VERSION ""

NS_ :

BS_:

BU_: WRCS SRS LECM1 ECUspare6 CIOM CCM

BO_ 2432663360 CIOM_Cab_05S: 13 CIOM
 SG_ PHTimerGUIEvCmd_Timer1StartDay_I : 32|4@1+ (1,0) [0|0] ""  CCM
 SG_ PHTimerGUIEvCmd_Timer1Recur_ISig : 24|4@1+ (1,0) [0|0] ""  CCM
 SG_ PHTimerGUIEvCmd_Timer1Temp_ISig_ : 8|5@1+ (1,0) [0|0] ""  CCM
 SG_ PHTimerGUIEvCmd_PhTimer3_cmd_ISi : 13|3@1+ (1,0) [0|0] ""  CCM
 SG_ PHTimerGUIEvCmd_Timer2StartDay_I : 36|4@1+ (1,0) [0|0] ""  CCM
 SG_ PHTimerGUIEvCmd_Timer3StartDay_I : 40|4@1+ (1,0) [0|0] ""  CCM
 SG_ PHTimerGUIEvCmd_Timer2Hours_ISig : 48|8@1+ (1,0) [0|255] "h"  CCM
 SG_ PHTimerGUIEvCmd_Timer1Duration_I : 96|7@1+ (1,0) [0|127] "min"  CCM
 SG_ PHTimerGUIEvCmd_Timer3Hours_ISig : 88|8@1+ (1,0) [0|255] "h"  CCM
 SG_ PHTimerGUIEvCmd_PhTimer1_cmd_ISi : 5|3@1+ (1,0) [0|0] ""  CCM
 SG_ PHTimerGUIEvCmd_PhTimer2_cmd_ISi : 21|3@1+ (1,0) [0|0] ""  CCM
 SG_ PHTimerGUIEvCmd_Timer2Recur_ISig : 44|4@1+ (1,0) [0|0] ""  CCM
 SG_ PHTimerGUIEvCmd_Timer3Recur_ISig : 28|4@1+ (1,0) [0|0] ""  CCM
 SG_ PHTimerGUIEvCmd_Timer2Minutes_IS : 72|8@1+ (1,0) [0|255] "min"  CCM
 SG_ PHTimerGUIEvCmd_Timer2Temp_ISig_ : 16|5@1+ (1,0) [0|0] ""  CCM
 SG_ PHTimerGUIEvCmd_Timer1Hours_ISig : 56|8@1+ (1,0) [0|255] "h"  CCM
 SG_ PHTimerGUIEvCmd_Timer3Temp_ISig_ : 0|5@1+ (1,0) [0|0] ""  CCM
 SG_ PHTimerGUIEvCmd_Timer3Minutes_IS : 64|8@1+ (1,0) [0|255] "min"  CCM
 SG_ PHTimerGUIEvCmd_Timer1Minutes_IS : 80|8@1+ (1,0) [0|255] "min"  CCM

BO_ 2432663361 CIOM_Cab_05P_FCM: 8 CCM
 SG_ CIOM_Cab_05P_FCS : 0|64@1+ (1,0) [0|1] ""  CIOM

BO_ 2432657472 CIOM_Cab_04S: 11 CIOM
 SG_ EngTimerGUIEvCmd_Timer3Hours_ISi : 56|8@1+ (1,0) [0|255] "h"  CCM
 SG_ EngTimerGUIEvCmd_EhTimer3_cmd_IS : 24|3@1+ (1,0) [0|0] ""  CCM
 SG_ EngTimerGUIEvCmd_Timer2Recur_ISi : 12|4@1+ (1,0) [0|0] ""  CCM
 SG_ EngTimerGUIEvCmd_EhTimer1_cmd_IS : 32|3@1+ (1,0) [0|0] ""  CCM
 SG_ EngTimerGUIEvCmd_Timer1StartDay_ : 4|4@1+ (1,0) [0|0] ""  CCM
 SG_ EngTimerGUIEvCmd_Timer3Recur_ISi : 8|4@1+ (1,0) [0|0] ""  CCM
 SG_ EngTimerGUIEvCmd_Timer2Hours_ISi : 80|8@1+ (1,0) [0|255] "h"  CCM
 SG_ EngTimerGUIEvCmd_Timer2StartDay_ : 16|4@1+ (1,0) [0|0] ""  CCM
 SG_ EngTimerGUIEvCmd_Timer1Minutes_I : 72|8@1+ (1,0) [0|255] "min"  CCM
 SG_ EngTimerGUIEvCmd_Timer1Hours_ISi : 48|8@1+ (1,0) [0|255] "h"  CCM
 SG_ EngTimerGUIEvCmd_Timer2Minutes_I : 40|8@1+ (1,0) [0|255] "min"  CCM
 SG_ EngTimerGUIEvCmd_Timer1Recur_ISi : 0|4@1+ (1,0) [0|0] ""  CCM
 SG_ EngTimerGUIEvCmd_Timer3StartDay_ : 20|4@1+ (1,0) [0|0] ""  CCM
 SG_ EngTimerGUIEvCmd_EhTimer2_cmd_IS : 27|3@1+ (1,0) [0|0] ""  CCM
 SG_ EngTimerGUIEvCmd_Timer3Minutes_I : 64|8@1+ (1,0) [0|255] "min"  CCM

BO_ 2432657473 CIOM_Cab_04P_FCM: 8 CCM
 SG_ CIOM_Cab_04P_FCS : 0|64@1+ (1,0) [0|1] ""  CIOM

BO_ 2432651584 CIOM_Cab_03P: 8 CIOM
 SG_ ParkHeaterTimerReleased_stat_ISi : 58|2@1+ (1,0) [0|0] ""  CCM
 SG_ Washing_HMI_rqst_ISig_5 : 46|2@1+ (1,0) [0|0] ""  CCM
 SG_ BunkH2ParkHeater_ButtonStatus : 54|2@1+ (1,0) [0|0] ""  CCM
 SG_ BunkBTempDec_ButtonStatus : 60|2@1+ (1,0) [0|0] ""  CCM
 SG_ BunkH2TempDec_ButtonStatus : 56|2@1+ (1,0) [0|0] ""  CCM
 SG_ BunkH2PHTimer_rqst_StartTimeMin : 8|8@1+ (1,0) [0|255] "min"  CCM
 SG_ BunkH2PHTimer_rqst_DurnTimeMin : 32|8@1+ (1,0) [0|255] "min"  CCM
 SG_ BunkBParkHeater_ButtonStatus : 48|2@1+ (1,0) [0|0] ""  CCM
 SG_ BunkH2PHTimer_rqst_StartTimeHr : 24|8@1+ (1,0) [0|255] "h"  CCM
 SG_ BunkH2PHTimer_rqst_DurnTimeHr : 16|8@1+ (1,0) [0|255] "h"  CCM
 SG_ BunkBTempInc_ButtonStatus : 42|2@1+ (1,0) [0|0] ""  CCM
 SG_ AudioSystemStatus_ISig_5 : 40|2@1+ (1,0) [0|0] ""  LECM1
 SG_ ParkingHeaterCleaning_cmd_ISig_5 : 52|2@1+ (1,0) [0|0] ""  CCM
 SG_ PtosStatus_ISig_5 : 44|2@1+ (1,0) [0|0] ""  CCM
 SG_ PtosStatus_UB_ISig_5 : 62|1@1+ (1,0) [0|0] ""  CCM
 SG_ BunkB1ParkHeaterBtn_stat : 50|2@1+ (1,0) [0|0] ""  CCM
 SG_ BunkH2PHTimer_rqst_Timer_cmd : 0|3@1+ (1,0) [0|0] ""  CCM

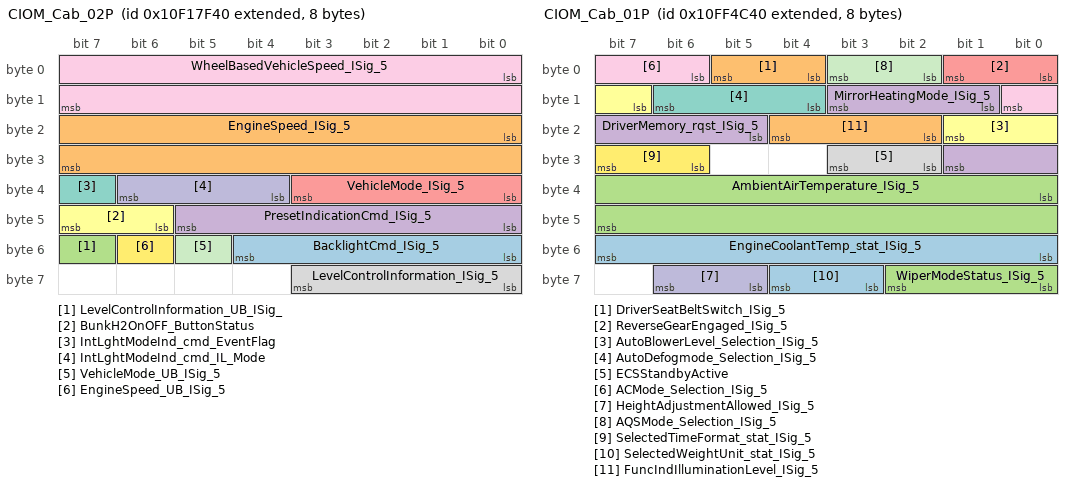
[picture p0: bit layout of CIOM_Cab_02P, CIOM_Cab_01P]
BO_ 2431745856 CIOM_Cab_02P: 8 CIOM
 SG_ BacklightCmd_ISig_5 : 48|5@1+ (1,0) [0|0] ""  CCM
 SG_ EngineSpeed_ISig_5 : 16|16@1+ (0.125,0) [0|8191.875] "rpm"  WRCS,CCM,SRS
 SG_ LevelControlInformation_UB_ISig_ : 55|1@1+ (1,0) [0|0] ""  WRCS
 SG_ PresetIndicationCmd_ISig_5 : 40|6@1+ (1,0) [0|63] "Enumeration"  LECM1
 SG_ VehicleMode_ISig_5 : 32|4@1+ (1,0) [0|0] ""  WRCS,LECM1,CCM,SRS
 SG_ BunkH2OnOFF_ButtonStatus : 46|2@1+ (1,0) [0|0] ""  CCM
 SG_ IntLghtModeInd_cmd_EventFlag : 39|1@1+ (1,0) [0|0] ""  LECM1
 SG_ LevelControlInformation_ISig_5 : 56|4@1+ (1,0) [0|0] ""  WRCS
 SG_ WheelBasedVehicleSpeed_ISig_5 : 0|16@1+ (0.00390625,0) [0|255.99609375] "Km_per_h"  CCM,SRS,WRCS
 SG_ IntLghtModeInd_cmd_IL_Mode : 36|3@1+ (1,0) [0|0] ""  LECM1
 SG_ VehicleMode_UB_ISig_5 : 53|1@1+ (1,0) [0|0] ""  CCM,WRCS,SRS,LECM1
 SG_ EngineSpeed_UB_ISig_5 : 54|1@1+ (1,0) [0|0] ""  CCM,SRS,WRCS

BO_ 2432650304 CIOM_Cab_01P: 8 CIOM
 SG_ EngineCoolantTemp_stat_ISig_5 : 48|8@1+ (1,-40) [-40|215] "DegreeC"  CCM
 SG_ DriverSeatBeltSwitch_ISig_5 : 4|2@1+ (1,0) [0|0] ""  SRS
 SG_ AmbientAirTemperature_ISig_5 : 32|16@1+ (0.03125,-273) [-273|1774.96875] "DegreeC"  LECM1,CCM,WRCS,SRS
 SG_ DriverMemory_rqst_ISig_5 : 21|5@1+ (1,0) [0|0] ""  CCM
 SG_ ReverseGearEngaged_ISig_5 : 0|2@1+ (1,0) [0|0] ""  CCM
 SG_ AutoBlowerLevel_Selection_ISig_5 : 15|3@1+ (1,0) [0|0] ""  CCM
 SG_ AutoDefogmode_Selection_ISig_5 : 12|3@1+ (1,0) [0|0] ""  CCM
 SG_ ECSStandbyActive : 26|2@1+ (1,0) [0|0] ""  WRCS
 SG_ ACMode_Selection_ISig_5 : 6|3@1+ (1,0) [0|0] ""  CCM
 SG_ HeightAdjustmentAllowed_ISig_5 : 61|2@1+ (1,0) [0|0] ""  WRCS
 SG_ AQSMode_Selection_ISig_5 : 2|2@1+ (1,0) [0|0] ""  CCM
 SG_ SelectedTimeFormat_stat_ISig_5 : 30|2@1+ (1,0) [0|0] ""  LECM1
 SG_ SelectedWeightUnit_stat_ISig_5 : 59|2@1+ (1,0) [0|0] ""  WRCS
 SG_ FuncIndIlluminationLevel_ISig_5 : 18|3@1+ (1,0) [0|0] ""  CCM
 SG_ WiperModeStatus_ISig_5 : 56|3@1+ (1,0) [0|0] ""  CCM
 SG_ MirrorHeatingMode_ISig_5 : 9|3@1+ (1,0) [0|0] ""  CCM

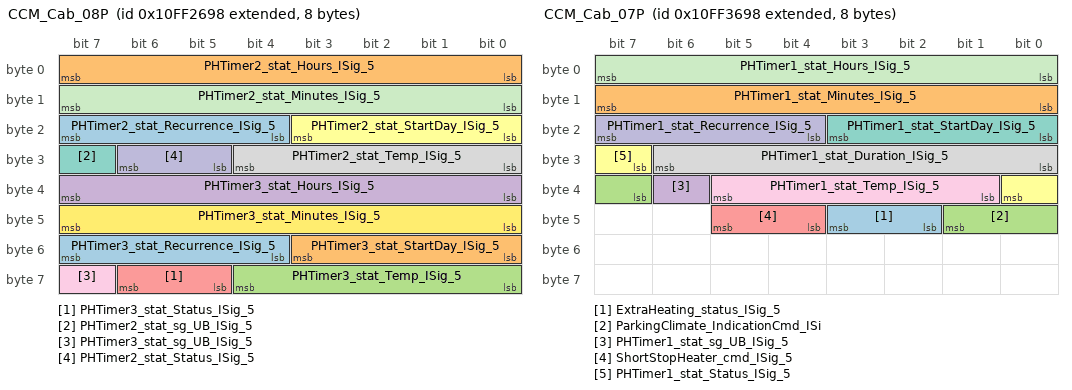
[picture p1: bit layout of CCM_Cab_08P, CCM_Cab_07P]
BO_ 2432640664 CCM_Cab_08P: 8 CCM
 SG_ PHTimer2_stat_Recurrence_ISig_5 : 20|4@1+ (1,0) [0|0] ""  CIOM,LECM1
 SG_ PHTimer2_stat_Hours_ISig_5 : 0|8@1+ (1,0) [0|255] "h"  LECM1,CIOM
 SG_ PHTimer3_stat_Temp_ISig_5 : 56|5@1+ (1,0) [0|0] ""  LECM1,CIOM
 SG_ PHTimer3_stat_Hours_ISig_5 : 32|8@1+ (1,0) [0|255] "h"  CIOM,LECM1
 SG_ PHTimer3_stat_Status_ISig_5 : 61|2@1+ (1,0) [0|0] ""  CIOM,LECM1
 SG_ PHTimer2_stat_StartDay_ISig_5 : 16|4@1+ (1,0) [0|0] ""  CIOM,LECM1
 SG_ PHTimer2_stat_sg_UB_ISig_5 : 31|1@1+ (1,0) [0|0] ""  CIOM,LECM1
 SG_ PHTimer2_stat_Temp_ISig_5 : 24|5@1+ (1,0) [0|0] ""  CIOM,LECM1
 SG_ PHTimer3_stat_sg_UB_ISig_5 : 63|1@1+ (1,0) [0|0] ""  LECM1,CIOM
 SG_ PHTimer2_stat_Status_ISig_5 : 29|2@1+ (1,0) [0|0] ""  LECM1,CIOM
 SG_ PHTimer2_stat_Minutes_ISig_5 : 8|8@1+ (1,0) [0|255] "min"  LECM1,CIOM
 SG_ PHTimer3_stat_Minutes_ISig_5 : 40|8@1+ (1,0) [0|255] "min"  CIOM,LECM1
 SG_ PHTimer3_stat_Recurrence_ISig_5 : 52|4@1+ (1,0) [0|0] ""  LECM1,CIOM
 SG_ PHTimer3_stat_StartDay_ISig_5 : 48|4@1+ (1,0) [0|0] ""  CIOM,LECM1

BO_ 2432644760 CCM_Cab_07P: 8 CCM
 SG_ ExtraHeating_status_ISig_5 : 42|2@1+ (1,0) [0|0] ""  CIOM
 SG_ PHTimer1_stat_Minutes_ISig_5 : 8|8@1+ (1,0) [0|255] "min"  LECM1,CIOM
 SG_ ParkingClimate_IndicationCmd_ISi : 39|3@1+ (1,0) [0|0] ""  CIOM
 SG_ PHTimer1_stat_sg_UB_ISig_5 : 38|1@1+ (1,0) [0|0] ""  LECM1,CIOM
 SG_ ShortStopHeater_cmd_ISig_5 : 44|2@1+ (1,0) [0|0] ""  CIOM
 SG_ PHTimer1_stat_Status_ISig_5 : 31|2@1+ (1,0) [0|0] ""  LECM1,CIOM
 SG_ PHTimer1_stat_StartDay_ISig_5 : 16|4@1+ (1,0) [0|0] ""  LECM1,CIOM
 SG_ PHTimer1_stat_Duration_ISig_5 : 24|7@1+ (1,0) [0|127] "min"  LECM1,CIOM
 SG_ PHTimer1_stat_Temp_ISig_5 : 33|5@1+ (1,0) [0|0] ""  LECM1,CIOM
 SG_ PHTimer1_stat_Recurrence_ISig_5 : 20|4@1+ (1,0) [0|0] ""  CIOM,LECM1
 SG_ PHTimer1_stat_Hours_ISig_5 : 0|8@1+ (1,0) [0|255] "h"  LECM1,CIOM

BO_ 2432645496 CCM_Cab_06P: 8 CCM
 SG_ AcCoolantPumpEngagementRequest_I : 24|8@1+ (0.4,0) [0|102] "Percent"  CIOM

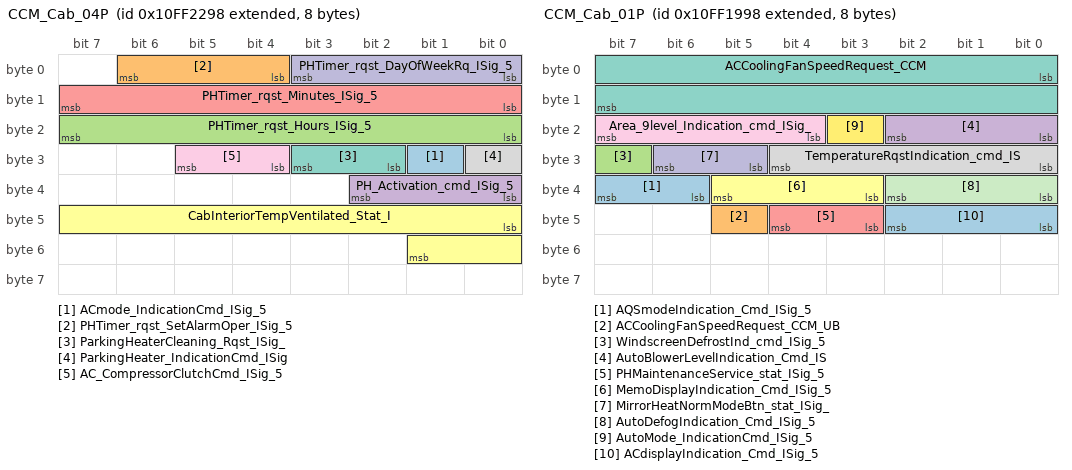
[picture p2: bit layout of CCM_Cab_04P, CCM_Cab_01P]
BO_ 2432639640 CCM_Cab_04P: 8 CCM
 SG_ ACmode_IndicationCmd_ISig_5 : 25|1@1+ (1,0) [0|0] ""  CIOM
 SG_ PHTimer_rqst_SetAlarmOper_ISig_5 : 4|3@1+ (1,0) [0|0] ""  CIOM
 SG_ PHTimer_rqst_Hours_ISig_5 : 16|8@1+ (1,0) [0|255] "h"  CIOM
 SG_ PH_Activation_cmd_ISig_5 : 32|3@1+ (1,0) [0|0] ""  CIOM
 SG_ PHTimer_rqst_Minutes_ISig_5 : 8|8@1+ (1,0) [0|255] "min"  CIOM
 SG_ CabInteriorTempVentilated_Stat_I : 40|10@1+ (0.125,-40) [-40|87.875] "DegreeC"  CIOM
 SG_ ParkingHeaterCleaning_Rqst_ISig_ : 26|2@1+ (1,0) [0|0] ""  CIOM
 SG_ ParkingHeater_IndicationCmd_ISig : 24|1@1+ (1,0) [0|0] ""  LECM1,CIOM
 SG_ AC_CompressorClutchCmd_ISig_5 : 28|2@1+ (1,0) [0|0] ""  CIOM
 SG_ PHTimer_rqst_DayOfWeekRq_ISig_5 : 0|4@1+ (1,0) [0|0] ""  CIOM

BO_ 2432633753 CCM_Cab_03P_FCM: 8 CIOM
 SG_ CCM_Cab_03P_FCS : 0|64@1+ (1,0) [0|1] ""  CCM

BO_ 2432633752 CCM_Cab_03P: 10 CCM
 SG_ EngineTimer_stat_Timer2StartDay_ : 16|4@1+ (1,0) [0|0] ""  CIOM
 SG_ EngineTimer_stat_Timer1Recurr_IS : 0|4@1+ (1,0) [0|0] ""  CIOM
 SG_ EngineTimer_stat_Timer3Hours_ISi : 32|8@1+ (1,0) [0|255] "h"  CIOM
 SG_ EngineTimer_stat_Timer2Minutes_I : 64|8@1+ (1,0) [0|255] "min"  CIOM
 SG_ EngineTimer_stat_Timer2Recurr_IS : 4|4@1+ (1,0) [0|0] ""  CIOM
 SG_ EngineTimer_stat_Timer1Hours_ISi : 40|8@1+ (1,0) [0|255] "h"  CIOM
 SG_ EngineTimer_stat_Timer3Minutes_I : 56|8@1+ (1,0) [0|255] "min"  CIOM
 SG_ EngineTimer_stat_Timer1Minutes_I : 24|8@1+ (1,0) [0|255] "min"  CIOM
 SG_ EngineTimer_stat_Timer3StartDay_ : 20|4@1+ (1,0) [0|0] ""  CIOM
 SG_ EngineTimer_stat_sg_UB_ISig_5 : 78|1@1+ (1,0) [0|0] ""  CIOM
 SG_ EngineTimer_stat_Timer2_Status_I : 74|2@1+ (1,0) [0|0] ""  CIOM
 SG_ EngineTimer_stat_Timer1StartDay_ : 12|4@1+ (1,0) [0|0] ""  CIOM
 SG_ EngineTimer_stat_Timer2Hours_ISi : 48|8@1+ (1,0) [0|255] "h"  CIOM
 SG_ EngineTimer_stat_Timer3_Status_I : 76|2@1+ (1,0) [0|0] ""  CIOM
 SG_ EngineTimer_stat_Timer3Recurr_IS : 8|4@1+ (1,0) [0|0] ""  CIOM
 SG_ EngineTimer_stat_Timer1_Status_I : 72|2@1+ (1,0) [0|0] ""  CIOM

BO_ 2432637336 CCM_Cab_01P: 8 CCM
 SG_ AQSmodeIndication_Cmd_ISig_5 : 38|2@1+ (1,0) [0|0] ""  CIOM
 SG_ ACCoolingFanSpeedRequest_CCM_UB : 45|1@1+ (1,0) [0|0] ""  CIOM
 SG_ WindscreenDefrostInd_cmd_ISig_5 : 31|1@1+ (1,0) [0|0] ""  CIOM
 SG_ AutoBlowerLevelIndication_Cmd_IS : 16|3@1+ (1,0) [0|0] ""  CIOM
 SG_ PHMaintenanceService_stat_ISig_5 : 43|2@1+ (1,0) [0|0] ""  CIOM
 SG_ MemoDisplayIndication_Cmd_ISig_5 : 35|3@1+ (1,0) [0|0] ""  CIOM
 SG_ ACCoolingFanSpeedRequest_CCM : 0|16@1+ (1,0) [0|65535] "rpm"  CIOM
 SG_ TemperatureRqstIndication_cmd_IS : 24|5@1+ (1,0) [0|0] ""  LECM1,CIOM
 SG_ Area_9level_Indication_cmd_ISig_ : 20|4@1+ (1,0) [0|0] ""  CIOM
 SG_ MirrorHeatNormModeBtn_stat_ISig_ : 29|2@1+ (1,0) [0|0] ""  CIOM
 SG_ AutoDefogIndication_Cmd_ISig_5 : 32|3@1+ (1,0) [0|0] ""  CIOM
 SG_ AutoMode_IndicationCmd_ISig_5 : 19|1@1+ (1,0) [0|0] ""  CIOM
 SG_ ACdisplayIndication_Cmd_ISig_5 : 40|3@1+ (1,0) [0|0] ""  CIOM

BO_ 2633994283 AnmMsg_WRCS_CabSubnet: 4 WRCS
 SG_ AnmSig_WRCS_CabSubnet : 0|32@1+ (1,0) [0|4294967295] ""  ECUspare6,LECM1,CCM,SRS,CIOM

BO_ 2633994282 AnmMsg_SRS_CabSubnet: 4 SRS
 SG_ AnmSig_SRS_CabSubnet : 0|32@1+ (1,0) [0|4294967295] ""  CIOM,LECM1,WRCS,CCM,ECUspare6

BO_ 2633994280 AnmMsg_LECM1_CabSubnet: 4 LECM1
 SG_ AnmSig_LECM1_CabSubnet : 0|32@1+ (1,0) [0|4294967295] ""  SRS,WRCS,CCM,ECUspare6,CIOM

BO_ 2633994320 AnmMsg_ECUspare6_CabSubnet: 4 ECUspare6
 SG_ AnmSig_ECUspare6_CabSubnet : 0|32@1+ (1,0) [0|4294967295] ""  SRS,LECM1,CCM,WRCS,CIOM

BO_ 2633994278 AnmMsg_CIOM_CabSubnet: 4 CIOM
 SG_ AnmSig_CIOM_CabSubnet : 0|32@1+ (1,0) [0|4294967295] ""  ECUspare6,WRCS,LECM1,CCM,SRS

BO_ 2633994277 AnmMsg_CCM_CabSubnet: 4 CCM
 SG_ AnmSig_CCM_CabSubnet : 0|32@1+ (1,0) [0|4294967295] ""  LECM1,CIOM,SRS,ECUspare6,WRCS

CM_ SG_ 2432663360 PHTimerGUIEvCmd_Timer2Hours_ISig "254 Error ; 255 Not available";
CM_ SG_ 2432663360 PHTimerGUIEvCmd_Timer1Duration_I "126 Error ; 127 Not available";
CM_ SG_ 2432663360 PHTimerGUIEvCmd_Timer3Hours_ISig "254 Error ; 255 Not available";
CM_ SG_ 2432663360 PHTimerGUIEvCmd_Timer2Minutes_IS "254 Error ; 255 Not available";
CM_ SG_ 2432663360 PHTimerGUIEvCmd_Timer1Hours_ISig "254 Error ; 255 Not available";
CM_ SG_ 2432663360 PHTimerGUIEvCmd_Timer3Minutes_IS "254 Error ; 255 Not available";
CM_ SG_ 2432663360 PHTimerGUIEvCmd_Timer1Minutes_IS "254 Error ; 255 Not available";
CM_ SG_ 2432657472 EngTimerGUIEvCmd_Timer3Hours_ISi "254 Error ; 255 Not available";
CM_ SG_ 2432657472 EngTimerGUIEvCmd_Timer2Hours_ISi "254 Error ; 255 Not available";
CM_ SG_ 2432657472 EngTimerGUIEvCmd_Timer1Minutes_I "254 Error ; 255 Not available";
CM_ SG_ 2432657472 EngTimerGUIEvCmd_Timer1Hours_ISi "254 Error ; 255 Not available";
CM_ SG_ 2432657472 EngTimerGUIEvCmd_Timer2Minutes_I "254 Error ; 255 Not available";
CM_ SG_ 2432657472 EngTimerGUIEvCmd_Timer3Minutes_I "254 Error ; 255 Not available";
CM_ SG_ 2432651584 BunkH2PHTimer_rqst_StartTimeMin "254 Error ; 255 Not available";
CM_ SG_ 2432651584 BunkH2PHTimer_rqst_DurnTimeMin "254 Error ; 255 Not available";
CM_ SG_ 2432651584 BunkH2PHTimer_rqst_StartTimeHr "254 Error ; 255 Not available";
CM_ SG_ 2432651584 BunkH2PHTimer_rqst_DurnTimeHr "254 Error ; 255 Not available";
CM_ SG_ 2431745856 EngineSpeed_ISig_5 "65024 - 65279 Error ; 65280 - 65535 Not available";
CM_ SG_ 2431745856 PresetIndicationCmd_ISig_5 "62 Error ; 63 Not Available";
CM_ SG_ 2431745856 WheelBasedVehicleSpeed_ISig_5 "65024 - 65279 Error ; 65280 - 65535 Not available";
CM_ SG_ 2432650304 EngineCoolantTemp_stat_ISig_5 "254 Error ; 255 Not available";
CM_ SG_ 2432650304 AmbientAirTemperature_ISig_5 "65024 - 65279 Error ; 65280 - 65535 Not available";
CM_ SG_ 2432640664 PHTimer2_stat_Hours_ISig_5 "254 Error ; 255 Not available";
CM_ SG_ 2432640664 PHTimer3_stat_Hours_ISig_5 "254 Error ; 255 Not available";
CM_ SG_ 2432640664 PHTimer2_stat_Minutes_ISig_5 "254 Error ; 255 Not available";
CM_ SG_ 2432640664 PHTimer3_stat_Minutes_ISig_5 "254 Error ; 255 Not available";
CM_ SG_ 2432644760 PHTimer1_stat_Minutes_ISig_5 "254 Error ; 255 Not available";
CM_ SG_ 2432644760 PHTimer1_stat_Duration_ISig_5 "126 Error ; 127 Not available";
CM_ SG_ 2432644760 PHTimer1_stat_Hours_ISig_5 "254 Error ; 255 Not available";
CM_ SG_ 2432639640 PHTimer_rqst_Hours_ISig_5 "254 Error ; 255 Not available";
CM_ SG_ 2432639640 PHTimer_rqst_Minutes_ISig_5 "254 Error ; 255 Not available";
CM_ SG_ 2432639640 CabInteriorTempVentilated_Stat_I "1022 Error; 1023 Not Available";
CM_ SG_ 2432633752 EngineTimer_stat_Timer3Hours_ISi "254 Error ; 255 Not available";
CM_ SG_ 2432633752 EngineTimer_stat_Timer2Minutes_I "254 Error ; 255 Not available";
CM_ SG_ 2432633752 EngineTimer_stat_Timer1Hours_ISi "254 Error ; 255 Not available";
CM_ SG_ 2432633752 EngineTimer_stat_Timer3Minutes_I "254 Error ; 255 Not available";
CM_ SG_ 2432633752 EngineTimer_stat_Timer1Minutes_I "254 Error ; 255 Not available";
CM_ SG_ 2432633752 EngineTimer_stat_Timer2Hours_ISi "254 Error ; 255 Not available";
BA_DEF_ BO_  "GenMsgStartDelayTime" INT 0 0;
BA_DEF_ BO_  "GenMsgDelayTime" INT 0 0;
BA_DEF_ BO_  "GenMsgCycleTime" INT 0 0;
BA_DEF_ BO_  "GenMsgSendType" ENUM  "Cyclic","NotUsed","NotUsed","NotUsed","NotUsed","NotUsed","NotUsed","IfActive","NoMsgSendType","NotUsed";
BA_DEF_ SG_  "GenSigStartValue" INT 0 0;
BA_DEF_ SG_  "GenSigCycleTimeActive" INT 0 0;
BA_DEF_ SG_  "GenSigCycleTime" INT 0 0;
BA_DEF_ SG_  "GenSigSendType" ENUM  "Cyclic","OnWrite","OnWriteWithRepetition","OnChange","OnChangeWithRepetition","IfActive","IfActiveWithRepetition","NoSigSendType","NotUsed","NotUsed","NotUsed","NotUsed","NotUsed";
BA_DEF_ BO_  "VFrameFormat" ENUM  "StandardCAN","ExtendedCAN","reserved","J1939PG";
BA_DEF_ SG_  "SigType" ENUM  "Default","Range","RangeSigned","ASCII","Discrete","Control","ReferencePGN","DTC","StringDelimiter","StringLength","StringLengthControl";
BA_DEF_ SG_  "SeToolVersion_SIGNAL" STRING ;
BA_DEF_ SG_  "SeToolUniqueID_SIGNAL" STRING ;
BA_DEF_ SG_  "SeToolOwnerSigGroup_SIGNAL" STRING ;
BA_DEF_ SG_  "SeToolOwnerSigGroupID_SIGNAL" STRING ;
BA_DEF_ SG_  "SeToolName_SIGNAL" STRING ;
BA_DEF_ SG_  "SeToolItemID_SIGNAL" STRING ;
BA_DEF_ SG_  "SeToolAncestorID_SIGNAL" STRING ;
BA_DEF_ BO_  "NmAsrMessage" ENUM  "No","Yes";
BA_DEF_ SG_  "NeedsUpdateBit" ENUM  "No","Yes";
BA_DEF_ SG_  "MmAnSignal" ENUM  "No","Yes";
BA_DEF_ SG_  "GenSigMaxLatency" INT 0 65535;
BA_DEF_ SG_  "GenSigILSupport" ENUM  "Yes","No";
BA_DEF_ BO_  "GenMsgRequestable" INT 0 1;
BA_DEF_ BO_  "GenMsgILSupport" ENUM  "No","Yes";
BA_DEF_ BO_  "DiagUUDTResponse" ENUM  "No","Yes";
BA_DEF_ BO_  "DiagState" ENUM  "No","Yes";
BA_DEF_ BO_  "DiagResponse" ENUM  "No","Yes";
BA_DEF_ BO_  "DiagRequest" ENUM  "No","Yes";
BA_DEF_ BO_  "DiagConnection" HEX 0 65535;
BA_DEF_ BO_  "CanTpSTmin" INT 0 255;
BA_DEF_ BO_  "CanTpFcFrameId" HEX 0 2147483647;
BA_DEF_ BO_  "CanTpBs" INT 0 255;
BA_DEF_ SG_  "SystemSignalLongSymbol" STRING ;
BA_DEF_REL_ BU_SG_REL_  "GenSigTimeoutTime" INT 0 65535;
BA_DEF_REL_ BU_SG_REL_  "GenSigFirstTimeoutTime" INT 0 65535;
BA_DEF_DEF_  "GenMsgStartDelayTime" 0;
BA_DEF_DEF_  "GenMsgDelayTime" 0;
BA_DEF_DEF_  "GenMsgCycleTime" 0;
BA_DEF_DEF_  "GenMsgSendType" "Cyclic";
BA_DEF_DEF_  "GenSigStartValue" 0;
BA_DEF_DEF_  "GenSigCycleTimeActive" 0;
BA_DEF_DEF_  "GenSigCycleTime" 0;
BA_DEF_DEF_  "GenSigSendType" "Cyclic";
BA_DEF_DEF_  "VFrameFormat" "ExtendedCAN";
BA_DEF_DEF_  "SigType" "Default";
BA_DEF_DEF_  "SeToolVersion_SIGNAL" "";
BA_DEF_DEF_  "SeToolUniqueID_SIGNAL" "";
BA_DEF_DEF_  "SeToolOwnerSigGroup_SIGNAL" "";
BA_DEF_DEF_  "SeToolOwnerSigGroupID_SIGNAL" "";
BA_DEF_DEF_  "SeToolName_SIGNAL" "";
BA_DEF_DEF_  "SeToolItemID_SIGNAL" "";
BA_DEF_DEF_  "SeToolAncestorID_SIGNAL" "";
BA_DEF_DEF_  "NmAsrMessage" "No";
BA_DEF_DEF_  "NeedsUpdateBit" "No";
BA_DEF_DEF_  "MmAnSignal" "No";
BA_DEF_DEF_  "GenSigMaxLatency" 0;
BA_DEF_DEF_  "GenSigILSupport" "Yes";
BA_DEF_DEF_  "GenMsgRequestable" 1;
BA_DEF_DEF_  "GenMsgILSupport" "Yes";
BA_DEF_DEF_  "DiagUUDTResponse" "No";
BA_DEF_DEF_  "DiagState" "No";
BA_DEF_DEF_  "DiagResponse" "No";
BA_DEF_DEF_  "DiagRequest" "No";
BA_DEF_DEF_  "DiagConnection" 0;
BA_DEF_DEF_  "CanTpSTmin" 0;
BA_DEF_DEF_  "CanTpFcFrameId" 2147483647;
BA_DEF_DEF_  "CanTpBs" 255;
BA_DEF_DEF_REL_ "GenSigTimeoutTime" 0;
BA_DEF_DEF_REL_ "GenSigFirstTimeoutTime" 0;
BA_DEF_DEF_  "SystemSignalLongSymbol" "";
BA_ "CanTpFcFrameId" BO_ 2432663360 285179713;
BA_ "GenMsgSendType" BO_ 2432663360 8;
BA_ "GenMsgILSupport" BO_ 2432663361 0;
BA_ "GenMsgSendType" BO_ 2432663361 8;
BA_ "CanTpFcFrameId" BO_ 2432657472 285173825;
BA_ "GenMsgSendType" BO_ 2432657472 8;
BA_ "GenMsgILSupport" BO_ 2432657473 0;
BA_ "GenMsgSendType" BO_ 2432657473 8;
BA_ "GenMsgCycleTime" BO_ 2432651584 20;
BA_ "GenMsgStartDelayTime" BO_ 2432651584 15;
BA_ "GenMsgCycleTime" BO_ 2431745856 10;
BA_ "GenMsgCycleTime" BO_ 2432650304 20;
BA_ "GenMsgCycleTime" BO_ 2432640664 50;
BA_ "GenMsgCycleTime" BO_ 2432644760 50;
BA_ "GenMsgCycleTime" BO_ 2432645496 20;
BA_ "GenMsgCycleTime" BO_ 2432639640 20;
BA_ "GenMsgILSupport" BO_ 2432633753 0;
BA_ "GenMsgSendType" BO_ 2432633753 8;
BA_ "CanTpFcFrameId" BO_ 2432633752 285150105;
BA_ "GenMsgCycleTime" BO_ 2432633752 50;
BA_ "GenMsgStartDelayTime" BO_ 2432633752 5;
BA_ "GenMsgCycleTime" BO_ 2432637336 20;
BA_ "GenMsgStartDelayTime" BO_ 2432637336 5;
BA_ "GenMsgCycleTime" BO_ 2633994283 100;
BA_ "GenMsgCycleTime" BO_ 2633994282 100;
BA_ "GenMsgCycleTime" BO_ 2633994280 100;
BA_ "GenMsgCycleTime" BO_ 2633994320 100;
BA_ "GenMsgCycleTime" BO_ 2633994278 100;
BA_ "GenMsgStartDelayTime" BO_ 2633994278 10;
BA_ "GenMsgCycleTime" BO_ 2633994277 100;
BA_ "GenMsgStartDelayTime" BO_ 2633994277 10;
BA_ "GenSigSendType" SG_ 2432663360 PHTimerGUIEvCmd_Timer1StartDay_I 1;
BA_ "GenSigCycleTime" SG_ 2432663360 PHTimerGUIEvCmd_Timer1StartDay_I 100;
BA_ "GenSigCycleTimeActive" SG_ 2432663360 PHTimerGUIEvCmd_Timer1StartDay_I 100;
BA_ "GenSigStartValue" SG_ 2432663360 PHTimerGUIEvCmd_Timer1StartDay_I 15;
BA_ "GenSigMaxLatency" SG_ 2432663360 PHTimerGUIEvCmd_Timer1StartDay_I 26;
BA_ "SystemSignalLongSymbol" SG_ 2432663360 PHTimerGUIEvCmd_Timer1StartDay_I "PHTimerGUIEvCmd_Timer1StartDay_ISig_5";
BA_ "GenSigSendType" SG_ 2432663360 PHTimerGUIEvCmd_Timer1Recur_ISig 1;
BA_ "GenSigCycleTime" SG_ 2432663360 PHTimerGUIEvCmd_Timer1Recur_ISig 100;
BA_ "GenSigCycleTimeActive" SG_ 2432663360 PHTimerGUIEvCmd_Timer1Recur_ISig 100;
BA_ "GenSigStartValue" SG_ 2432663360 PHTimerGUIEvCmd_Timer1Recur_ISig 15;
BA_ "GenSigMaxLatency" SG_ 2432663360 PHTimerGUIEvCmd_Timer1Recur_ISig 26;
BA_ "SystemSignalLongSymbol" SG_ 2432663360 PHTimerGUIEvCmd_Timer1Recur_ISig "PHTimerGUIEvCmd_Timer1Recur_ISig_5";
BA_ "GenSigSendType" SG_ 2432663360 PHTimerGUIEvCmd_Timer1Temp_ISig_ 1;
BA_ "GenSigCycleTime" SG_ 2432663360 PHTimerGUIEvCmd_Timer1Temp_ISig_ 100;
BA_ "GenSigCycleTimeActive" SG_ 2432663360 PHTimerGUIEvCmd_Timer1Temp_ISig_ 100;
BA_ "GenSigStartValue" SG_ 2432663360 PHTimerGUIEvCmd_Timer1Temp_ISig_ 31;
BA_ "GenSigMaxLatency" SG_ 2432663360 PHTimerGUIEvCmd_Timer1Temp_ISig_ 26;
BA_ "SystemSignalLongSymbol" SG_ 2432663360 PHTimerGUIEvCmd_Timer1Temp_ISig_ "PHTimerGUIEvCmd_Timer1Temp_ISig_5";
BA_ "GenSigSendType" SG_ 2432663360 PHTimerGUIEvCmd_PhTimer3_cmd_ISi 1;
BA_ "GenSigCycleTime" SG_ 2432663360 PHTimerGUIEvCmd_PhTimer3_cmd_ISi 100;
BA_ "GenSigCycleTimeActive" SG_ 2432663360 PHTimerGUIEvCmd_PhTimer3_cmd_ISi 100;
BA_ "GenSigStartValue" SG_ 2432663360 PHTimerGUIEvCmd_PhTimer3_cmd_ISi 7;
BA_ "GenSigMaxLatency" SG_ 2432663360 PHTimerGUIEvCmd_PhTimer3_cmd_ISi 26;
BA_ "SystemSignalLongSymbol" SG_ 2432663360 PHTimerGUIEvCmd_PhTimer3_cmd_ISi "PHTimerGUIEvCmd_PhTimer3_cmd_ISig_5";
BA_ "GenSigSendType" SG_ 2432663360 PHTimerGUIEvCmd_Timer2StartDay_I 1;
BA_ "GenSigCycleTime" SG_ 2432663360 PHTimerGUIEvCmd_Timer2StartDay_I 100;
BA_ "GenSigCycleTimeActive" SG_ 2432663360 PHTimerGUIEvCmd_Timer2StartDay_I 100;
BA_ "GenSigStartValue" SG_ 2432663360 PHTimerGUIEvCmd_Timer2StartDay_I 15;
BA_ "GenSigMaxLatency" SG_ 2432663360 PHTimerGUIEvCmd_Timer2StartDay_I 26;
BA_ "SystemSignalLongSymbol" SG_ 2432663360 PHTimerGUIEvCmd_Timer2StartDay_I "PHTimerGUIEvCmd_Timer2StartDay_ISig_5";
BA_ "GenSigSendType" SG_ 2432663360 PHTimerGUIEvCmd_Timer3StartDay_I 1;
BA_ "GenSigCycleTime" SG_ 2432663360 PHTimerGUIEvCmd_Timer3StartDay_I 100;
BA_ "GenSigCycleTimeActive" SG_ 2432663360 PHTimerGUIEvCmd_Timer3StartDay_I 100;
BA_ "GenSigStartValue" SG_ 2432663360 PHTimerGUIEvCmd_Timer3StartDay_I 15;
BA_ "GenSigMaxLatency" SG_ 2432663360 PHTimerGUIEvCmd_Timer3StartDay_I 26;
BA_ "SystemSignalLongSymbol" SG_ 2432663360 PHTimerGUIEvCmd_Timer3StartDay_I "PHTimerGUIEvCmd_Timer3StartDay_ISig_5";
BA_ "GenSigSendType" SG_ 2432663360 PHTimerGUIEvCmd_Timer2Hours_ISig 1;
BA_ "GenSigCycleTime" SG_ 2432663360 PHTimerGUIEvCmd_Timer2Hours_ISig 100;
BA_ "GenSigCycleTimeActive" SG_ 2432663360 PHTimerGUIEvCmd_Timer2Hours_ISig 100;
BA_ "GenSigStartValue" SG_ 2432663360 PHTimerGUIEvCmd_Timer2Hours_ISig 255;
BA_ "GenSigMaxLatency" SG_ 2432663360 PHTimerGUIEvCmd_Timer2Hours_ISig 26;
BA_ "SystemSignalLongSymbol" SG_ 2432663360 PHTimerGUIEvCmd_Timer2Hours_ISig "PHTimerGUIEvCmd_Timer2Hours_ISig_5";
BA_ "GenSigSendType" SG_ 2432663360 PHTimerGUIEvCmd_Timer1Duration_I 1;
BA_ "GenSigCycleTime" SG_ 2432663360 PHTimerGUIEvCmd_Timer1Duration_I 100;
BA_ "GenSigCycleTimeActive" SG_ 2432663360 PHTimerGUIEvCmd_Timer1Duration_I 100;
BA_ "GenSigStartValue" SG_ 2432663360 PHTimerGUIEvCmd_Timer1Duration_I 127;
BA_ "GenSigMaxLatency" SG_ 2432663360 PHTimerGUIEvCmd_Timer1Duration_I 26;
BA_ "SystemSignalLongSymbol" SG_ 2432663360 PHTimerGUIEvCmd_Timer1Duration_I "PHTimerGUIEvCmd_Timer1Duration_ISig_5";
BA_ "GenSigSendType" SG_ 2432663360 PHTimerGUIEvCmd_Timer3Hours_ISig 1;
BA_ "GenSigCycleTime" SG_ 2432663360 PHTimerGUIEvCmd_Timer3Hours_ISig 100;
BA_ "GenSigCycleTimeActive" SG_ 2432663360 PHTimerGUIEvCmd_Timer3Hours_ISig 100;
BA_ "GenSigStartValue" SG_ 2432663360 PHTimerGUIEvCmd_Timer3Hours_ISig 255;
BA_ "GenSigMaxLatency" SG_ 2432663360 PHTimerGUIEvCmd_Timer3Hours_ISig 26;
BA_ "SystemSignalLongSymbol" SG_ 2432663360 PHTimerGUIEvCmd_Timer3Hours_ISig "PHTimerGUIEvCmd_Timer3Hours_ISig_5";
BA_ "GenSigSendType" SG_ 2432663360 PHTimerGUIEvCmd_PhTimer1_cmd_ISi 1;
BA_ "GenSigCycleTime" SG_ 2432663360 PHTimerGUIEvCmd_PhTimer1_cmd_ISi 100;
BA_ "GenSigCycleTimeActive" SG_ 2432663360 PHTimerGUIEvCmd_PhTimer1_cmd_ISi 100;
BA_ "GenSigStartValue" SG_ 2432663360 PHTimerGUIEvCmd_PhTimer1_cmd_ISi 7;
BA_ "GenSigMaxLatency" SG_ 2432663360 PHTimerGUIEvCmd_PhTimer1_cmd_ISi 26;
BA_ "SystemSignalLongSymbol" SG_ 2432663360 PHTimerGUIEvCmd_PhTimer1_cmd_ISi "PHTimerGUIEvCmd_PhTimer1_cmd_ISig_5";
BA_ "GenSigSendType" SG_ 2432663360 PHTimerGUIEvCmd_PhTimer2_cmd_ISi 1;
BA_ "GenSigCycleTime" SG_ 2432663360 PHTimerGUIEvCmd_PhTimer2_cmd_ISi 100;
BA_ "GenSigCycleTimeActive" SG_ 2432663360 PHTimerGUIEvCmd_PhTimer2_cmd_ISi 100;
BA_ "GenSigStartValue" SG_ 2432663360 PHTimerGUIEvCmd_PhTimer2_cmd_ISi 7;
BA_ "GenSigMaxLatency" SG_ 2432663360 PHTimerGUIEvCmd_PhTimer2_cmd_ISi 26;
BA_ "SystemSignalLongSymbol" SG_ 2432663360 PHTimerGUIEvCmd_PhTimer2_cmd_ISi "PHTimerGUIEvCmd_PhTimer2_cmd_ISig_5";
BA_ "GenSigSendType" SG_ 2432663360 PHTimerGUIEvCmd_Timer2Recur_ISig 1;
BA_ "GenSigCycleTime" SG_ 2432663360 PHTimerGUIEvCmd_Timer2Recur_ISig 100;
BA_ "GenSigCycleTimeActive" SG_ 2432663360 PHTimerGUIEvCmd_Timer2Recur_ISig 100;
BA_ "GenSigStartValue" SG_ 2432663360 PHTimerGUIEvCmd_Timer2Recur_ISig 15;
BA_ "GenSigMaxLatency" SG_ 2432663360 PHTimerGUIEvCmd_Timer2Recur_ISig 26;
BA_ "SystemSignalLongSymbol" SG_ 2432663360 PHTimerGUIEvCmd_Timer2Recur_ISig "PHTimerGUIEvCmd_Timer2Recur_ISig_5";
BA_ "GenSigSendType" SG_ 2432663360 PHTimerGUIEvCmd_Timer3Recur_ISig 1;
BA_ "GenSigCycleTime" SG_ 2432663360 PHTimerGUIEvCmd_Timer3Recur_ISig 100;
BA_ "GenSigCycleTimeActive" SG_ 2432663360 PHTimerGUIEvCmd_Timer3Recur_ISig 100;
BA_ "GenSigStartValue" SG_ 2432663360 PHTimerGUIEvCmd_Timer3Recur_ISig 15;
BA_ "GenSigMaxLatency" SG_ 2432663360 PHTimerGUIEvCmd_Timer3Recur_ISig 26;
BA_ "SystemSignalLongSymbol" SG_ 2432663360 PHTimerGUIEvCmd_Timer3Recur_ISig "PHTimerGUIEvCmd_Timer3Recur_ISig_5";
BA_ "GenSigSendType" SG_ 2432663360 PHTimerGUIEvCmd_Timer2Minutes_IS 1;
BA_ "GenSigCycleTime" SG_ 2432663360 PHTimerGUIEvCmd_Timer2Minutes_IS 100;
BA_ "GenSigCycleTimeActive" SG_ 2432663360 PHTimerGUIEvCmd_Timer2Minutes_IS 100;
BA_ "GenSigStartValue" SG_ 2432663360 PHTimerGUIEvCmd_Timer2Minutes_IS 255;
BA_ "GenSigMaxLatency" SG_ 2432663360 PHTimerGUIEvCmd_Timer2Minutes_IS 26;
BA_ "SystemSignalLongSymbol" SG_ 2432663360 PHTimerGUIEvCmd_Timer2Minutes_IS "PHTimerGUIEvCmd_Timer2Minutes_ISig_5";
BA_ "GenSigSendType" SG_ 2432663360 PHTimerGUIEvCmd_Timer2Temp_ISig_ 1;
BA_ "GenSigCycleTime" SG_ 2432663360 PHTimerGUIEvCmd_Timer2Temp_ISig_ 100;
BA_ "GenSigCycleTimeActive" SG_ 2432663360 PHTimerGUIEvCmd_Timer2Temp_ISig_ 100;
BA_ "GenSigStartValue" SG_ 2432663360 PHTimerGUIEvCmd_Timer2Temp_ISig_ 31;
BA_ "GenSigMaxLatency" SG_ 2432663360 PHTimerGUIEvCmd_Timer2Temp_ISig_ 26;
BA_ "SystemSignalLongSymbol" SG_ 2432663360 PHTimerGUIEvCmd_Timer2Temp_ISig_ "PHTimerGUIEvCmd_Timer2Temp_ISig_5";
BA_ "GenSigSendType" SG_ 2432663360 PHTimerGUIEvCmd_Timer1Hours_ISig 1;
BA_ "GenSigCycleTime" SG_ 2432663360 PHTimerGUIEvCmd_Timer1Hours_ISig 100;
BA_ "GenSigCycleTimeActive" SG_ 2432663360 PHTimerGUIEvCmd_Timer1Hours_ISig 100;
BA_ "GenSigStartValue" SG_ 2432663360 PHTimerGUIEvCmd_Timer1Hours_ISig 255;
BA_ "GenSigMaxLatency" SG_ 2432663360 PHTimerGUIEvCmd_Timer1Hours_ISig 26;
BA_ "SystemSignalLongSymbol" SG_ 2432663360 PHTimerGUIEvCmd_Timer1Hours_ISig "PHTimerGUIEvCmd_Timer1Hours_ISig_5";
BA_ "GenSigSendType" SG_ 2432663360 PHTimerGUIEvCmd_Timer3Temp_ISig_ 1;
BA_ "GenSigCycleTime" SG_ 2432663360 PHTimerGUIEvCmd_Timer3Temp_ISig_ 100;
BA_ "GenSigCycleTimeActive" SG_ 2432663360 PHTimerGUIEvCmd_Timer3Temp_ISig_ 100;
BA_ "GenSigStartValue" SG_ 2432663360 PHTimerGUIEvCmd_Timer3Temp_ISig_ 31;
BA_ "GenSigMaxLatency" SG_ 2432663360 PHTimerGUIEvCmd_Timer3Temp_ISig_ 26;
BA_ "SystemSignalLongSymbol" SG_ 2432663360 PHTimerGUIEvCmd_Timer3Temp_ISig_ "PHTimerGUIEvCmd_Timer3Temp_ISig_5";
BA_ "GenSigSendType" SG_ 2432663360 PHTimerGUIEvCmd_Timer3Minutes_IS 1;
BA_ "GenSigCycleTime" SG_ 2432663360 PHTimerGUIEvCmd_Timer3Minutes_IS 100;
BA_ "GenSigCycleTimeActive" SG_ 2432663360 PHTimerGUIEvCmd_Timer3Minutes_IS 100;
BA_ "GenSigStartValue" SG_ 2432663360 PHTimerGUIEvCmd_Timer3Minutes_IS 255;
BA_ "GenSigMaxLatency" SG_ 2432663360 PHTimerGUIEvCmd_Timer3Minutes_IS 26;
BA_ "SystemSignalLongSymbol" SG_ 2432663360 PHTimerGUIEvCmd_Timer3Minutes_IS "PHTimerGUIEvCmd_Timer3Minutes_ISig_5";
BA_ "GenSigSendType" SG_ 2432663360 PHTimerGUIEvCmd_Timer1Minutes_IS 1;
BA_ "GenSigCycleTime" SG_ 2432663360 PHTimerGUIEvCmd_Timer1Minutes_IS 100;
BA_ "GenSigCycleTimeActive" SG_ 2432663360 PHTimerGUIEvCmd_Timer1Minutes_IS 100;
BA_ "GenSigStartValue" SG_ 2432663360 PHTimerGUIEvCmd_Timer1Minutes_IS 255;
BA_ "GenSigMaxLatency" SG_ 2432663360 PHTimerGUIEvCmd_Timer1Minutes_IS 26;
BA_ "SystemSignalLongSymbol" SG_ 2432663360 PHTimerGUIEvCmd_Timer1Minutes_IS "PHTimerGUIEvCmd_Timer1Minutes_ISig_5";
BA_ "GenSigSendType" SG_ 2432663361 CIOM_Cab_05P_FCS 7;
BA_ "GenSigSendType" SG_ 2432657472 EngTimerGUIEvCmd_Timer3Hours_ISi 1;
BA_ "GenSigCycleTime" SG_ 2432657472 EngTimerGUIEvCmd_Timer3Hours_ISi 100;
BA_ "GenSigCycleTimeActive" SG_ 2432657472 EngTimerGUIEvCmd_Timer3Hours_ISi 100;
BA_ "GenSigStartValue" SG_ 2432657472 EngTimerGUIEvCmd_Timer3Hours_ISi 255;
BA_ "GenSigMaxLatency" SG_ 2432657472 EngTimerGUIEvCmd_Timer3Hours_ISi 26;
BA_ "SystemSignalLongSymbol" SG_ 2432657472 EngTimerGUIEvCmd_Timer3Hours_ISi "EngTimerGUIEvCmd_Timer3Hours_ISig_5";
BA_ "GenSigSendType" SG_ 2432657472 EngTimerGUIEvCmd_EhTimer3_cmd_IS 1;
BA_ "GenSigCycleTime" SG_ 2432657472 EngTimerGUIEvCmd_EhTimer3_cmd_IS 100;
BA_ "GenSigCycleTimeActive" SG_ 2432657472 EngTimerGUIEvCmd_EhTimer3_cmd_IS 100;
BA_ "GenSigStartValue" SG_ 2432657472 EngTimerGUIEvCmd_EhTimer3_cmd_IS 7;
BA_ "GenSigMaxLatency" SG_ 2432657472 EngTimerGUIEvCmd_EhTimer3_cmd_IS 26;
BA_ "SystemSignalLongSymbol" SG_ 2432657472 EngTimerGUIEvCmd_EhTimer3_cmd_IS "EngTimerGUIEvCmd_EhTimer3_cmd_ISig_5";
BA_ "GenSigSendType" SG_ 2432657472 EngTimerGUIEvCmd_Timer2Recur_ISi 1;
BA_ "GenSigCycleTime" SG_ 2432657472 EngTimerGUIEvCmd_Timer2Recur_ISi 100;
BA_ "GenSigCycleTimeActive" SG_ 2432657472 EngTimerGUIEvCmd_Timer2Recur_ISi 100;
BA_ "GenSigStartValue" SG_ 2432657472 EngTimerGUIEvCmd_Timer2Recur_ISi 15;
BA_ "GenSigMaxLatency" SG_ 2432657472 EngTimerGUIEvCmd_Timer2Recur_ISi 26;
BA_ "SystemSignalLongSymbol" SG_ 2432657472 EngTimerGUIEvCmd_Timer2Recur_ISi "EngTimerGUIEvCmd_Timer2Recur_ISig_5";
BA_ "GenSigSendType" SG_ 2432657472 EngTimerGUIEvCmd_EhTimer1_cmd_IS 1;
BA_ "GenSigCycleTime" SG_ 2432657472 EngTimerGUIEvCmd_EhTimer1_cmd_IS 100;
BA_ "GenSigCycleTimeActive" SG_ 2432657472 EngTimerGUIEvCmd_EhTimer1_cmd_IS 100;
BA_ "GenSigStartValue" SG_ 2432657472 EngTimerGUIEvCmd_EhTimer1_cmd_IS 7;
BA_ "GenSigMaxLatency" SG_ 2432657472 EngTimerGUIEvCmd_EhTimer1_cmd_IS 26;
BA_ "SystemSignalLongSymbol" SG_ 2432657472 EngTimerGUIEvCmd_EhTimer1_cmd_IS "EngTimerGUIEvCmd_EhTimer1_cmd_ISig_5";
BA_ "GenSigSendType" SG_ 2432657472 EngTimerGUIEvCmd_Timer1StartDay_ 1;
BA_ "GenSigCycleTime" SG_ 2432657472 EngTimerGUIEvCmd_Timer1StartDay_ 100;
BA_ "GenSigCycleTimeActive" SG_ 2432657472 EngTimerGUIEvCmd_Timer1StartDay_ 100;
BA_ "GenSigStartValue" SG_ 2432657472 EngTimerGUIEvCmd_Timer1StartDay_ 15;
BA_ "GenSigMaxLatency" SG_ 2432657472 EngTimerGUIEvCmd_Timer1StartDay_ 26;
BA_ "SystemSignalLongSymbol" SG_ 2432657472 EngTimerGUIEvCmd_Timer1StartDay_ "EngTimerGUIEvCmd_Timer1StartDay_ISig_5";
BA_ "GenSigSendType" SG_ 2432657472 EngTimerGUIEvCmd_Timer3Recur_ISi 1;
BA_ "GenSigCycleTime" SG_ 2432657472 EngTimerGUIEvCmd_Timer3Recur_ISi 100;
BA_ "GenSigCycleTimeActive" SG_ 2432657472 EngTimerGUIEvCmd_Timer3Recur_ISi 100;
BA_ "GenSigStartValue" SG_ 2432657472 EngTimerGUIEvCmd_Timer3Recur_ISi 15;
BA_ "GenSigMaxLatency" SG_ 2432657472 EngTimerGUIEvCmd_Timer3Recur_ISi 26;
BA_ "SystemSignalLongSymbol" SG_ 2432657472 EngTimerGUIEvCmd_Timer3Recur_ISi "EngTimerGUIEvCmd_Timer3Recur_ISig_5";
BA_ "GenSigSendType" SG_ 2432657472 EngTimerGUIEvCmd_Timer2Hours_ISi 1;
BA_ "GenSigCycleTime" SG_ 2432657472 EngTimerGUIEvCmd_Timer2Hours_ISi 100;
BA_ "GenSigCycleTimeActive" SG_ 2432657472 EngTimerGUIEvCmd_Timer2Hours_ISi 100;
BA_ "GenSigStartValue" SG_ 2432657472 EngTimerGUIEvCmd_Timer2Hours_ISi 255;
BA_ "GenSigMaxLatency" SG_ 2432657472 EngTimerGUIEvCmd_Timer2Hours_ISi 26;
BA_ "SystemSignalLongSymbol" SG_ 2432657472 EngTimerGUIEvCmd_Timer2Hours_ISi "EngTimerGUIEvCmd_Timer2Hours_ISig_5";
BA_ "GenSigSendType" SG_ 2432657472 EngTimerGUIEvCmd_Timer2StartDay_ 1;
BA_ "GenSigCycleTime" SG_ 2432657472 EngTimerGUIEvCmd_Timer2StartDay_ 100;
BA_ "GenSigCycleTimeActive" SG_ 2432657472 EngTimerGUIEvCmd_Timer2StartDay_ 100;
BA_ "GenSigStartValue" SG_ 2432657472 EngTimerGUIEvCmd_Timer2StartDay_ 15;
BA_ "GenSigMaxLatency" SG_ 2432657472 EngTimerGUIEvCmd_Timer2StartDay_ 26;
BA_ "SystemSignalLongSymbol" SG_ 2432657472 EngTimerGUIEvCmd_Timer2StartDay_ "EngTimerGUIEvCmd_Timer2StartDay_ISig_5";
BA_ "GenSigSendType" SG_ 2432657472 EngTimerGUIEvCmd_Timer1Minutes_I 1;
BA_ "GenSigCycleTime" SG_ 2432657472 EngTimerGUIEvCmd_Timer1Minutes_I 100;
BA_ "GenSigCycleTimeActive" SG_ 2432657472 EngTimerGUIEvCmd_Timer1Minutes_I 100;
BA_ "GenSigStartValue" SG_ 2432657472 EngTimerGUIEvCmd_Timer1Minutes_I 255;
BA_ "GenSigMaxLatency" SG_ 2432657472 EngTimerGUIEvCmd_Timer1Minutes_I 26;
BA_ "SystemSignalLongSymbol" SG_ 2432657472 EngTimerGUIEvCmd_Timer1Minutes_I "EngTimerGUIEvCmd_Timer1Minutes_ISig_5";
BA_ "GenSigSendType" SG_ 2432657472 EngTimerGUIEvCmd_Timer1Hours_ISi 1;
BA_ "GenSigCycleTime" SG_ 2432657472 EngTimerGUIEvCmd_Timer1Hours_ISi 100;
BA_ "GenSigCycleTimeActive" SG_ 2432657472 EngTimerGUIEvCmd_Timer1Hours_ISi 100;
BA_ "GenSigStartValue" SG_ 2432657472 EngTimerGUIEvCmd_Timer1Hours_ISi 255;
BA_ "GenSigMaxLatency" SG_ 2432657472 EngTimerGUIEvCmd_Timer1Hours_ISi 26;
BA_ "SystemSignalLongSymbol" SG_ 2432657472 EngTimerGUIEvCmd_Timer1Hours_ISi "EngTimerGUIEvCmd_Timer1Hours_ISig_5";
BA_ "GenSigSendType" SG_ 2432657472 EngTimerGUIEvCmd_Timer2Minutes_I 1;
BA_ "GenSigCycleTime" SG_ 2432657472 EngTimerGUIEvCmd_Timer2Minutes_I 100;
BA_ "GenSigCycleTimeActive" SG_ 2432657472 EngTimerGUIEvCmd_Timer2Minutes_I 100;
BA_ "GenSigStartValue" SG_ 2432657472 EngTimerGUIEvCmd_Timer2Minutes_I 255;
BA_ "GenSigMaxLatency" SG_ 2432657472 EngTimerGUIEvCmd_Timer2Minutes_I 26;
BA_ "SystemSignalLongSymbol" SG_ 2432657472 EngTimerGUIEvCmd_Timer2Minutes_I "EngTimerGUIEvCmd_Timer2Minutes_ISig_5";
BA_ "GenSigSendType" SG_ 2432657472 EngTimerGUIEvCmd_Timer1Recur_ISi 1;
BA_ "GenSigCycleTime" SG_ 2432657472 EngTimerGUIEvCmd_Timer1Recur_ISi 100;
BA_ "GenSigCycleTimeActive" SG_ 2432657472 EngTimerGUIEvCmd_Timer1Recur_ISi 100;
BA_ "GenSigStartValue" SG_ 2432657472 EngTimerGUIEvCmd_Timer1Recur_ISi 15;
BA_ "GenSigMaxLatency" SG_ 2432657472 EngTimerGUIEvCmd_Timer1Recur_ISi 26;
BA_ "SystemSignalLongSymbol" SG_ 2432657472 EngTimerGUIEvCmd_Timer1Recur_ISi "EngTimerGUIEvCmd_Timer1Recur_ISig_5";
BA_ "GenSigSendType" SG_ 2432657472 EngTimerGUIEvCmd_Timer3StartDay_ 1;
BA_ "GenSigCycleTime" SG_ 2432657472 EngTimerGUIEvCmd_Timer3StartDay_ 100;
BA_ "GenSigCycleTimeActive" SG_ 2432657472 EngTimerGUIEvCmd_Timer3StartDay_ 100;
BA_ "GenSigStartValue" SG_ 2432657472 EngTimerGUIEvCmd_Timer3StartDay_ 15;
BA_ "GenSigMaxLatency" SG_ 2432657472 EngTimerGUIEvCmd_Timer3StartDay_ 26;
BA_ "SystemSignalLongSymbol" SG_ 2432657472 EngTimerGUIEvCmd_Timer3StartDay_ "EngTimerGUIEvCmd_Timer3StartDay_ISig_5";
BA_ "GenSigSendType" SG_ 2432657472 EngTimerGUIEvCmd_EhTimer2_cmd_IS 1;
BA_ "GenSigCycleTime" SG_ 2432657472 EngTimerGUIEvCmd_EhTimer2_cmd_IS 100;
BA_ "GenSigCycleTimeActive" SG_ 2432657472 EngTimerGUIEvCmd_EhTimer2_cmd_IS 100;
BA_ "GenSigStartValue" SG_ 2432657472 EngTimerGUIEvCmd_EhTimer2_cmd_IS 7;
BA_ "GenSigMaxLatency" SG_ 2432657472 EngTimerGUIEvCmd_EhTimer2_cmd_IS 26;
BA_ "SystemSignalLongSymbol" SG_ 2432657472 EngTimerGUIEvCmd_EhTimer2_cmd_IS "EngTimerGUIEvCmd_EhTimer2_cmd_ISig_5";
BA_ "GenSigSendType" SG_ 2432657472 EngTimerGUIEvCmd_Timer3Minutes_I 1;
BA_ "GenSigCycleTime" SG_ 2432657472 EngTimerGUIEvCmd_Timer3Minutes_I 100;
BA_ "GenSigCycleTimeActive" SG_ 2432657472 EngTimerGUIEvCmd_Timer3Minutes_I 100;
BA_ "GenSigStartValue" SG_ 2432657472 EngTimerGUIEvCmd_Timer3Minutes_I 255;
BA_ "GenSigMaxLatency" SG_ 2432657472 EngTimerGUIEvCmd_Timer3Minutes_I 26;
BA_ "SystemSignalLongSymbol" SG_ 2432657472 EngTimerGUIEvCmd_Timer3Minutes_I "EngTimerGUIEvCmd_Timer3Minutes_ISig_5";
BA_ "GenSigSendType" SG_ 2432657473 CIOM_Cab_04P_FCS 7;
BA_ "GenSigCycleTime" SG_ 2432651584 ParkHeaterTimerReleased_stat_ISi 100;
BA_ "GenSigCycleTimeActive" SG_ 2432651584 ParkHeaterTimerReleased_stat_ISi 100;
BA_ "GenSigStartValue" SG_ 2432651584 ParkHeaterTimerReleased_stat_ISi 3;
BA_ "GenSigMaxLatency" SG_ 2432651584 ParkHeaterTimerReleased_stat_ISi 26;
BA_ "SystemSignalLongSymbol" SG_ 2432651584 ParkHeaterTimerReleased_stat_ISi "ParkHeaterTimerReleased_stat_ISig_5";
BA_ "GenSigCycleTime" SG_ 2432651584 Washing_HMI_rqst_ISig_5 100;
BA_ "GenSigCycleTimeActive" SG_ 2432651584 Washing_HMI_rqst_ISig_5 100;
BA_ "GenSigStartValue" SG_ 2432651584 Washing_HMI_rqst_ISig_5 3;
BA_ "GenSigCycleTime" SG_ 2432651584 BunkH2ParkHeater_ButtonStatus 100;
BA_ "GenSigCycleTimeActive" SG_ 2432651584 BunkH2ParkHeater_ButtonStatus 100;
BA_ "GenSigStartValue" SG_ 2432651584 BunkH2ParkHeater_ButtonStatus 3;
BA_ "GenSigMaxLatency" SG_ 2432651584 BunkH2ParkHeater_ButtonStatus 26;
BA_ "GenSigCycleTime" SG_ 2432651584 BunkBTempDec_ButtonStatus 100;
BA_ "GenSigCycleTimeActive" SG_ 2432651584 BunkBTempDec_ButtonStatus 100;
BA_ "GenSigStartValue" SG_ 2432651584 BunkBTempDec_ButtonStatus 3;
BA_ "GenSigMaxLatency" SG_ 2432651584 BunkBTempDec_ButtonStatus 26;
BA_ "GenSigCycleTime" SG_ 2432651584 BunkH2TempDec_ButtonStatus 100;
BA_ "GenSigCycleTimeActive" SG_ 2432651584 BunkH2TempDec_ButtonStatus 100;
BA_ "GenSigStartValue" SG_ 2432651584 BunkH2TempDec_ButtonStatus 3;
BA_ "GenSigMaxLatency" SG_ 2432651584 BunkH2TempDec_ButtonStatus 26;
BA_ "GenSigCycleTime" SG_ 2432651584 BunkH2PHTimer_rqst_StartTimeMin 100;
BA_ "GenSigCycleTimeActive" SG_ 2432651584 BunkH2PHTimer_rqst_StartTimeMin 100;
BA_ "GenSigStartValue" SG_ 2432651584 BunkH2PHTimer_rqst_StartTimeMin 255;
BA_ "GenSigMaxLatency" SG_ 2432651584 BunkH2PHTimer_rqst_StartTimeMin 26;
BA_ "GenSigCycleTime" SG_ 2432651584 BunkH2PHTimer_rqst_DurnTimeMin 100;
BA_ "GenSigCycleTimeActive" SG_ 2432651584 BunkH2PHTimer_rqst_DurnTimeMin 100;
BA_ "GenSigStartValue" SG_ 2432651584 BunkH2PHTimer_rqst_DurnTimeMin 255;
BA_ "GenSigMaxLatency" SG_ 2432651584 BunkH2PHTimer_rqst_DurnTimeMin 26;
BA_ "GenSigCycleTime" SG_ 2432651584 BunkBParkHeater_ButtonStatus 100;
BA_ "GenSigCycleTimeActive" SG_ 2432651584 BunkBParkHeater_ButtonStatus 100;
BA_ "GenSigStartValue" SG_ 2432651584 BunkBParkHeater_ButtonStatus 3;
BA_ "GenSigMaxLatency" SG_ 2432651584 BunkBParkHeater_ButtonStatus 26;
BA_ "GenSigCycleTime" SG_ 2432651584 BunkH2PHTimer_rqst_StartTimeHr 100;
BA_ "GenSigCycleTimeActive" SG_ 2432651584 BunkH2PHTimer_rqst_StartTimeHr 100;
BA_ "GenSigStartValue" SG_ 2432651584 BunkH2PHTimer_rqst_StartTimeHr 255;
BA_ "GenSigMaxLatency" SG_ 2432651584 BunkH2PHTimer_rqst_StartTimeHr 26;
BA_ "GenSigCycleTime" SG_ 2432651584 BunkH2PHTimer_rqst_DurnTimeHr 100;
BA_ "GenSigCycleTimeActive" SG_ 2432651584 BunkH2PHTimer_rqst_DurnTimeHr 100;
BA_ "GenSigStartValue" SG_ 2432651584 BunkH2PHTimer_rqst_DurnTimeHr 255;
BA_ "GenSigMaxLatency" SG_ 2432651584 BunkH2PHTimer_rqst_DurnTimeHr 26;
BA_ "GenSigCycleTime" SG_ 2432651584 BunkBTempInc_ButtonStatus 100;
BA_ "GenSigCycleTimeActive" SG_ 2432651584 BunkBTempInc_ButtonStatus 100;
BA_ "GenSigStartValue" SG_ 2432651584 BunkBTempInc_ButtonStatus 3;
BA_ "GenSigMaxLatency" SG_ 2432651584 BunkBTempInc_ButtonStatus 26;
BA_ "GenSigCycleTime" SG_ 2432651584 AudioSystemStatus_ISig_5 100;
BA_ "GenSigCycleTimeActive" SG_ 2432651584 AudioSystemStatus_ISig_5 100;
BA_ "GenSigStartValue" SG_ 2432651584 AudioSystemStatus_ISig_5 3;
BA_ "GenSigMaxLatency" SG_ 2432651584 AudioSystemStatus_ISig_5 26;
BA_ "GenSigCycleTime" SG_ 2432651584 ParkingHeaterCleaning_cmd_ISig_5 100;
BA_ "GenSigCycleTimeActive" SG_ 2432651584 ParkingHeaterCleaning_cmd_ISig_5 100;
BA_ "GenSigStartValue" SG_ 2432651584 ParkingHeaterCleaning_cmd_ISig_5 3;
BA_ "GenSigMaxLatency" SG_ 2432651584 ParkingHeaterCleaning_cmd_ISig_5 26;
BA_ "GenSigCycleTime" SG_ 2432651584 PtosStatus_ISig_5 100;
BA_ "GenSigCycleTimeActive" SG_ 2432651584 PtosStatus_ISig_5 100;
BA_ "GenSigStartValue" SG_ 2432651584 PtosStatus_ISig_5 3;
BA_ "GenSigMaxLatency" SG_ 2432651584 PtosStatus_ISig_5 26;
BA_ "NeedsUpdateBit" SG_ 2432651584 PtosStatus_ISig_5 1;
BA_ "SeToolAncestorID_SIGNAL" SG_ 2432651584 PtosStatus_ISig_5 "x0000001D042CA490";
BA_ "SeToolItemID_SIGNAL" SG_ 2432651584 PtosStatus_ISig_5 "x0000001D042CA490";
BA_ "SeToolName_SIGNAL" SG_ 2432651584 PtosStatus_ISig_5 "PtosStatus";
BA_ "SeToolVersion_SIGNAL" SG_ 2432651584 PtosStatus_ISig_5 "1";
BA_ "GenSigSendType" SG_ 2432651584 PtosStatus_UB_ISig_5 7;
BA_ "GenSigCycleTime" SG_ 2432651584 BunkB1ParkHeaterBtn_stat 100;
BA_ "GenSigCycleTimeActive" SG_ 2432651584 BunkB1ParkHeaterBtn_stat 100;
BA_ "GenSigStartValue" SG_ 2432651584 BunkB1ParkHeaterBtn_stat 3;
BA_ "GenSigMaxLatency" SG_ 2432651584 BunkB1ParkHeaterBtn_stat 26;
BA_ "GenSigCycleTime" SG_ 2432651584 BunkH2PHTimer_rqst_Timer_cmd 100;
BA_ "GenSigCycleTimeActive" SG_ 2432651584 BunkH2PHTimer_rqst_Timer_cmd 100;
BA_ "GenSigStartValue" SG_ 2432651584 BunkH2PHTimer_rqst_Timer_cmd 7;
BA_ "GenSigMaxLatency" SG_ 2432651584 BunkH2PHTimer_rqst_Timer_cmd 26;
BA_ "GenSigCycleTime" SG_ 2431745856 BacklightCmd_ISig_5 100;
BA_ "GenSigCycleTimeActive" SG_ 2431745856 BacklightCmd_ISig_5 100;
BA_ "GenSigMaxLatency" SG_ 2431745856 BacklightCmd_ISig_5 26;
BA_ "SeToolAncestorID_SIGNAL" SG_ 2431745856 BacklightCmd_ISig_5 "x0000001D0439DDD1";
BA_ "SeToolItemID_SIGNAL" SG_ 2431745856 BacklightCmd_ISig_5 "x0000001D043A84D3";
BA_ "SeToolName_SIGNAL" SG_ 2431745856 BacklightCmd_ISig_5 "BacklightCmd";
BA_ "SeToolVersion_SIGNAL" SG_ 2431745856 BacklightCmd_ISig_5 "2";
BA_ "GenSigCycleTime" SG_ 2431745856 EngineSpeed_ISig_5 100;
BA_ "GenSigCycleTimeActive" SG_ 2431745856 EngineSpeed_ISig_5 100;
BA_ "GenSigStartValue" SG_ 2431745856 EngineSpeed_ISig_5 65535;
BA_ "GenSigMaxLatency" SG_ 2431745856 EngineSpeed_ISig_5 26;
BA_ "NeedsUpdateBit" SG_ 2431745856 EngineSpeed_ISig_5 1;
BA_ "SeToolAncestorID_SIGNAL" SG_ 2431745856 EngineSpeed_ISig_5 "x0000001D0410BACF";
BA_ "SeToolItemID_SIGNAL" SG_ 2431745856 EngineSpeed_ISig_5 "x0000001D0410BACF";
BA_ "SeToolName_SIGNAL" SG_ 2431745856 EngineSpeed_ISig_5 "EngineSpeed_status";
BA_ "SeToolVersion_SIGNAL" SG_ 2431745856 EngineSpeed_ISig_5 "1";
BA_ "GenSigSendType" SG_ 2431745856 LevelControlInformation_UB_ISig_ 7;
BA_ "SystemSignalLongSymbol" SG_ 2431745856 LevelControlInformation_UB_ISig_ "LevelControlInformation_UB_ISig_5";
BA_ "GenSigCycleTime" SG_ 2431745856 PresetIndicationCmd_ISig_5 100;
BA_ "GenSigCycleTimeActive" SG_ 2431745856 PresetIndicationCmd_ISig_5 100;
BA_ "GenSigStartValue" SG_ 2431745856 PresetIndicationCmd_ISig_5 63;
BA_ "GenSigCycleTime" SG_ 2431745856 VehicleMode_ISig_5 100;
BA_ "GenSigCycleTimeActive" SG_ 2431745856 VehicleMode_ISig_5 100;
BA_ "GenSigStartValue" SG_ 2431745856 VehicleMode_ISig_5 15;
BA_ "NeedsUpdateBit" SG_ 2431745856 VehicleMode_ISig_5 1;
BA_ "GenSigCycleTime" SG_ 2431745856 BunkH2OnOFF_ButtonStatus 100;
BA_ "GenSigCycleTimeActive" SG_ 2431745856 BunkH2OnOFF_ButtonStatus 100;
BA_ "GenSigStartValue" SG_ 2431745856 BunkH2OnOFF_ButtonStatus 3;
BA_ "GenSigCycleTime" SG_ 2431745856 IntLghtModeInd_cmd_EventFlag 100;
BA_ "GenSigCycleTimeActive" SG_ 2431745856 IntLghtModeInd_cmd_EventFlag 100;
BA_ "GenSigCycleTime" SG_ 2431745856 LevelControlInformation_ISig_5 100;
BA_ "GenSigCycleTimeActive" SG_ 2431745856 LevelControlInformation_ISig_5 100;
BA_ "GenSigStartValue" SG_ 2431745856 LevelControlInformation_ISig_5 15;
BA_ "NeedsUpdateBit" SG_ 2431745856 LevelControlInformation_ISig_5 1;
BA_ "SeToolAncestorID_SIGNAL" SG_ 2431745856 LevelControlInformation_ISig_5 "x0000001D04290369";
BA_ "SeToolItemID_SIGNAL" SG_ 2431745856 LevelControlInformation_ISig_5 "x0000001D04290369";
BA_ "SeToolName_SIGNAL" SG_ 2431745856 LevelControlInformation_ISig_5 "LevelControlInformation";
BA_ "SeToolVersion_SIGNAL" SG_ 2431745856 LevelControlInformation_ISig_5 "1";
BA_ "GenSigCycleTime" SG_ 2431745856 WheelBasedVehicleSpeed_ISig_5 100;
BA_ "GenSigCycleTimeActive" SG_ 2431745856 WheelBasedVehicleSpeed_ISig_5 100;
BA_ "GenSigStartValue" SG_ 2431745856 WheelBasedVehicleSpeed_ISig_5 65535;
BA_ "GenSigMaxLatency" SG_ 2431745856 WheelBasedVehicleSpeed_ISig_5 26;
BA_ "SeToolAncestorID_SIGNAL" SG_ 2431745856 WheelBasedVehicleSpeed_ISig_5 "x0000001D040FEBD2";
BA_ "SeToolItemID_SIGNAL" SG_ 2431745856 WheelBasedVehicleSpeed_ISig_5 "x0000001D040FEBD2";
BA_ "SeToolName_SIGNAL" SG_ 2431745856 WheelBasedVehicleSpeed_ISig_5 "Wheel-BasedVehicleSpeed";
BA_ "SeToolVersion_SIGNAL" SG_ 2431745856 WheelBasedVehicleSpeed_ISig_5 "1";
BA_ "GenSigCycleTime" SG_ 2431745856 IntLghtModeInd_cmd_IL_Mode 100;
BA_ "GenSigCycleTimeActive" SG_ 2431745856 IntLghtModeInd_cmd_IL_Mode 100;
BA_ "GenSigStartValue" SG_ 2431745856 IntLghtModeInd_cmd_IL_Mode 7;
BA_ "GenSigSendType" SG_ 2431745856 VehicleMode_UB_ISig_5 7;
BA_ "GenSigSendType" SG_ 2431745856 EngineSpeed_UB_ISig_5 7;
BA_ "GenSigCycleTime" SG_ 2432650304 EngineCoolantTemp_stat_ISig_5 100;
BA_ "GenSigCycleTimeActive" SG_ 2432650304 EngineCoolantTemp_stat_ISig_5 100;
BA_ "GenSigStartValue" SG_ 2432650304 EngineCoolantTemp_stat_ISig_5 255;
BA_ "GenSigMaxLatency" SG_ 2432650304 EngineCoolantTemp_stat_ISig_5 26;
BA_ "SeToolAncestorID_SIGNAL" SG_ 2432650304 EngineCoolantTemp_stat_ISig_5 "x0000001D0410E5B1";
BA_ "SeToolItemID_SIGNAL" SG_ 2432650304 EngineCoolantTemp_stat_ISig_5 "x0000001D0410E5B1";
BA_ "SeToolName_SIGNAL" SG_ 2432650304 EngineCoolantTemp_stat_ISig_5 "EngineCoolantTemperature_status";
BA_ "SeToolVersion_SIGNAL" SG_ 2432650304 EngineCoolantTemp_stat_ISig_5 "1";
BA_ "GenSigCycleTime" SG_ 2432650304 DriverSeatBeltSwitch_ISig_5 100;
BA_ "GenSigCycleTimeActive" SG_ 2432650304 DriverSeatBeltSwitch_ISig_5 100;
BA_ "GenSigStartValue" SG_ 2432650304 DriverSeatBeltSwitch_ISig_5 3;
BA_ "GenSigMaxLatency" SG_ 2432650304 DriverSeatBeltSwitch_ISig_5 26;
BA_ "SeToolAncestorID_SIGNAL" SG_ 2432650304 DriverSeatBeltSwitch_ISig_5 "x0000001D0412FE94";
BA_ "SeToolItemID_SIGNAL" SG_ 2432650304 DriverSeatBeltSwitch_ISig_5 "x0000001D0412FE94";
BA_ "SeToolName_SIGNAL" SG_ 2432650304 DriverSeatBeltSwitch_ISig_5 "DriverSeatBeltSwitch";
BA_ "SeToolVersion_SIGNAL" SG_ 2432650304 DriverSeatBeltSwitch_ISig_5 "1";
BA_ "GenSigCycleTime" SG_ 2432650304 AmbientAirTemperature_ISig_5 100;
BA_ "GenSigCycleTimeActive" SG_ 2432650304 AmbientAirTemperature_ISig_5 100;
BA_ "GenSigStartValue" SG_ 2432650304 AmbientAirTemperature_ISig_5 65535;
BA_ "GenSigMaxLatency" SG_ 2432650304 AmbientAirTemperature_ISig_5 26;
BA_ "SeToolAncestorID_SIGNAL" SG_ 2432650304 AmbientAirTemperature_ISig_5 "x0000001D040FEBC8";
BA_ "SeToolItemID_SIGNAL" SG_ 2432650304 AmbientAirTemperature_ISig_5 "x0000001D040FEBC8";
BA_ "SeToolName_SIGNAL" SG_ 2432650304 AmbientAirTemperature_ISig_5 "AmbientAirTemperature";
BA_ "SeToolVersion_SIGNAL" SG_ 2432650304 AmbientAirTemperature_ISig_5 "1";
BA_ "GenSigCycleTime" SG_ 2432650304 DriverMemory_rqst_ISig_5 100;
BA_ "GenSigCycleTimeActive" SG_ 2432650304 DriverMemory_rqst_ISig_5 100;
BA_ "GenSigStartValue" SG_ 2432650304 DriverMemory_rqst_ISig_5 31;
BA_ "GenSigCycleTime" SG_ 2432650304 ReverseGearEngaged_ISig_5 100;
BA_ "GenSigCycleTimeActive" SG_ 2432650304 ReverseGearEngaged_ISig_5 100;
BA_ "GenSigStartValue" SG_ 2432650304 ReverseGearEngaged_ISig_5 3;
BA_ "GenSigMaxLatency" SG_ 2432650304 ReverseGearEngaged_ISig_5 26;
BA_ "SeToolAncestorID_SIGNAL" SG_ 2432650304 ReverseGearEngaged_ISig_5 "x0000001D0413A2F1";
BA_ "SeToolItemID_SIGNAL" SG_ 2432650304 ReverseGearEngaged_ISig_5 "x0000001D0413A2F1";
BA_ "SeToolName_SIGNAL" SG_ 2432650304 ReverseGearEngaged_ISig_5 "ReverseGearEngaged";
BA_ "SeToolVersion_SIGNAL" SG_ 2432650304 ReverseGearEngaged_ISig_5 "1";
BA_ "GenSigCycleTime" SG_ 2432650304 AutoBlowerLevel_Selection_ISig_5 100;
BA_ "GenSigCycleTimeActive" SG_ 2432650304 AutoBlowerLevel_Selection_ISig_5 100;
BA_ "GenSigStartValue" SG_ 2432650304 AutoBlowerLevel_Selection_ISig_5 7;
BA_ "GenSigMaxLatency" SG_ 2432650304 AutoBlowerLevel_Selection_ISig_5 26;
BA_ "SeToolAncestorID_SIGNAL" SG_ 2432650304 AutoBlowerLevel_Selection_ISig_5 "x0000001D0441090E";
BA_ "SeToolItemID_SIGNAL" SG_ 2432650304 AutoBlowerLevel_Selection_ISig_5 "x0000001D0441090E";
BA_ "SeToolName_SIGNAL" SG_ 2432650304 AutoBlowerLevel_Selection_ISig_5 "AutoBlowerLevel_Selection";
BA_ "SeToolVersion_SIGNAL" SG_ 2432650304 AutoBlowerLevel_Selection_ISig_5 "1";
BA_ "GenSigCycleTime" SG_ 2432650304 AutoDefogmode_Selection_ISig_5 100;
BA_ "GenSigCycleTimeActive" SG_ 2432650304 AutoDefogmode_Selection_ISig_5 100;
BA_ "GenSigStartValue" SG_ 2432650304 AutoDefogmode_Selection_ISig_5 7;
BA_ "GenSigMaxLatency" SG_ 2432650304 AutoDefogmode_Selection_ISig_5 26;
BA_ "SeToolAncestorID_SIGNAL" SG_ 2432650304 AutoDefogmode_Selection_ISig_5 "x0000001D04410A66";
BA_ "SeToolItemID_SIGNAL" SG_ 2432650304 AutoDefogmode_Selection_ISig_5 "x0000001D04410A66";
BA_ "SeToolName_SIGNAL" SG_ 2432650304 AutoDefogmode_Selection_ISig_5 "AutoDefogmode_Selection";
BA_ "SeToolVersion_SIGNAL" SG_ 2432650304 AutoDefogmode_Selection_ISig_5 "1";
BA_ "GenSigCycleTime" SG_ 2432650304 ECSStandbyActive 100;
BA_ "GenSigCycleTimeActive" SG_ 2432650304 ECSStandbyActive 100;
BA_ "GenSigStartValue" SG_ 2432650304 ECSStandbyActive 3;
BA_ "GenSigMaxLatency" SG_ 2432650304 ECSStandbyActive 15;
BA_ "GenSigCycleTime" SG_ 2432650304 ACMode_Selection_ISig_5 100;
BA_ "GenSigCycleTimeActive" SG_ 2432650304 ACMode_Selection_ISig_5 100;
BA_ "GenSigStartValue" SG_ 2432650304 ACMode_Selection_ISig_5 7;
BA_ "GenSigMaxLatency" SG_ 2432650304 ACMode_Selection_ISig_5 26;
BA_ "SeToolAncestorID_SIGNAL" SG_ 2432650304 ACMode_Selection_ISig_5 "x0000001D04410743";
BA_ "SeToolItemID_SIGNAL" SG_ 2432650304 ACMode_Selection_ISig_5 "x0000001D04410743";
BA_ "SeToolName_SIGNAL" SG_ 2432650304 ACMode_Selection_ISig_5 "ACMode_Selection";
BA_ "SeToolVersion_SIGNAL" SG_ 2432650304 ACMode_Selection_ISig_5 "1";
BA_ "GenSigCycleTime" SG_ 2432650304 HeightAdjustmentAllowed_ISig_5 100;
BA_ "GenSigCycleTimeActive" SG_ 2432650304 HeightAdjustmentAllowed_ISig_5 100;
BA_ "GenSigStartValue" SG_ 2432650304 HeightAdjustmentAllowed_ISig_5 3;
BA_ "GenSigCycleTime" SG_ 2432650304 AQSMode_Selection_ISig_5 100;
BA_ "GenSigCycleTimeActive" SG_ 2432650304 AQSMode_Selection_ISig_5 100;
BA_ "GenSigStartValue" SG_ 2432650304 AQSMode_Selection_ISig_5 3;
BA_ "GenSigMaxLatency" SG_ 2432650304 AQSMode_Selection_ISig_5 26;
BA_ "SeToolAncestorID_SIGNAL" SG_ 2432650304 AQSMode_Selection_ISig_5 "x0000001D044108B3";
BA_ "SeToolItemID_SIGNAL" SG_ 2432650304 AQSMode_Selection_ISig_5 "x0000001D044108B3";
BA_ "SeToolName_SIGNAL" SG_ 2432650304 AQSMode_Selection_ISig_5 "AQSMode_Selection";
BA_ "SeToolVersion_SIGNAL" SG_ 2432650304 AQSMode_Selection_ISig_5 "1";
BA_ "GenSigCycleTime" SG_ 2432650304 SelectedTimeFormat_stat_ISig_5 100;
BA_ "GenSigCycleTimeActive" SG_ 2432650304 SelectedTimeFormat_stat_ISig_5 100;
BA_ "GenSigStartValue" SG_ 2432650304 SelectedTimeFormat_stat_ISig_5 3;
BA_ "GenSigCycleTime" SG_ 2432650304 SelectedWeightUnit_stat_ISig_5 100;
BA_ "GenSigCycleTimeActive" SG_ 2432650304 SelectedWeightUnit_stat_ISig_5 100;
BA_ "GenSigStartValue" SG_ 2432650304 SelectedWeightUnit_stat_ISig_5 3;
BA_ "GenSigCycleTime" SG_ 2432650304 FuncIndIlluminationLevel_ISig_5 100;
BA_ "GenSigCycleTimeActive" SG_ 2432650304 FuncIndIlluminationLevel_ISig_5 100;
BA_ "GenSigStartValue" SG_ 2432650304 FuncIndIlluminationLevel_ISig_5 1;
BA_ "GenSigMaxLatency" SG_ 2432650304 FuncIndIlluminationLevel_ISig_5 26;
BA_ "SeToolAncestorID_SIGNAL" SG_ 2432650304 FuncIndIlluminationLevel_ISig_5 "x0000001D043A8396";
BA_ "SeToolItemID_SIGNAL" SG_ 2432650304 FuncIndIlluminationLevel_ISig_5 "x0000001D043A8396";
BA_ "SeToolName_SIGNAL" SG_ 2432650304 FuncIndIlluminationLevel_ISig_5 "FuncIndIlluminationLevel";
BA_ "SeToolVersion_SIGNAL" SG_ 2432650304 FuncIndIlluminationLevel_ISig_5 "1";
BA_ "GenSigCycleTime" SG_ 2432650304 WiperModeStatus_ISig_5 100;
BA_ "GenSigCycleTimeActive" SG_ 2432650304 WiperModeStatus_ISig_5 100;
BA_ "GenSigStartValue" SG_ 2432650304 WiperModeStatus_ISig_5 7;
BA_ "GenSigMaxLatency" SG_ 2432650304 WiperModeStatus_ISig_5 26;
BA_ "SeToolAncestorID_SIGNAL" SG_ 2432650304 WiperModeStatus_ISig_5 "x0000001D0410D271";
BA_ "SeToolItemID_SIGNAL" SG_ 2432650304 WiperModeStatus_ISig_5 "x0000001D0410D271";
BA_ "SeToolName_SIGNAL" SG_ 2432650304 WiperModeStatus_ISig_5 "WiperModeStatus";
BA_ "SeToolVersion_SIGNAL" SG_ 2432650304 WiperModeStatus_ISig_5 "1";
BA_ "GenSigCycleTime" SG_ 2432650304 MirrorHeatingMode_ISig_5 100;
BA_ "GenSigCycleTimeActive" SG_ 2432650304 MirrorHeatingMode_ISig_5 100;
BA_ "GenSigStartValue" SG_ 2432650304 MirrorHeatingMode_ISig_5 7;
BA_ "GenSigMaxLatency" SG_ 2432650304 MirrorHeatingMode_ISig_5 26;
BA_ "SeToolAncestorID_SIGNAL" SG_ 2432650304 MirrorHeatingMode_ISig_5 "x0000001D0412C1DB";
BA_ "SeToolItemID_SIGNAL" SG_ 2432650304 MirrorHeatingMode_ISig_5 "x0000001D0412C1DB";
BA_ "SeToolName_SIGNAL" SG_ 2432650304 MirrorHeatingMode_ISig_5 "MirrorHeatingMode";
BA_ "SeToolVersion_SIGNAL" SG_ 2432650304 MirrorHeatingMode_ISig_5 "1";
BA_ "GenSigCycleTime" SG_ 2432640664 PHTimer2_stat_Recurrence_ISig_5 100;
BA_ "GenSigCycleTimeActive" SG_ 2432640664 PHTimer2_stat_Recurrence_ISig_5 100;
BA_ "GenSigStartValue" SG_ 2432640664 PHTimer2_stat_Recurrence_ISig_5 15;
BA_ "NeedsUpdateBit" SG_ 2432640664 PHTimer2_stat_Recurrence_ISig_5 1;
BA_ "GenSigCycleTime" SG_ 2432640664 PHTimer2_stat_Hours_ISig_5 100;
BA_ "GenSigCycleTimeActive" SG_ 2432640664 PHTimer2_stat_Hours_ISig_5 100;
BA_ "GenSigStartValue" SG_ 2432640664 PHTimer2_stat_Hours_ISig_5 255;
BA_ "NeedsUpdateBit" SG_ 2432640664 PHTimer2_stat_Hours_ISig_5 1;
BA_ "GenSigCycleTime" SG_ 2432640664 PHTimer3_stat_Temp_ISig_5 100;
BA_ "GenSigCycleTimeActive" SG_ 2432640664 PHTimer3_stat_Temp_ISig_5 100;
BA_ "GenSigStartValue" SG_ 2432640664 PHTimer3_stat_Temp_ISig_5 31;
BA_ "NeedsUpdateBit" SG_ 2432640664 PHTimer3_stat_Temp_ISig_5 1;
BA_ "GenSigCycleTime" SG_ 2432640664 PHTimer3_stat_Hours_ISig_5 100;
BA_ "GenSigCycleTimeActive" SG_ 2432640664 PHTimer3_stat_Hours_ISig_5 100;
BA_ "GenSigStartValue" SG_ 2432640664 PHTimer3_stat_Hours_ISig_5 255;
BA_ "NeedsUpdateBit" SG_ 2432640664 PHTimer3_stat_Hours_ISig_5 1;
BA_ "GenSigCycleTime" SG_ 2432640664 PHTimer3_stat_Status_ISig_5 100;
BA_ "GenSigCycleTimeActive" SG_ 2432640664 PHTimer3_stat_Status_ISig_5 100;
BA_ "GenSigStartValue" SG_ 2432640664 PHTimer3_stat_Status_ISig_5 3;
BA_ "NeedsUpdateBit" SG_ 2432640664 PHTimer3_stat_Status_ISig_5 1;
BA_ "GenSigCycleTime" SG_ 2432640664 PHTimer2_stat_StartDay_ISig_5 100;
BA_ "GenSigCycleTimeActive" SG_ 2432640664 PHTimer2_stat_StartDay_ISig_5 100;
BA_ "GenSigStartValue" SG_ 2432640664 PHTimer2_stat_StartDay_ISig_5 15;
BA_ "NeedsUpdateBit" SG_ 2432640664 PHTimer2_stat_StartDay_ISig_5 1;
BA_ "GenSigSendType" SG_ 2432640664 PHTimer2_stat_sg_UB_ISig_5 7;
BA_ "GenSigCycleTime" SG_ 2432640664 PHTimer2_stat_Temp_ISig_5 100;
BA_ "GenSigCycleTimeActive" SG_ 2432640664 PHTimer2_stat_Temp_ISig_5 100;
BA_ "GenSigStartValue" SG_ 2432640664 PHTimer2_stat_Temp_ISig_5 31;
BA_ "NeedsUpdateBit" SG_ 2432640664 PHTimer2_stat_Temp_ISig_5 1;
BA_ "GenSigSendType" SG_ 2432640664 PHTimer3_stat_sg_UB_ISig_5 7;
BA_ "GenSigCycleTime" SG_ 2432640664 PHTimer2_stat_Status_ISig_5 100;
BA_ "GenSigCycleTimeActive" SG_ 2432640664 PHTimer2_stat_Status_ISig_5 100;
BA_ "GenSigStartValue" SG_ 2432640664 PHTimer2_stat_Status_ISig_5 3;
BA_ "NeedsUpdateBit" SG_ 2432640664 PHTimer2_stat_Status_ISig_5 1;
BA_ "GenSigCycleTime" SG_ 2432640664 PHTimer2_stat_Minutes_ISig_5 100;
BA_ "GenSigCycleTimeActive" SG_ 2432640664 PHTimer2_stat_Minutes_ISig_5 100;
BA_ "GenSigStartValue" SG_ 2432640664 PHTimer2_stat_Minutes_ISig_5 255;
BA_ "NeedsUpdateBit" SG_ 2432640664 PHTimer2_stat_Minutes_ISig_5 1;
BA_ "GenSigCycleTime" SG_ 2432640664 PHTimer3_stat_Minutes_ISig_5 100;
BA_ "GenSigCycleTimeActive" SG_ 2432640664 PHTimer3_stat_Minutes_ISig_5 100;
BA_ "GenSigStartValue" SG_ 2432640664 PHTimer3_stat_Minutes_ISig_5 255;
BA_ "NeedsUpdateBit" SG_ 2432640664 PHTimer3_stat_Minutes_ISig_5 1;
BA_ "GenSigCycleTime" SG_ 2432640664 PHTimer3_stat_Recurrence_ISig_5 100;
BA_ "GenSigCycleTimeActive" SG_ 2432640664 PHTimer3_stat_Recurrence_ISig_5 100;
BA_ "GenSigStartValue" SG_ 2432640664 PHTimer3_stat_Recurrence_ISig_5 15;
BA_ "NeedsUpdateBit" SG_ 2432640664 PHTimer3_stat_Recurrence_ISig_5 1;
BA_ "GenSigCycleTime" SG_ 2432640664 PHTimer3_stat_StartDay_ISig_5 100;
BA_ "GenSigCycleTimeActive" SG_ 2432640664 PHTimer3_stat_StartDay_ISig_5 100;
BA_ "GenSigStartValue" SG_ 2432640664 PHTimer3_stat_StartDay_ISig_5 15;
BA_ "NeedsUpdateBit" SG_ 2432640664 PHTimer3_stat_StartDay_ISig_5 1;
BA_ "GenSigCycleTime" SG_ 2432644760 ExtraHeating_status_ISig_5 100;
BA_ "GenSigCycleTimeActive" SG_ 2432644760 ExtraHeating_status_ISig_5 100;
BA_ "GenSigStartValue" SG_ 2432644760 ExtraHeating_status_ISig_5 3;
BA_ "GenSigCycleTime" SG_ 2432644760 PHTimer1_stat_Minutes_ISig_5 100;
BA_ "GenSigCycleTimeActive" SG_ 2432644760 PHTimer1_stat_Minutes_ISig_5 100;
BA_ "GenSigStartValue" SG_ 2432644760 PHTimer1_stat_Minutes_ISig_5 255;
BA_ "NeedsUpdateBit" SG_ 2432644760 PHTimer1_stat_Minutes_ISig_5 1;
BA_ "GenSigCycleTime" SG_ 2432644760 ParkingClimate_IndicationCmd_ISi 100;
BA_ "GenSigCycleTimeActive" SG_ 2432644760 ParkingClimate_IndicationCmd_ISi 100;
BA_ "GenSigStartValue" SG_ 2432644760 ParkingClimate_IndicationCmd_ISi 7;
BA_ "SystemSignalLongSymbol" SG_ 2432644760 ParkingClimate_IndicationCmd_ISi "ParkingClimate_IndicationCmd_ISig_5";
BA_ "GenSigSendType" SG_ 2432644760 PHTimer1_stat_sg_UB_ISig_5 7;
BA_ "GenSigCycleTime" SG_ 2432644760 ShortStopHeater_cmd_ISig_5 100;
BA_ "GenSigCycleTimeActive" SG_ 2432644760 ShortStopHeater_cmd_ISig_5 100;
BA_ "GenSigStartValue" SG_ 2432644760 ShortStopHeater_cmd_ISig_5 3;
BA_ "GenSigCycleTime" SG_ 2432644760 PHTimer1_stat_Status_ISig_5 100;
BA_ "GenSigCycleTimeActive" SG_ 2432644760 PHTimer1_stat_Status_ISig_5 100;
BA_ "GenSigStartValue" SG_ 2432644760 PHTimer1_stat_Status_ISig_5 3;
BA_ "NeedsUpdateBit" SG_ 2432644760 PHTimer1_stat_Status_ISig_5 1;
BA_ "GenSigCycleTime" SG_ 2432644760 PHTimer1_stat_StartDay_ISig_5 100;
BA_ "GenSigCycleTimeActive" SG_ 2432644760 PHTimer1_stat_StartDay_ISig_5 100;
BA_ "GenSigStartValue" SG_ 2432644760 PHTimer1_stat_StartDay_ISig_5 15;
BA_ "NeedsUpdateBit" SG_ 2432644760 PHTimer1_stat_StartDay_ISig_5 1;
BA_ "GenSigCycleTime" SG_ 2432644760 PHTimer1_stat_Duration_ISig_5 100;
BA_ "GenSigCycleTimeActive" SG_ 2432644760 PHTimer1_stat_Duration_ISig_5 100;
BA_ "GenSigStartValue" SG_ 2432644760 PHTimer1_stat_Duration_ISig_5 127;
BA_ "NeedsUpdateBit" SG_ 2432644760 PHTimer1_stat_Duration_ISig_5 1;
BA_ "GenSigCycleTime" SG_ 2432644760 PHTimer1_stat_Temp_ISig_5 100;
BA_ "GenSigCycleTimeActive" SG_ 2432644760 PHTimer1_stat_Temp_ISig_5 100;
BA_ "GenSigStartValue" SG_ 2432644760 PHTimer1_stat_Temp_ISig_5 31;
BA_ "NeedsUpdateBit" SG_ 2432644760 PHTimer1_stat_Temp_ISig_5 1;
BA_ "GenSigCycleTime" SG_ 2432644760 PHTimer1_stat_Recurrence_ISig_5 100;
BA_ "GenSigCycleTimeActive" SG_ 2432644760 PHTimer1_stat_Recurrence_ISig_5 100;
BA_ "GenSigStartValue" SG_ 2432644760 PHTimer1_stat_Recurrence_ISig_5 15;
BA_ "NeedsUpdateBit" SG_ 2432644760 PHTimer1_stat_Recurrence_ISig_5 1;
BA_ "GenSigCycleTime" SG_ 2432644760 PHTimer1_stat_Hours_ISig_5 100;
BA_ "GenSigCycleTimeActive" SG_ 2432644760 PHTimer1_stat_Hours_ISig_5 100;
BA_ "GenSigStartValue" SG_ 2432644760 PHTimer1_stat_Hours_ISig_5 255;
BA_ "NeedsUpdateBit" SG_ 2432644760 PHTimer1_stat_Hours_ISig_5 1;
BA_ "GenSigCycleTime" SG_ 2432645496 AcCoolantPumpEngagementRequest_I 100;
BA_ "GenSigCycleTimeActive" SG_ 2432645496 AcCoolantPumpEngagementRequest_I 100;
BA_ "GenSigStartValue" SG_ 2432645496 AcCoolantPumpEngagementRequest_I 255;
BA_ "SystemSignalLongSymbol" SG_ 2432645496 AcCoolantPumpEngagementRequest_I "AcCoolantPumpEngagementRequest_ISig_5";
BA_ "GenSigCycleTime" SG_ 2432639640 ACmode_IndicationCmd_ISig_5 100;
BA_ "GenSigCycleTimeActive" SG_ 2432639640 ACmode_IndicationCmd_ISig_5 100;
BA_ "GenSigMaxLatency" SG_ 2432639640 ACmode_IndicationCmd_ISig_5 26;
BA_ "SeToolAncestorID_SIGNAL" SG_ 2432639640 ACmode_IndicationCmd_ISig_5 "x0000001D04405ABB";
BA_ "SeToolItemID_SIGNAL" SG_ 2432639640 ACmode_IndicationCmd_ISig_5 "x0000001D04405ABB";
BA_ "SeToolName_SIGNAL" SG_ 2432639640 ACmode_IndicationCmd_ISig_5 "ACmode_IndicationCmd";
BA_ "SeToolVersion_SIGNAL" SG_ 2432639640 ACmode_IndicationCmd_ISig_5 "1";
BA_ "GenSigCycleTime" SG_ 2432639640 PHTimer_rqst_SetAlarmOper_ISig_5 100;
BA_ "GenSigCycleTimeActive" SG_ 2432639640 PHTimer_rqst_SetAlarmOper_ISig_5 100;
BA_ "GenSigStartValue" SG_ 2432639640 PHTimer_rqst_SetAlarmOper_ISig_5 7;
BA_ "GenSigCycleTime" SG_ 2432639640 PHTimer_rqst_Hours_ISig_5 100;
BA_ "GenSigCycleTimeActive" SG_ 2432639640 PHTimer_rqst_Hours_ISig_5 100;
BA_ "GenSigStartValue" SG_ 2432639640 PHTimer_rqst_Hours_ISig_5 255;
BA_ "GenSigMaxLatency" SG_ 2432639640 PHTimer_rqst_Hours_ISig_5 26;
BA_ "GenSigCycleTime" SG_ 2432639640 PH_Activation_cmd_ISig_5 100;
BA_ "GenSigCycleTimeActive" SG_ 2432639640 PH_Activation_cmd_ISig_5 100;
BA_ "GenSigStartValue" SG_ 2432639640 PH_Activation_cmd_ISig_5 7;
BA_ "GenSigMaxLatency" SG_ 2432639640 PH_Activation_cmd_ISig_5 26;
BA_ "GenSigCycleTime" SG_ 2432639640 PHTimer_rqst_Minutes_ISig_5 100;
BA_ "GenSigCycleTimeActive" SG_ 2432639640 PHTimer_rqst_Minutes_ISig_5 100;
BA_ "GenSigStartValue" SG_ 2432639640 PHTimer_rqst_Minutes_ISig_5 255;
BA_ "GenSigMaxLatency" SG_ 2432639640 PHTimer_rqst_Minutes_ISig_5 26;
BA_ "GenSigCycleTime" SG_ 2432639640 CabInteriorTempVentilated_Stat_I 100;
BA_ "GenSigCycleTimeActive" SG_ 2432639640 CabInteriorTempVentilated_Stat_I 100;
BA_ "GenSigStartValue" SG_ 2432639640 CabInteriorTempVentilated_Stat_I 1023;
BA_ "SeToolAncestorID_SIGNAL" SG_ 2432639640 CabInteriorTempVentilated_Stat_I "x0000001D043C9954";
BA_ "SeToolItemID_SIGNAL" SG_ 2432639640 CabInteriorTempVentilated_Stat_I "x0000001D043C9954";
BA_ "SeToolName_SIGNAL" SG_ 2432639640 CabInteriorTempVentilated_Stat_I "CabInteriorTempVentilated_Stat";
BA_ "SeToolVersion_SIGNAL" SG_ 2432639640 CabInteriorTempVentilated_Stat_I "1";
BA_ "SystemSignalLongSymbol" SG_ 2432639640 CabInteriorTempVentilated_Stat_I "CabInteriorTempVentilated_Stat_ISig_5";
BA_ "GenSigCycleTime" SG_ 2432639640 ParkingHeaterCleaning_Rqst_ISig_ 100;
BA_ "GenSigCycleTimeActive" SG_ 2432639640 ParkingHeaterCleaning_Rqst_ISig_ 100;
BA_ "GenSigStartValue" SG_ 2432639640 ParkingHeaterCleaning_Rqst_ISig_ 3;
BA_ "GenSigMaxLatency" SG_ 2432639640 ParkingHeaterCleaning_Rqst_ISig_ 26;
BA_ "SystemSignalLongSymbol" SG_ 2432639640 ParkingHeaterCleaning_Rqst_ISig_ "ParkingHeaterCleaning_Rqst_ISig_5";
BA_ "GenSigCycleTime" SG_ 2432639640 ParkingHeater_IndicationCmd_ISig 100;
BA_ "GenSigCycleTimeActive" SG_ 2432639640 ParkingHeater_IndicationCmd_ISig 100;
BA_ "GenSigMaxLatency" SG_ 2432639640 ParkingHeater_IndicationCmd_ISig 26;
BA_ "SystemSignalLongSymbol" SG_ 2432639640 ParkingHeater_IndicationCmd_ISig "ParkingHeater_IndicationCmd_ISig_5";
BA_ "GenSigCycleTime" SG_ 2432639640 AC_CompressorClutchCmd_ISig_5 100;
BA_ "GenSigCycleTimeActive" SG_ 2432639640 AC_CompressorClutchCmd_ISig_5 100;
BA_ "GenSigStartValue" SG_ 2432639640 AC_CompressorClutchCmd_ISig_5 3;
BA_ "GenSigMaxLatency" SG_ 2432639640 AC_CompressorClutchCmd_ISig_5 26;
BA_ "GenSigCycleTime" SG_ 2432639640 PHTimer_rqst_DayOfWeekRq_ISig_5 100;
BA_ "GenSigCycleTimeActive" SG_ 2432639640 PHTimer_rqst_DayOfWeekRq_ISig_5 100;
BA_ "GenSigStartValue" SG_ 2432639640 PHTimer_rqst_DayOfWeekRq_ISig_5 15;
BA_ "GenSigMaxLatency" SG_ 2432639640 PHTimer_rqst_DayOfWeekRq_ISig_5 26;
BA_ "GenSigSendType" SG_ 2432633753 CCM_Cab_03P_FCS 7;
BA_ "GenSigCycleTime" SG_ 2432633752 EngineTimer_stat_Timer2StartDay_ 100;
BA_ "GenSigCycleTimeActive" SG_ 2432633752 EngineTimer_stat_Timer2StartDay_ 100;
BA_ "GenSigStartValue" SG_ 2432633752 EngineTimer_stat_Timer2StartDay_ 15;
BA_ "GenSigMaxLatency" SG_ 2432633752 EngineTimer_stat_Timer2StartDay_ 26;
BA_ "NeedsUpdateBit" SG_ 2432633752 EngineTimer_stat_Timer2StartDay_ 1;
BA_ "SystemSignalLongSymbol" SG_ 2432633752 EngineTimer_stat_Timer2StartDay_ "EngineTimer_stat_Timer2StartDay_ISig_5";
BA_ "GenSigCycleTime" SG_ 2432633752 EngineTimer_stat_Timer1Recurr_IS 100;
BA_ "GenSigCycleTimeActive" SG_ 2432633752 EngineTimer_stat_Timer1Recurr_IS 100;
BA_ "GenSigStartValue" SG_ 2432633752 EngineTimer_stat_Timer1Recurr_IS 15;
BA_ "GenSigMaxLatency" SG_ 2432633752 EngineTimer_stat_Timer1Recurr_IS 26;
BA_ "NeedsUpdateBit" SG_ 2432633752 EngineTimer_stat_Timer1Recurr_IS 1;
BA_ "SystemSignalLongSymbol" SG_ 2432633752 EngineTimer_stat_Timer1Recurr_IS "EngineTimer_stat_Timer1Recurr_ISig_5";
BA_ "GenSigCycleTime" SG_ 2432633752 EngineTimer_stat_Timer3Hours_ISi 100;
BA_ "GenSigCycleTimeActive" SG_ 2432633752 EngineTimer_stat_Timer3Hours_ISi 100;
BA_ "GenSigStartValue" SG_ 2432633752 EngineTimer_stat_Timer3Hours_ISi 255;
BA_ "GenSigMaxLatency" SG_ 2432633752 EngineTimer_stat_Timer3Hours_ISi 26;
BA_ "NeedsUpdateBit" SG_ 2432633752 EngineTimer_stat_Timer3Hours_ISi 1;
BA_ "SystemSignalLongSymbol" SG_ 2432633752 EngineTimer_stat_Timer3Hours_ISi "EngineTimer_stat_Timer3Hours_ISig_5";
BA_ "GenSigCycleTime" SG_ 2432633752 EngineTimer_stat_Timer2Minutes_I 100;
BA_ "GenSigCycleTimeActive" SG_ 2432633752 EngineTimer_stat_Timer2Minutes_I 100;
BA_ "GenSigStartValue" SG_ 2432633752 EngineTimer_stat_Timer2Minutes_I 255;
BA_ "GenSigMaxLatency" SG_ 2432633752 EngineTimer_stat_Timer2Minutes_I 26;
BA_ "NeedsUpdateBit" SG_ 2432633752 EngineTimer_stat_Timer2Minutes_I 1;
BA_ "SystemSignalLongSymbol" SG_ 2432633752 EngineTimer_stat_Timer2Minutes_I "EngineTimer_stat_Timer2Minutes_ISig_5";
BA_ "GenSigCycleTime" SG_ 2432633752 EngineTimer_stat_Timer2Recurr_IS 100;
BA_ "GenSigCycleTimeActive" SG_ 2432633752 EngineTimer_stat_Timer2Recurr_IS 100;
BA_ "GenSigStartValue" SG_ 2432633752 EngineTimer_stat_Timer2Recurr_IS 15;
BA_ "GenSigMaxLatency" SG_ 2432633752 EngineTimer_stat_Timer2Recurr_IS 26;
BA_ "NeedsUpdateBit" SG_ 2432633752 EngineTimer_stat_Timer2Recurr_IS 1;
BA_ "SystemSignalLongSymbol" SG_ 2432633752 EngineTimer_stat_Timer2Recurr_IS "EngineTimer_stat_Timer2Recurr_ISig_5";
BA_ "GenSigCycleTime" SG_ 2432633752 EngineTimer_stat_Timer1Hours_ISi 100;
BA_ "GenSigCycleTimeActive" SG_ 2432633752 EngineTimer_stat_Timer1Hours_ISi 100;
BA_ "GenSigStartValue" SG_ 2432633752 EngineTimer_stat_Timer1Hours_ISi 255;
BA_ "GenSigMaxLatency" SG_ 2432633752 EngineTimer_stat_Timer1Hours_ISi 26;
BA_ "NeedsUpdateBit" SG_ 2432633752 EngineTimer_stat_Timer1Hours_ISi 1;
BA_ "SystemSignalLongSymbol" SG_ 2432633752 EngineTimer_stat_Timer1Hours_ISi "EngineTimer_stat_Timer1Hours_ISig_5";
BA_ "GenSigCycleTime" SG_ 2432633752 EngineTimer_stat_Timer3Minutes_I 100;
BA_ "GenSigCycleTimeActive" SG_ 2432633752 EngineTimer_stat_Timer3Minutes_I 100;
BA_ "GenSigStartValue" SG_ 2432633752 EngineTimer_stat_Timer3Minutes_I 255;
BA_ "GenSigMaxLatency" SG_ 2432633752 EngineTimer_stat_Timer3Minutes_I 26;
BA_ "NeedsUpdateBit" SG_ 2432633752 EngineTimer_stat_Timer3Minutes_I 1;
BA_ "SystemSignalLongSymbol" SG_ 2432633752 EngineTimer_stat_Timer3Minutes_I "EngineTimer_stat_Timer3Minutes_ISig_5";
BA_ "GenSigCycleTime" SG_ 2432633752 EngineTimer_stat_Timer1Minutes_I 100;
BA_ "GenSigCycleTimeActive" SG_ 2432633752 EngineTimer_stat_Timer1Minutes_I 100;
BA_ "GenSigStartValue" SG_ 2432633752 EngineTimer_stat_Timer1Minutes_I 255;
BA_ "GenSigMaxLatency" SG_ 2432633752 EngineTimer_stat_Timer1Minutes_I 26;
BA_ "NeedsUpdateBit" SG_ 2432633752 EngineTimer_stat_Timer1Minutes_I 1;
BA_ "SystemSignalLongSymbol" SG_ 2432633752 EngineTimer_stat_Timer1Minutes_I "EngineTimer_stat_Timer1Minutes_ISig_5";
BA_ "GenSigCycleTime" SG_ 2432633752 EngineTimer_stat_Timer3StartDay_ 100;
BA_ "GenSigCycleTimeActive" SG_ 2432633752 EngineTimer_stat_Timer3StartDay_ 100;
BA_ "GenSigStartValue" SG_ 2432633752 EngineTimer_stat_Timer3StartDay_ 15;
BA_ "GenSigMaxLatency" SG_ 2432633752 EngineTimer_stat_Timer3StartDay_ 26;
BA_ "NeedsUpdateBit" SG_ 2432633752 EngineTimer_stat_Timer3StartDay_ 1;
BA_ "SystemSignalLongSymbol" SG_ 2432633752 EngineTimer_stat_Timer3StartDay_ "EngineTimer_stat_Timer3StartDay_ISig_5";
BA_ "GenSigSendType" SG_ 2432633752 EngineTimer_stat_sg_UB_ISig_5 7;
BA_ "GenSigCycleTime" SG_ 2432633752 EngineTimer_stat_Timer2_Status_I 100;
BA_ "GenSigCycleTimeActive" SG_ 2432633752 EngineTimer_stat_Timer2_Status_I 100;
BA_ "GenSigStartValue" SG_ 2432633752 EngineTimer_stat_Timer2_Status_I 3;
BA_ "GenSigMaxLatency" SG_ 2432633752 EngineTimer_stat_Timer2_Status_I 26;
BA_ "NeedsUpdateBit" SG_ 2432633752 EngineTimer_stat_Timer2_Status_I 1;
BA_ "SystemSignalLongSymbol" SG_ 2432633752 EngineTimer_stat_Timer2_Status_I "EngineTimer_stat_Timer2_Status_ISig_5";
BA_ "GenSigCycleTime" SG_ 2432633752 EngineTimer_stat_Timer1StartDay_ 100;
BA_ "GenSigCycleTimeActive" SG_ 2432633752 EngineTimer_stat_Timer1StartDay_ 100;
BA_ "GenSigStartValue" SG_ 2432633752 EngineTimer_stat_Timer1StartDay_ 15;
BA_ "GenSigMaxLatency" SG_ 2432633752 EngineTimer_stat_Timer1StartDay_ 26;
BA_ "NeedsUpdateBit" SG_ 2432633752 EngineTimer_stat_Timer1StartDay_ 1;
BA_ "SystemSignalLongSymbol" SG_ 2432633752 EngineTimer_stat_Timer1StartDay_ "EngineTimer_stat_Timer1StartDay_ISig_5";
BA_ "GenSigCycleTime" SG_ 2432633752 EngineTimer_stat_Timer2Hours_ISi 100;
BA_ "GenSigCycleTimeActive" SG_ 2432633752 EngineTimer_stat_Timer2Hours_ISi 100;
BA_ "GenSigStartValue" SG_ 2432633752 EngineTimer_stat_Timer2Hours_ISi 255;
BA_ "GenSigMaxLatency" SG_ 2432633752 EngineTimer_stat_Timer2Hours_ISi 26;
BA_ "NeedsUpdateBit" SG_ 2432633752 EngineTimer_stat_Timer2Hours_ISi 1;
BA_ "SystemSignalLongSymbol" SG_ 2432633752 EngineTimer_stat_Timer2Hours_ISi "EngineTimer_stat_Timer2Hours_ISig_5";
BA_ "GenSigCycleTime" SG_ 2432633752 EngineTimer_stat_Timer3_Status_I 100;
BA_ "GenSigCycleTimeActive" SG_ 2432633752 EngineTimer_stat_Timer3_Status_I 100;
BA_ "GenSigStartValue" SG_ 2432633752 EngineTimer_stat_Timer3_Status_I 3;
BA_ "GenSigMaxLatency" SG_ 2432633752 EngineTimer_stat_Timer3_Status_I 26;
BA_ "NeedsUpdateBit" SG_ 2432633752 EngineTimer_stat_Timer3_Status_I 1;
BA_ "SystemSignalLongSymbol" SG_ 2432633752 EngineTimer_stat_Timer3_Status_I "EngineTimer_stat_Timer3_Status_ISig_5";
BA_ "GenSigCycleTime" SG_ 2432633752 EngineTimer_stat_Timer3Recurr_IS 100;
BA_ "GenSigCycleTimeActive" SG_ 2432633752 EngineTimer_stat_Timer3Recurr_IS 100;
BA_ "GenSigStartValue" SG_ 2432633752 EngineTimer_stat_Timer3Recurr_IS 15;
BA_ "GenSigMaxLatency" SG_ 2432633752 EngineTimer_stat_Timer3Recurr_IS 26;
BA_ "NeedsUpdateBit" SG_ 2432633752 EngineTimer_stat_Timer3Recurr_IS 1;
BA_ "SystemSignalLongSymbol" SG_ 2432633752 EngineTimer_stat_Timer3Recurr_IS "EngineTimer_stat_Timer3Recurr_ISig_5";
BA_ "GenSigCycleTime" SG_ 2432633752 EngineTimer_stat_Timer1_Status_I 100;
BA_ "GenSigCycleTimeActive" SG_ 2432633752 EngineTimer_stat_Timer1_Status_I 100;
BA_ "GenSigStartValue" SG_ 2432633752 EngineTimer_stat_Timer1_Status_I 3;
BA_ "GenSigMaxLatency" SG_ 2432633752 EngineTimer_stat_Timer1_Status_I 26;
BA_ "NeedsUpdateBit" SG_ 2432633752 EngineTimer_stat_Timer1_Status_I 1;
BA_ "SystemSignalLongSymbol" SG_ 2432633752 EngineTimer_stat_Timer1_Status_I "EngineTimer_stat_Timer1_Status_ISig_5";
BA_ "GenSigCycleTime" SG_ 2432637336 AQSmodeIndication_Cmd_ISig_5 100;
BA_ "GenSigCycleTimeActive" SG_ 2432637336 AQSmodeIndication_Cmd_ISig_5 100;
BA_ "GenSigStartValue" SG_ 2432637336 AQSmodeIndication_Cmd_ISig_5 3;
BA_ "GenSigMaxLatency" SG_ 2432637336 AQSmodeIndication_Cmd_ISig_5 26;
BA_ "SeToolAncestorID_SIGNAL" SG_ 2432637336 AQSmodeIndication_Cmd_ISig_5 "x0000001D0441089D";
BA_ "SeToolItemID_SIGNAL" SG_ 2432637336 AQSmodeIndication_Cmd_ISig_5 "x0000001D0441089D";
BA_ "SeToolName_SIGNAL" SG_ 2432637336 AQSmodeIndication_Cmd_ISig_5 "AQSmode_Status";
BA_ "SeToolVersion_SIGNAL" SG_ 2432637336 AQSmodeIndication_Cmd_ISig_5 "1";
BA_ "GenSigSendType" SG_ 2432637336 ACCoolingFanSpeedRequest_CCM_UB 7;
BA_ "GenSigCycleTime" SG_ 2432637336 ACCoolingFanSpeedRequest_CCM_UB 100;
BA_ "GenSigCycleTimeActive" SG_ 2432637336 ACCoolingFanSpeedRequest_CCM_UB 100;
BA_ "GenSigCycleTime" SG_ 2432637336 WindscreenDefrostInd_cmd_ISig_5 100;
BA_ "GenSigCycleTimeActive" SG_ 2432637336 WindscreenDefrostInd_cmd_ISig_5 100;
BA_ "GenSigMaxLatency" SG_ 2432637336 WindscreenDefrostInd_cmd_ISig_5 26;
BA_ "SeToolAncestorID_SIGNAL" SG_ 2432637336 WindscreenDefrostInd_cmd_ISig_5 "x0000001D04405ABB";
BA_ "SeToolItemID_SIGNAL" SG_ 2432637336 WindscreenDefrostInd_cmd_ISig_5 "x0000001D04405ABB";
BA_ "SeToolName_SIGNAL" SG_ 2432637336 WindscreenDefrostInd_cmd_ISig_5 "WindscreenDefrost_IndicationCmd";
BA_ "SeToolVersion_SIGNAL" SG_ 2432637336 WindscreenDefrostInd_cmd_ISig_5 "1";
BA_ "GenSigCycleTime" SG_ 2432637336 AutoBlowerLevelIndication_Cmd_IS 100;
BA_ "GenSigCycleTimeActive" SG_ 2432637336 AutoBlowerLevelIndication_Cmd_IS 100;
BA_ "GenSigStartValue" SG_ 2432637336 AutoBlowerLevelIndication_Cmd_IS 7;
BA_ "GenSigMaxLatency" SG_ 2432637336 AutoBlowerLevelIndication_Cmd_IS 26;
BA_ "SeToolAncestorID_SIGNAL" SG_ 2432637336 AutoBlowerLevelIndication_Cmd_IS "x0000001D044108C4";
BA_ "SeToolItemID_SIGNAL" SG_ 2432637336 AutoBlowerLevelIndication_Cmd_IS "x0000001D044108C4";
BA_ "SeToolName_SIGNAL" SG_ 2432637336 AutoBlowerLevelIndication_Cmd_IS "AutoBlowerLevel_Status";
BA_ "SeToolVersion_SIGNAL" SG_ 2432637336 AutoBlowerLevelIndication_Cmd_IS "1";
BA_ "SystemSignalLongSymbol" SG_ 2432637336 AutoBlowerLevelIndication_Cmd_IS "AutoBlowerLevelIndication_Cmd_ISig_5";
BA_ "GenSigCycleTime" SG_ 2432637336 PHMaintenanceService_stat_ISig_5 100;
BA_ "GenSigCycleTimeActive" SG_ 2432637336 PHMaintenanceService_stat_ISig_5 100;
BA_ "GenSigStartValue" SG_ 2432637336 PHMaintenanceService_stat_ISig_5 3;
BA_ "GenSigCycleTime" SG_ 2432637336 MemoDisplayIndication_Cmd_ISig_5 100;
BA_ "GenSigCycleTimeActive" SG_ 2432637336 MemoDisplayIndication_Cmd_ISig_5 100;
BA_ "GenSigStartValue" SG_ 2432637336 MemoDisplayIndication_Cmd_ISig_5 7;
BA_ "GenSigMaxLatency" SG_ 2432637336 MemoDisplayIndication_Cmd_ISig_5 26;
BA_ "SeToolAncestorID_SIGNAL" SG_ 2432637336 MemoDisplayIndication_Cmd_ISig_5 "x0000001D044050F4";
BA_ "SeToolItemID_SIGNAL" SG_ 2432637336 MemoDisplayIndication_Cmd_ISig_5 "x0000001D044050F4";
BA_ "SeToolName_SIGNAL" SG_ 2432637336 MemoDisplayIndication_Cmd_ISig_5 "Memo_Status";
BA_ "SeToolVersion_SIGNAL" SG_ 2432637336 MemoDisplayIndication_Cmd_ISig_5 "1";
BA_ "GenSigCycleTime" SG_ 2432637336 ACCoolingFanSpeedRequest_CCM 100;
BA_ "GenSigCycleTimeActive" SG_ 2432637336 ACCoolingFanSpeedRequest_CCM 100;
BA_ "GenSigStartValue" SG_ 2432637336 ACCoolingFanSpeedRequest_CCM 65535;
BA_ "NeedsUpdateBit" SG_ 2432637336 ACCoolingFanSpeedRequest_CCM 1;
BA_ "GenSigCycleTime" SG_ 2432637336 TemperatureRqstIndication_cmd_IS 100;
BA_ "GenSigCycleTimeActive" SG_ 2432637336 TemperatureRqstIndication_cmd_IS 100;
BA_ "GenSigStartValue" SG_ 2432637336 TemperatureRqstIndication_cmd_IS 31;
BA_ "GenSigMaxLatency" SG_ 2432637336 TemperatureRqstIndication_cmd_IS 26;
BA_ "SeToolAncestorID_SIGNAL" SG_ 2432637336 TemperatureRqstIndication_cmd_IS "x0000001D04150607";
BA_ "SeToolItemID_SIGNAL" SG_ 2432637336 TemperatureRqstIndication_cmd_IS "x0000001D043FAF4A";
BA_ "SeToolName_SIGNAL" SG_ 2432637336 TemperatureRqstIndication_cmd_IS "TemperatureRqstIndication_cmd ";
BA_ "SeToolVersion_SIGNAL" SG_ 2432637336 TemperatureRqstIndication_cmd_IS "4";
BA_ "SystemSignalLongSymbol" SG_ 2432637336 TemperatureRqstIndication_cmd_IS "TemperatureRqstIndication_cmd_ISig_5";
BA_ "GenSigCycleTime" SG_ 2432637336 Area_9level_Indication_cmd_ISig_ 100;
BA_ "GenSigCycleTimeActive" SG_ 2432637336 Area_9level_Indication_cmd_ISig_ 100;
BA_ "GenSigStartValue" SG_ 2432637336 Area_9level_Indication_cmd_ISig_ 15;
BA_ "GenSigMaxLatency" SG_ 2432637336 Area_9level_Indication_cmd_ISig_ 26;
BA_ "SeToolAncestorID_SIGNAL" SG_ 2432637336 Area_9level_Indication_cmd_ISig_ "x0000001D0438D144";
BA_ "SeToolItemID_SIGNAL" SG_ 2432637336 Area_9level_Indication_cmd_ISig_ "x0000001D0438D144";
BA_ "SeToolName_SIGNAL" SG_ 2432637336 Area_9level_Indication_cmd_ISig_ "Area_9level_Indication_cmd";
BA_ "SeToolVersion_SIGNAL" SG_ 2432637336 Area_9level_Indication_cmd_ISig_ "1";
BA_ "SystemSignalLongSymbol" SG_ 2432637336 Area_9level_Indication_cmd_ISig_ "Area_9level_Indication_cmd_ISig_5";
BA_ "GenSigCycleTime" SG_ 2432637336 MirrorHeatNormModeBtn_stat_ISig_ 100;
BA_ "GenSigCycleTimeActive" SG_ 2432637336 MirrorHeatNormModeBtn_stat_ISig_ 100;
BA_ "GenSigStartValue" SG_ 2432637336 MirrorHeatNormModeBtn_stat_ISig_ 3;
BA_ "GenSigMaxLatency" SG_ 2432637336 MirrorHeatNormModeBtn_stat_ISig_ 26;
BA_ "SeToolAncestorID_SIGNAL" SG_ 2432637336 MirrorHeatNormModeBtn_stat_ISig_ "x0000001D0423D932";
BA_ "SeToolItemID_SIGNAL" SG_ 2432637336 MirrorHeatNormModeBtn_stat_ISig_ "x0000001D0429669B";
BA_ "SeToolName_SIGNAL" SG_ 2432637336 MirrorHeatNormModeBtn_stat_ISig_ "EM_MirrorHeatNormalMode_ButtonStatus";
BA_ "SeToolVersion_SIGNAL" SG_ 2432637336 MirrorHeatNormModeBtn_stat_ISig_ "4";
BA_ "SystemSignalLongSymbol" SG_ 2432637336 MirrorHeatNormModeBtn_stat_ISig_ "MirrorHeatNormModeBtn_stat_ISig_5";
BA_ "GenSigCycleTime" SG_ 2432637336 AutoDefogIndication_Cmd_ISig_5 100;
BA_ "GenSigCycleTimeActive" SG_ 2432637336 AutoDefogIndication_Cmd_ISig_5 100;
BA_ "GenSigStartValue" SG_ 2432637336 AutoDefogIndication_Cmd_ISig_5 7;
BA_ "GenSigMaxLatency" SG_ 2432637336 AutoDefogIndication_Cmd_ISig_5 26;
BA_ "SeToolAncestorID_SIGNAL" SG_ 2432637336 AutoDefogIndication_Cmd_ISig_5 "x0000001D0441080E";
BA_ "SeToolItemID_SIGNAL" SG_ 2432637336 AutoDefogIndication_Cmd_ISig_5 "x0000001D0441080E";
BA_ "SeToolName_SIGNAL" SG_ 2432637336 AutoDefogIndication_Cmd_ISig_5 "AutoDefogmode_Status";
BA_ "SeToolVersion_SIGNAL" SG_ 2432637336 AutoDefogIndication_Cmd_ISig_5 "1";
BA_ "GenSigCycleTime" SG_ 2432637336 AutoMode_IndicationCmd_ISig_5 100;
BA_ "GenSigCycleTimeActive" SG_ 2432637336 AutoMode_IndicationCmd_ISig_5 100;
BA_ "GenSigMaxLatency" SG_ 2432637336 AutoMode_IndicationCmd_ISig_5 26;
BA_ "SeToolAncestorID_SIGNAL" SG_ 2432637336 AutoMode_IndicationCmd_ISig_5 "x0000001D04405ABB";
BA_ "SeToolItemID_SIGNAL" SG_ 2432637336 AutoMode_IndicationCmd_ISig_5 "x0000001D04405ABB";
BA_ "SeToolName_SIGNAL" SG_ 2432637336 AutoMode_IndicationCmd_ISig_5 "AutoMode_IndicationCmd";
BA_ "SeToolVersion_SIGNAL" SG_ 2432637336 AutoMode_IndicationCmd_ISig_5 "1";
BA_ "GenSigCycleTime" SG_ 2432637336 ACdisplayIndication_Cmd_ISig_5 100;
BA_ "GenSigCycleTimeActive" SG_ 2432637336 ACdisplayIndication_Cmd_ISig_5 100;
BA_ "GenSigStartValue" SG_ 2432637336 ACdisplayIndication_Cmd_ISig_5 7;
BA_ "GenSigMaxLatency" SG_ 2432637336 ACdisplayIndication_Cmd_ISig_5 26;
BA_ "SeToolAncestorID_SIGNAL" SG_ 2432637336 ACdisplayIndication_Cmd_ISig_5 "x0000001D0441084F";
BA_ "SeToolItemID_SIGNAL" SG_ 2432637336 ACdisplayIndication_Cmd_ISig_5 "x0000001D0441084F";
BA_ "SeToolName_SIGNAL" SG_ 2432637336 ACdisplayIndication_Cmd_ISig_5 "ACmode_Status";
BA_ "SeToolVersion_SIGNAL" SG_ 2432637336 ACdisplayIndication_Cmd_ISig_5 "1";
BA_ "GenSigSendType" SG_ 2633994283 AnmSig_WRCS_CabSubnet 1;
BA_ "GenSigCycleTime" SG_ 2633994283 AnmSig_WRCS_CabSubnet 100;
BA_ "GenSigCycleTimeActive" SG_ 2633994283 AnmSig_WRCS_CabSubnet 100;
BA_ "MmAnSignal" SG_ 2633994283 AnmSig_WRCS_CabSubnet 1;
BA_ "GenSigSendType" SG_ 2633994282 AnmSig_SRS_CabSubnet 1;
BA_ "GenSigCycleTime" SG_ 2633994282 AnmSig_SRS_CabSubnet 100;
BA_ "GenSigCycleTimeActive" SG_ 2633994282 AnmSig_SRS_CabSubnet 100;
BA_ "MmAnSignal" SG_ 2633994282 AnmSig_SRS_CabSubnet 1;
BA_ "GenSigSendType" SG_ 2633994280 AnmSig_LECM1_CabSubnet 1;
BA_ "GenSigCycleTime" SG_ 2633994280 AnmSig_LECM1_CabSubnet 100;
BA_ "GenSigCycleTimeActive" SG_ 2633994280 AnmSig_LECM1_CabSubnet 100;
BA_ "MmAnSignal" SG_ 2633994280 AnmSig_LECM1_CabSubnet 1;
BA_ "GenSigSendType" SG_ 2633994320 AnmSig_ECUspare6_CabSubnet 1;
BA_ "GenSigCycleTime" SG_ 2633994320 AnmSig_ECUspare6_CabSubnet 100;
BA_ "GenSigCycleTimeActive" SG_ 2633994320 AnmSig_ECUspare6_CabSubnet 100;
BA_ "MmAnSignal" SG_ 2633994320 AnmSig_ECUspare6_CabSubnet 1;
BA_ "GenSigSendType" SG_ 2633994278 AnmSig_CIOM_CabSubnet 1;
BA_ "GenSigCycleTime" SG_ 2633994278 AnmSig_CIOM_CabSubnet 100;
BA_ "GenSigCycleTimeActive" SG_ 2633994278 AnmSig_CIOM_CabSubnet 100;
BA_ "MmAnSignal" SG_ 2633994278 AnmSig_CIOM_CabSubnet 1;
BA_ "GenSigSendType" SG_ 2633994277 AnmSig_CCM_CabSubnet 1;
BA_ "GenSigCycleTime" SG_ 2633994277 AnmSig_CCM_CabSubnet 100;
BA_ "GenSigCycleTimeActive" SG_ 2633994277 AnmSig_CCM_CabSubnet 100;
BA_ "MmAnSignal" SG_ 2633994277 AnmSig_CCM_CabSubnet 1;
BA_REL_ "GenSigFirstTimeoutTime" BU_SG_REL_ CCM SG_ 2432651584 ParkHeaterTimerReleased_stat_ISi 3000;
BA_REL_ "GenSigTimeoutTime" BU_SG_REL_ CCM SG_ 2432651584 ParkHeaterTimerReleased_stat_ISi 120;
BA_REL_ "GenSigFirstTimeoutTime" BU_SG_REL_ CCM SG_ 2432651584 Washing_HMI_rqst_ISig_5 3000;
BA_REL_ "GenSigTimeoutTime" BU_SG_REL_ CCM SG_ 2432651584 Washing_HMI_rqst_ISig_5 120;
BA_REL_ "GenSigFirstTimeoutTime" BU_SG_REL_ CCM SG_ 2432651584 BunkH2ParkHeater_ButtonStatus 3000;
BA_REL_ "GenSigTimeoutTime" BU_SG_REL_ CCM SG_ 2432651584 BunkH2ParkHeater_ButtonStatus 120;
BA_REL_ "GenSigFirstTimeoutTime" BU_SG_REL_ CCM SG_ 2432651584 BunkBTempDec_ButtonStatus 3000;
BA_REL_ "GenSigTimeoutTime" BU_SG_REL_ CCM SG_ 2432651584 BunkBTempDec_ButtonStatus 120;
BA_REL_ "GenSigFirstTimeoutTime" BU_SG_REL_ CCM SG_ 2432651584 BunkH2TempDec_ButtonStatus 3000;
BA_REL_ "GenSigTimeoutTime" BU_SG_REL_ CCM SG_ 2432651584 BunkH2TempDec_ButtonStatus 120;
BA_REL_ "GenSigFirstTimeoutTime" BU_SG_REL_ CCM SG_ 2432651584 BunkH2PHTimer_rqst_StartTimeMin 3000;
BA_REL_ "GenSigTimeoutTime" BU_SG_REL_ CCM SG_ 2432651584 BunkH2PHTimer_rqst_StartTimeMin 120;
BA_REL_ "GenSigFirstTimeoutTime" BU_SG_REL_ CCM SG_ 2432651584 BunkH2PHTimer_rqst_DurnTimeMin 3000;
BA_REL_ "GenSigTimeoutTime" BU_SG_REL_ CCM SG_ 2432651584 BunkH2PHTimer_rqst_DurnTimeMin 120;
BA_REL_ "GenSigFirstTimeoutTime" BU_SG_REL_ CCM SG_ 2432651584 BunkBParkHeater_ButtonStatus 3000;
BA_REL_ "GenSigTimeoutTime" BU_SG_REL_ CCM SG_ 2432651584 BunkBParkHeater_ButtonStatus 120;
BA_REL_ "GenSigFirstTimeoutTime" BU_SG_REL_ CCM SG_ 2432651584 BunkH2PHTimer_rqst_StartTimeHr 3000;
BA_REL_ "GenSigTimeoutTime" BU_SG_REL_ CCM SG_ 2432651584 BunkH2PHTimer_rqst_StartTimeHr 120;
BA_REL_ "GenSigFirstTimeoutTime" BU_SG_REL_ CCM SG_ 2432651584 BunkH2PHTimer_rqst_DurnTimeHr 3000;
BA_REL_ "GenSigTimeoutTime" BU_SG_REL_ CCM SG_ 2432651584 BunkH2PHTimer_rqst_DurnTimeHr 120;
BA_REL_ "GenSigFirstTimeoutTime" BU_SG_REL_ CCM SG_ 2432651584 BunkBTempInc_ButtonStatus 3000;
BA_REL_ "GenSigTimeoutTime" BU_SG_REL_ CCM SG_ 2432651584 BunkBTempInc_ButtonStatus 120;
BA_REL_ "GenSigFirstTimeoutTime" BU_SG_REL_ LECM1 SG_ 2432651584 AudioSystemStatus_ISig_5 3000;
BA_REL_ "GenSigTimeoutTime" BU_SG_REL_ LECM1 SG_ 2432651584 AudioSystemStatus_ISig_5 120;
BA_REL_ "GenSigFirstTimeoutTime" BU_SG_REL_ CCM SG_ 2432651584 ParkingHeaterCleaning_cmd_ISig_5 3000;
BA_REL_ "GenSigTimeoutTime" BU_SG_REL_ CCM SG_ 2432651584 ParkingHeaterCleaning_cmd_ISig_5 120;
BA_REL_ "GenSigFirstTimeoutTime" BU_SG_REL_ CCM SG_ 2432651584 PtosStatus_ISig_5 3000;
BA_REL_ "GenSigTimeoutTime" BU_SG_REL_ CCM SG_ 2432651584 PtosStatus_ISig_5 500;
BA_REL_ "GenSigFirstTimeoutTime" BU_SG_REL_ CCM SG_ 2432651584 BunkB1ParkHeaterBtn_stat 3000;
BA_REL_ "GenSigTimeoutTime" BU_SG_REL_ CCM SG_ 2432651584 BunkB1ParkHeaterBtn_stat 120;
BA_REL_ "GenSigFirstTimeoutTime" BU_SG_REL_ CCM SG_ 2432651584 BunkH2PHTimer_rqst_Timer_cmd 3000;
BA_REL_ "GenSigTimeoutTime" BU_SG_REL_ CCM SG_ 2432651584 BunkH2PHTimer_rqst_Timer_cmd 120;
BA_REL_ "GenSigFirstTimeoutTime" BU_SG_REL_ CCM SG_ 2431745856 BacklightCmd_ISig_5 3000;
BA_REL_ "GenSigTimeoutTime" BU_SG_REL_ CCM SG_ 2431745856 BacklightCmd_ISig_5 60;
BA_REL_ "GenSigFirstTimeoutTime" BU_SG_REL_ WRCS SG_ 2431745856 EngineSpeed_ISig_5 3000;
BA_REL_ "GenSigTimeoutTime" BU_SG_REL_ WRCS SG_ 2431745856 EngineSpeed_ISig_5 500;
BA_REL_ "GenSigFirstTimeoutTime" BU_SG_REL_ CCM SG_ 2431745856 EngineSpeed_ISig_5 3000;
BA_REL_ "GenSigTimeoutTime" BU_SG_REL_ CCM SG_ 2431745856 EngineSpeed_ISig_5 500;
BA_REL_ "GenSigFirstTimeoutTime" BU_SG_REL_ SRS SG_ 2431745856 EngineSpeed_ISig_5 3000;
BA_REL_ "GenSigTimeoutTime" BU_SG_REL_ SRS SG_ 2431745856 EngineSpeed_ISig_5 500;
BA_REL_ "GenSigFirstTimeoutTime" BU_SG_REL_ LECM1 SG_ 2431745856 PresetIndicationCmd_ISig_5 3000;
BA_REL_ "GenSigTimeoutTime" BU_SG_REL_ LECM1 SG_ 2431745856 PresetIndicationCmd_ISig_5 60;
BA_REL_ "GenSigFirstTimeoutTime" BU_SG_REL_ WRCS SG_ 2431745856 VehicleMode_ISig_5 3000;
BA_REL_ "GenSigTimeoutTime" BU_SG_REL_ WRCS SG_ 2431745856 VehicleMode_ISig_5 500;
BA_REL_ "GenSigFirstTimeoutTime" BU_SG_REL_ LECM1 SG_ 2431745856 VehicleMode_ISig_5 3000;
BA_REL_ "GenSigTimeoutTime" BU_SG_REL_ LECM1 SG_ 2431745856 VehicleMode_ISig_5 500;
BA_REL_ "GenSigFirstTimeoutTime" BU_SG_REL_ CCM SG_ 2431745856 VehicleMode_ISig_5 3000;
BA_REL_ "GenSigTimeoutTime" BU_SG_REL_ CCM SG_ 2431745856 VehicleMode_ISig_5 500;
BA_REL_ "GenSigFirstTimeoutTime" BU_SG_REL_ SRS SG_ 2431745856 VehicleMode_ISig_5 3000;
BA_REL_ "GenSigTimeoutTime" BU_SG_REL_ SRS SG_ 2431745856 VehicleMode_ISig_5 500;
BA_REL_ "GenSigFirstTimeoutTime" BU_SG_REL_ CCM SG_ 2431745856 BunkH2OnOFF_ButtonStatus 3000;
BA_REL_ "GenSigTimeoutTime" BU_SG_REL_ CCM SG_ 2431745856 BunkH2OnOFF_ButtonStatus 60;
BA_REL_ "GenSigFirstTimeoutTime" BU_SG_REL_ LECM1 SG_ 2431745856 IntLghtModeInd_cmd_EventFlag 3000;
BA_REL_ "GenSigTimeoutTime" BU_SG_REL_ LECM1 SG_ 2431745856 IntLghtModeInd_cmd_EventFlag 60;
BA_REL_ "GenSigFirstTimeoutTime" BU_SG_REL_ WRCS SG_ 2431745856 LevelControlInformation_ISig_5 3000;
BA_REL_ "GenSigTimeoutTime" BU_SG_REL_ WRCS SG_ 2431745856 LevelControlInformation_ISig_5 500;
BA_REL_ "GenSigFirstTimeoutTime" BU_SG_REL_ CCM SG_ 2431745856 WheelBasedVehicleSpeed_ISig_5 3000;
BA_REL_ "GenSigTimeoutTime" BU_SG_REL_ CCM SG_ 2431745856 WheelBasedVehicleSpeed_ISig_5 60;
BA_REL_ "GenSigFirstTimeoutTime" BU_SG_REL_ SRS SG_ 2431745856 WheelBasedVehicleSpeed_ISig_5 3000;
BA_REL_ "GenSigTimeoutTime" BU_SG_REL_ SRS SG_ 2431745856 WheelBasedVehicleSpeed_ISig_5 60;
BA_REL_ "GenSigFirstTimeoutTime" BU_SG_REL_ WRCS SG_ 2431745856 WheelBasedVehicleSpeed_ISig_5 3000;
BA_REL_ "GenSigTimeoutTime" BU_SG_REL_ WRCS SG_ 2431745856 WheelBasedVehicleSpeed_ISig_5 60;
BA_REL_ "GenSigFirstTimeoutTime" BU_SG_REL_ LECM1 SG_ 2431745856 IntLghtModeInd_cmd_IL_Mode 3000;
BA_REL_ "GenSigTimeoutTime" BU_SG_REL_ LECM1 SG_ 2431745856 IntLghtModeInd_cmd_IL_Mode 60;
BA_REL_ "GenSigFirstTimeoutTime" BU_SG_REL_ CCM SG_ 2432650304 EngineCoolantTemp_stat_ISig_5 3000;
BA_REL_ "GenSigTimeoutTime" BU_SG_REL_ CCM SG_ 2432650304 EngineCoolantTemp_stat_ISig_5 120;
BA_REL_ "GenSigFirstTimeoutTime" BU_SG_REL_ SRS SG_ 2432650304 DriverSeatBeltSwitch_ISig_5 3000;
BA_REL_ "GenSigTimeoutTime" BU_SG_REL_ SRS SG_ 2432650304 DriverSeatBeltSwitch_ISig_5 120;
BA_REL_ "GenSigFirstTimeoutTime" BU_SG_REL_ LECM1 SG_ 2432650304 AmbientAirTemperature_ISig_5 3000;
BA_REL_ "GenSigTimeoutTime" BU_SG_REL_ LECM1 SG_ 2432650304 AmbientAirTemperature_ISig_5 120;
BA_REL_ "GenSigFirstTimeoutTime" BU_SG_REL_ CCM SG_ 2432650304 AmbientAirTemperature_ISig_5 3000;
BA_REL_ "GenSigTimeoutTime" BU_SG_REL_ CCM SG_ 2432650304 AmbientAirTemperature_ISig_5 120;
BA_REL_ "GenSigFirstTimeoutTime" BU_SG_REL_ WRCS SG_ 2432650304 AmbientAirTemperature_ISig_5 3000;
BA_REL_ "GenSigTimeoutTime" BU_SG_REL_ WRCS SG_ 2432650304 AmbientAirTemperature_ISig_5 120;
BA_REL_ "GenSigFirstTimeoutTime" BU_SG_REL_ SRS SG_ 2432650304 AmbientAirTemperature_ISig_5 3000;
BA_REL_ "GenSigTimeoutTime" BU_SG_REL_ SRS SG_ 2432650304 AmbientAirTemperature_ISig_5 120;
BA_REL_ "GenSigFirstTimeoutTime" BU_SG_REL_ CCM SG_ 2432650304 DriverMemory_rqst_ISig_5 3000;
BA_REL_ "GenSigTimeoutTime" BU_SG_REL_ CCM SG_ 2432650304 DriverMemory_rqst_ISig_5 120;
BA_REL_ "GenSigFirstTimeoutTime" BU_SG_REL_ CCM SG_ 2432650304 ReverseGearEngaged_ISig_5 3000;
BA_REL_ "GenSigTimeoutTime" BU_SG_REL_ CCM SG_ 2432650304 ReverseGearEngaged_ISig_5 120;
BA_REL_ "GenSigFirstTimeoutTime" BU_SG_REL_ CCM SG_ 2432650304 AutoBlowerLevel_Selection_ISig_5 3000;
BA_REL_ "GenSigTimeoutTime" BU_SG_REL_ CCM SG_ 2432650304 AutoBlowerLevel_Selection_ISig_5 120;
BA_REL_ "GenSigFirstTimeoutTime" BU_SG_REL_ CCM SG_ 2432650304 AutoDefogmode_Selection_ISig_5 3000;
BA_REL_ "GenSigTimeoutTime" BU_SG_REL_ CCM SG_ 2432650304 AutoDefogmode_Selection_ISig_5 120;
BA_REL_ "GenSigFirstTimeoutTime" BU_SG_REL_ WRCS SG_ 2432650304 ECSStandbyActive 3000;
BA_REL_ "GenSigTimeoutTime" BU_SG_REL_ WRCS SG_ 2432650304 ECSStandbyActive 120;
BA_REL_ "GenSigFirstTimeoutTime" BU_SG_REL_ CCM SG_ 2432650304 ACMode_Selection_ISig_5 3000;
BA_REL_ "GenSigTimeoutTime" BU_SG_REL_ CCM SG_ 2432650304 ACMode_Selection_ISig_5 120;
BA_REL_ "GenSigFirstTimeoutTime" BU_SG_REL_ WRCS SG_ 2432650304 HeightAdjustmentAllowed_ISig_5 3000;
BA_REL_ "GenSigTimeoutTime" BU_SG_REL_ WRCS SG_ 2432650304 HeightAdjustmentAllowed_ISig_5 120;
BA_REL_ "GenSigFirstTimeoutTime" BU_SG_REL_ CCM SG_ 2432650304 AQSMode_Selection_ISig_5 3000;
BA_REL_ "GenSigTimeoutTime" BU_SG_REL_ CCM SG_ 2432650304 AQSMode_Selection_ISig_5 120;
BA_REL_ "GenSigFirstTimeoutTime" BU_SG_REL_ LECM1 SG_ 2432650304 SelectedTimeFormat_stat_ISig_5 3000;
BA_REL_ "GenSigTimeoutTime" BU_SG_REL_ LECM1 SG_ 2432650304 SelectedTimeFormat_stat_ISig_5 120;
BA_REL_ "GenSigFirstTimeoutTime" BU_SG_REL_ WRCS SG_ 2432650304 SelectedWeightUnit_stat_ISig_5 3000;
BA_REL_ "GenSigTimeoutTime" BU_SG_REL_ WRCS SG_ 2432650304 SelectedWeightUnit_stat_ISig_5 120;
BA_REL_ "GenSigFirstTimeoutTime" BU_SG_REL_ CCM SG_ 2432650304 FuncIndIlluminationLevel_ISig_5 3000;
BA_REL_ "GenSigTimeoutTime" BU_SG_REL_ CCM SG_ 2432650304 FuncIndIlluminationLevel_ISig_5 120;
BA_REL_ "GenSigFirstTimeoutTime" BU_SG_REL_ CCM SG_ 2432650304 WiperModeStatus_ISig_5 3000;
BA_REL_ "GenSigTimeoutTime" BU_SG_REL_ CCM SG_ 2432650304 WiperModeStatus_ISig_5 120;
BA_REL_ "GenSigFirstTimeoutTime" BU_SG_REL_ CCM SG_ 2432650304 MirrorHeatingMode_ISig_5 3000;
BA_REL_ "GenSigTimeoutTime" BU_SG_REL_ CCM SG_ 2432650304 MirrorHeatingMode_ISig_5 120;
BA_REL_ "GenSigFirstTimeoutTime" BU_SG_REL_ CIOM SG_ 2432640664 PHTimer2_stat_Recurrence_ISig_5 3000;
BA_REL_ "GenSigTimeoutTime" BU_SG_REL_ CIOM SG_ 2432640664 PHTimer2_stat_Recurrence_ISig_5 500;
BA_REL_ "GenSigFirstTimeoutTime" BU_SG_REL_ LECM1 SG_ 2432640664 PHTimer2_stat_Recurrence_ISig_5 3000;
BA_REL_ "GenSigTimeoutTime" BU_SG_REL_ LECM1 SG_ 2432640664 PHTimer2_stat_Recurrence_ISig_5 500;
BA_REL_ "GenSigFirstTimeoutTime" BU_SG_REL_ LECM1 SG_ 2432640664 PHTimer2_stat_Hours_ISig_5 3000;
BA_REL_ "GenSigTimeoutTime" BU_SG_REL_ LECM1 SG_ 2432640664 PHTimer2_stat_Hours_ISig_5 500;
BA_REL_ "GenSigFirstTimeoutTime" BU_SG_REL_ CIOM SG_ 2432640664 PHTimer2_stat_Hours_ISig_5 3000;
BA_REL_ "GenSigTimeoutTime" BU_SG_REL_ CIOM SG_ 2432640664 PHTimer2_stat_Hours_ISig_5 500;
BA_REL_ "GenSigFirstTimeoutTime" BU_SG_REL_ LECM1 SG_ 2432640664 PHTimer3_stat_Temp_ISig_5 3000;
BA_REL_ "GenSigTimeoutTime" BU_SG_REL_ LECM1 SG_ 2432640664 PHTimer3_stat_Temp_ISig_5 500;
BA_REL_ "GenSigFirstTimeoutTime" BU_SG_REL_ CIOM SG_ 2432640664 PHTimer3_stat_Temp_ISig_5 3000;
BA_REL_ "GenSigTimeoutTime" BU_SG_REL_ CIOM SG_ 2432640664 PHTimer3_stat_Temp_ISig_5 500;
BA_REL_ "GenSigFirstTimeoutTime" BU_SG_REL_ CIOM SG_ 2432640664 PHTimer3_stat_Hours_ISig_5 3000;
BA_REL_ "GenSigTimeoutTime" BU_SG_REL_ CIOM SG_ 2432640664 PHTimer3_stat_Hours_ISig_5 500;
BA_REL_ "GenSigFirstTimeoutTime" BU_SG_REL_ LECM1 SG_ 2432640664 PHTimer3_stat_Hours_ISig_5 3000;
BA_REL_ "GenSigTimeoutTime" BU_SG_REL_ LECM1 SG_ 2432640664 PHTimer3_stat_Hours_ISig_5 500;
BA_REL_ "GenSigFirstTimeoutTime" BU_SG_REL_ CIOM SG_ 2432640664 PHTimer3_stat_Status_ISig_5 3000;
BA_REL_ "GenSigTimeoutTime" BU_SG_REL_ CIOM SG_ 2432640664 PHTimer3_stat_Status_ISig_5 500;
BA_REL_ "GenSigFirstTimeoutTime" BU_SG_REL_ LECM1 SG_ 2432640664 PHTimer3_stat_Status_ISig_5 3000;
BA_REL_ "GenSigTimeoutTime" BU_SG_REL_ LECM1 SG_ 2432640664 PHTimer3_stat_Status_ISig_5 500;
BA_REL_ "GenSigFirstTimeoutTime" BU_SG_REL_ CIOM SG_ 2432640664 PHTimer2_stat_StartDay_ISig_5 3000;
BA_REL_ "GenSigTimeoutTime" BU_SG_REL_ CIOM SG_ 2432640664 PHTimer2_stat_StartDay_ISig_5 500;
BA_REL_ "GenSigFirstTimeoutTime" BU_SG_REL_ LECM1 SG_ 2432640664 PHTimer2_stat_StartDay_ISig_5 3000;
BA_REL_ "GenSigTimeoutTime" BU_SG_REL_ LECM1 SG_ 2432640664 PHTimer2_stat_StartDay_ISig_5 500;
BA_REL_ "GenSigFirstTimeoutTime" BU_SG_REL_ CIOM SG_ 2432640664 PHTimer2_stat_Temp_ISig_5 3000;
BA_REL_ "GenSigTimeoutTime" BU_SG_REL_ CIOM SG_ 2432640664 PHTimer2_stat_Temp_ISig_5 500;
BA_REL_ "GenSigFirstTimeoutTime" BU_SG_REL_ LECM1 SG_ 2432640664 PHTimer2_stat_Temp_ISig_5 3000;
BA_REL_ "GenSigTimeoutTime" BU_SG_REL_ LECM1 SG_ 2432640664 PHTimer2_stat_Temp_ISig_5 500;
BA_REL_ "GenSigFirstTimeoutTime" BU_SG_REL_ LECM1 SG_ 2432640664 PHTimer2_stat_Status_ISig_5 3000;
BA_REL_ "GenSigTimeoutTime" BU_SG_REL_ LECM1 SG_ 2432640664 PHTimer2_stat_Status_ISig_5 500;
BA_REL_ "GenSigFirstTimeoutTime" BU_SG_REL_ CIOM SG_ 2432640664 PHTimer2_stat_Status_ISig_5 3000;
BA_REL_ "GenSigTimeoutTime" BU_SG_REL_ CIOM SG_ 2432640664 PHTimer2_stat_Status_ISig_5 500;
BA_REL_ "GenSigFirstTimeoutTime" BU_SG_REL_ LECM1 SG_ 2432640664 PHTimer2_stat_Minutes_ISig_5 3000;
BA_REL_ "GenSigTimeoutTime" BU_SG_REL_ LECM1 SG_ 2432640664 PHTimer2_stat_Minutes_ISig_5 500;
BA_REL_ "GenSigFirstTimeoutTime" BU_SG_REL_ CIOM SG_ 2432640664 PHTimer2_stat_Minutes_ISig_5 3000;
BA_REL_ "GenSigTimeoutTime" BU_SG_REL_ CIOM SG_ 2432640664 PHTimer2_stat_Minutes_ISig_5 500;
BA_REL_ "GenSigFirstTimeoutTime" BU_SG_REL_ CIOM SG_ 2432640664 PHTimer3_stat_Minutes_ISig_5 3000;
BA_REL_ "GenSigTimeoutTime" BU_SG_REL_ CIOM SG_ 2432640664 PHTimer3_stat_Minutes_ISig_5 500;
BA_REL_ "GenSigFirstTimeoutTime" BU_SG_REL_ LECM1 SG_ 2432640664 PHTimer3_stat_Minutes_ISig_5 3000;
BA_REL_ "GenSigTimeoutTime" BU_SG_REL_ LECM1 SG_ 2432640664 PHTimer3_stat_Minutes_ISig_5 500;
BA_REL_ "GenSigFirstTimeoutTime" BU_SG_REL_ LECM1 SG_ 2432640664 PHTimer3_stat_Recurrence_ISig_5 3000;
BA_REL_ "GenSigTimeoutTime" BU_SG_REL_ LECM1 SG_ 2432640664 PHTimer3_stat_Recurrence_ISig_5 500;
BA_REL_ "GenSigFirstTimeoutTime" BU_SG_REL_ CIOM SG_ 2432640664 PHTimer3_stat_Recurrence_ISig_5 3000;
BA_REL_ "GenSigTimeoutTime" BU_SG_REL_ CIOM SG_ 2432640664 PHTimer3_stat_Recurrence_ISig_5 500;
BA_REL_ "GenSigFirstTimeoutTime" BU_SG_REL_ CIOM SG_ 2432640664 PHTimer3_stat_StartDay_ISig_5 3000;
BA_REL_ "GenSigTimeoutTime" BU_SG_REL_ CIOM SG_ 2432640664 PHTimer3_stat_StartDay_ISig_5 500;
BA_REL_ "GenSigFirstTimeoutTime" BU_SG_REL_ LECM1 SG_ 2432640664 PHTimer3_stat_StartDay_ISig_5 3000;
BA_REL_ "GenSigTimeoutTime" BU_SG_REL_ LECM1 SG_ 2432640664 PHTimer3_stat_StartDay_ISig_5 500;
BA_REL_ "GenSigFirstTimeoutTime" BU_SG_REL_ CIOM SG_ 2432644760 ExtraHeating_status_ISig_5 3000;
BA_REL_ "GenSigTimeoutTime" BU_SG_REL_ CIOM SG_ 2432644760 ExtraHeating_status_ISig_5 300;
BA_REL_ "GenSigFirstTimeoutTime" BU_SG_REL_ LECM1 SG_ 2432644760 PHTimer1_stat_Minutes_ISig_5 3000;
BA_REL_ "GenSigTimeoutTime" BU_SG_REL_ LECM1 SG_ 2432644760 PHTimer1_stat_Minutes_ISig_5 500;
BA_REL_ "GenSigFirstTimeoutTime" BU_SG_REL_ CIOM SG_ 2432644760 PHTimer1_stat_Minutes_ISig_5 3000;
BA_REL_ "GenSigTimeoutTime" BU_SG_REL_ CIOM SG_ 2432644760 PHTimer1_stat_Minutes_ISig_5 500;
BA_REL_ "GenSigFirstTimeoutTime" BU_SG_REL_ CIOM SG_ 2432644760 ParkingClimate_IndicationCmd_ISi 3000;
BA_REL_ "GenSigTimeoutTime" BU_SG_REL_ CIOM SG_ 2432644760 ParkingClimate_IndicationCmd_ISi 300;
BA_REL_ "GenSigFirstTimeoutTime" BU_SG_REL_ CIOM SG_ 2432644760 ShortStopHeater_cmd_ISig_5 3000;
BA_REL_ "GenSigTimeoutTime" BU_SG_REL_ CIOM SG_ 2432644760 ShortStopHeater_cmd_ISig_5 300;
BA_REL_ "GenSigFirstTimeoutTime" BU_SG_REL_ LECM1 SG_ 2432644760 PHTimer1_stat_Status_ISig_5 3000;
BA_REL_ "GenSigTimeoutTime" BU_SG_REL_ LECM1 SG_ 2432644760 PHTimer1_stat_Status_ISig_5 500;
BA_REL_ "GenSigFirstTimeoutTime" BU_SG_REL_ CIOM SG_ 2432644760 PHTimer1_stat_Status_ISig_5 3000;
BA_REL_ "GenSigTimeoutTime" BU_SG_REL_ CIOM SG_ 2432644760 PHTimer1_stat_Status_ISig_5 500;
BA_REL_ "GenSigFirstTimeoutTime" BU_SG_REL_ LECM1 SG_ 2432644760 PHTimer1_stat_StartDay_ISig_5 3000;
BA_REL_ "GenSigTimeoutTime" BU_SG_REL_ LECM1 SG_ 2432644760 PHTimer1_stat_StartDay_ISig_5 500;
BA_REL_ "GenSigFirstTimeoutTime" BU_SG_REL_ CIOM SG_ 2432644760 PHTimer1_stat_StartDay_ISig_5 3000;
BA_REL_ "GenSigTimeoutTime" BU_SG_REL_ CIOM SG_ 2432644760 PHTimer1_stat_StartDay_ISig_5 500;
BA_REL_ "GenSigFirstTimeoutTime" BU_SG_REL_ LECM1 SG_ 2432644760 PHTimer1_stat_Duration_ISig_5 3000;
BA_REL_ "GenSigTimeoutTime" BU_SG_REL_ LECM1 SG_ 2432644760 PHTimer1_stat_Duration_ISig_5 500;
BA_REL_ "GenSigFirstTimeoutTime" BU_SG_REL_ CIOM SG_ 2432644760 PHTimer1_stat_Duration_ISig_5 3000;
BA_REL_ "GenSigTimeoutTime" BU_SG_REL_ CIOM SG_ 2432644760 PHTimer1_stat_Duration_ISig_5 500;
BA_REL_ "GenSigFirstTimeoutTime" BU_SG_REL_ LECM1 SG_ 2432644760 PHTimer1_stat_Temp_ISig_5 3000;
BA_REL_ "GenSigTimeoutTime" BU_SG_REL_ LECM1 SG_ 2432644760 PHTimer1_stat_Temp_ISig_5 500;
BA_REL_ "GenSigFirstTimeoutTime" BU_SG_REL_ CIOM SG_ 2432644760 PHTimer1_stat_Temp_ISig_5 3000;
BA_REL_ "GenSigTimeoutTime" BU_SG_REL_ CIOM SG_ 2432644760 PHTimer1_stat_Temp_ISig_5 500;
BA_REL_ "GenSigFirstTimeoutTime" BU_SG_REL_ CIOM SG_ 2432644760 PHTimer1_stat_Recurrence_ISig_5 3000;
BA_REL_ "GenSigTimeoutTime" BU_SG_REL_ CIOM SG_ 2432644760 PHTimer1_stat_Recurrence_ISig_5 500;
BA_REL_ "GenSigFirstTimeoutTime" BU_SG_REL_ LECM1 SG_ 2432644760 PHTimer1_stat_Recurrence_ISig_5 3000;
BA_REL_ "GenSigTimeoutTime" BU_SG_REL_ LECM1 SG_ 2432644760 PHTimer1_stat_Recurrence_ISig_5 500;
BA_REL_ "GenSigFirstTimeoutTime" BU_SG_REL_ LECM1 SG_ 2432644760 PHTimer1_stat_Hours_ISig_5 3000;
BA_REL_ "GenSigTimeoutTime" BU_SG_REL_ LECM1 SG_ 2432644760 PHTimer1_stat_Hours_ISig_5 500;
BA_REL_ "GenSigFirstTimeoutTime" BU_SG_REL_ CIOM SG_ 2432644760 PHTimer1_stat_Hours_ISig_5 3000;
BA_REL_ "GenSigTimeoutTime" BU_SG_REL_ CIOM SG_ 2432644760 PHTimer1_stat_Hours_ISig_5 500;
BA_REL_ "GenSigFirstTimeoutTime" BU_SG_REL_ CIOM SG_ 2432645496 AcCoolantPumpEngagementRequest_I 3000;
BA_REL_ "GenSigTimeoutTime" BU_SG_REL_ CIOM SG_ 2432645496 AcCoolantPumpEngagementRequest_I 120;
BA_REL_ "GenSigFirstTimeoutTime" BU_SG_REL_ CIOM SG_ 2432639640 ACmode_IndicationCmd_ISig_5 3000;
BA_REL_ "GenSigTimeoutTime" BU_SG_REL_ CIOM SG_ 2432639640 ACmode_IndicationCmd_ISig_5 120;
BA_REL_ "GenSigFirstTimeoutTime" BU_SG_REL_ CIOM SG_ 2432639640 PHTimer_rqst_SetAlarmOper_ISig_5 3000;
BA_REL_ "GenSigTimeoutTime" BU_SG_REL_ CIOM SG_ 2432639640 PHTimer_rqst_SetAlarmOper_ISig_5 120;
BA_REL_ "GenSigFirstTimeoutTime" BU_SG_REL_ CIOM SG_ 2432639640 PHTimer_rqst_Hours_ISig_5 3000;
BA_REL_ "GenSigTimeoutTime" BU_SG_REL_ CIOM SG_ 2432639640 PHTimer_rqst_Hours_ISig_5 120;
BA_REL_ "GenSigFirstTimeoutTime" BU_SG_REL_ CIOM SG_ 2432639640 PH_Activation_cmd_ISig_5 3000;
BA_REL_ "GenSigTimeoutTime" BU_SG_REL_ CIOM SG_ 2432639640 PH_Activation_cmd_ISig_5 120;
BA_REL_ "GenSigFirstTimeoutTime" BU_SG_REL_ CIOM SG_ 2432639640 PHTimer_rqst_Minutes_ISig_5 3000;
BA_REL_ "GenSigTimeoutTime" BU_SG_REL_ CIOM SG_ 2432639640 PHTimer_rqst_Minutes_ISig_5 120;
BA_REL_ "GenSigFirstTimeoutTime" BU_SG_REL_ CIOM SG_ 2432639640 CabInteriorTempVentilated_Stat_I 3000;
BA_REL_ "GenSigTimeoutTime" BU_SG_REL_ CIOM SG_ 2432639640 CabInteriorTempVentilated_Stat_I 120;
BA_REL_ "GenSigFirstTimeoutTime" BU_SG_REL_ CIOM SG_ 2432639640 ParkingHeaterCleaning_Rqst_ISig_ 3000;
BA_REL_ "GenSigTimeoutTime" BU_SG_REL_ CIOM SG_ 2432639640 ParkingHeaterCleaning_Rqst_ISig_ 120;
BA_REL_ "GenSigFirstTimeoutTime" BU_SG_REL_ LECM1 SG_ 2432639640 ParkingHeater_IndicationCmd_ISig 3000;
BA_REL_ "GenSigTimeoutTime" BU_SG_REL_ LECM1 SG_ 2432639640 ParkingHeater_IndicationCmd_ISig 120;
BA_REL_ "GenSigFirstTimeoutTime" BU_SG_REL_ CIOM SG_ 2432639640 ParkingHeater_IndicationCmd_ISig 3000;
BA_REL_ "GenSigTimeoutTime" BU_SG_REL_ CIOM SG_ 2432639640 ParkingHeater_IndicationCmd_ISig 120;
BA_REL_ "GenSigFirstTimeoutTime" BU_SG_REL_ CIOM SG_ 2432639640 AC_CompressorClutchCmd_ISig_5 3000;
BA_REL_ "GenSigTimeoutTime" BU_SG_REL_ CIOM SG_ 2432639640 AC_CompressorClutchCmd_ISig_5 120;
BA_REL_ "GenSigFirstTimeoutTime" BU_SG_REL_ CIOM SG_ 2432639640 PHTimer_rqst_DayOfWeekRq_ISig_5 3000;
BA_REL_ "GenSigTimeoutTime" BU_SG_REL_ CIOM SG_ 2432639640 PHTimer_rqst_DayOfWeekRq_ISig_5 120;
BA_REL_ "GenSigFirstTimeoutTime" BU_SG_REL_ CIOM SG_ 2432633752 EngineTimer_stat_Timer2StartDay_ 3000;
BA_REL_ "GenSigTimeoutTime" BU_SG_REL_ CIOM SG_ 2432633752 EngineTimer_stat_Timer2StartDay_ 500;
BA_REL_ "GenSigFirstTimeoutTime" BU_SG_REL_ CIOM SG_ 2432633752 EngineTimer_stat_Timer1Recurr_IS 3000;
BA_REL_ "GenSigTimeoutTime" BU_SG_REL_ CIOM SG_ 2432633752 EngineTimer_stat_Timer1Recurr_IS 500;
BA_REL_ "GenSigFirstTimeoutTime" BU_SG_REL_ CIOM SG_ 2432633752 EngineTimer_stat_Timer3Hours_ISi 3000;
BA_REL_ "GenSigTimeoutTime" BU_SG_REL_ CIOM SG_ 2432633752 EngineTimer_stat_Timer3Hours_ISi 500;
BA_REL_ "GenSigFirstTimeoutTime" BU_SG_REL_ CIOM SG_ 2432633752 EngineTimer_stat_Timer2Minutes_I 3000;
BA_REL_ "GenSigTimeoutTime" BU_SG_REL_ CIOM SG_ 2432633752 EngineTimer_stat_Timer2Minutes_I 500;
BA_REL_ "GenSigFirstTimeoutTime" BU_SG_REL_ CIOM SG_ 2432633752 EngineTimer_stat_Timer2Recurr_IS 3000;
BA_REL_ "GenSigTimeoutTime" BU_SG_REL_ CIOM SG_ 2432633752 EngineTimer_stat_Timer2Recurr_IS 500;
BA_REL_ "GenSigFirstTimeoutTime" BU_SG_REL_ CIOM SG_ 2432633752 EngineTimer_stat_Timer1Hours_ISi 3000;
BA_REL_ "GenSigTimeoutTime" BU_SG_REL_ CIOM SG_ 2432633752 EngineTimer_stat_Timer1Hours_ISi 500;
BA_REL_ "GenSigFirstTimeoutTime" BU_SG_REL_ CIOM SG_ 2432633752 EngineTimer_stat_Timer3Minutes_I 3000;
BA_REL_ "GenSigTimeoutTime" BU_SG_REL_ CIOM SG_ 2432633752 EngineTimer_stat_Timer3Minutes_I 500;
BA_REL_ "GenSigFirstTimeoutTime" BU_SG_REL_ CIOM SG_ 2432633752 EngineTimer_stat_Timer1Minutes_I 3000;
BA_REL_ "GenSigTimeoutTime" BU_SG_REL_ CIOM SG_ 2432633752 EngineTimer_stat_Timer1Minutes_I 500;
BA_REL_ "GenSigFirstTimeoutTime" BU_SG_REL_ CIOM SG_ 2432633752 EngineTimer_stat_Timer3StartDay_ 3000;
BA_REL_ "GenSigTimeoutTime" BU_SG_REL_ CIOM SG_ 2432633752 EngineTimer_stat_Timer3StartDay_ 500;
BA_REL_ "GenSigFirstTimeoutTime" BU_SG_REL_ CIOM SG_ 2432633752 EngineTimer_stat_Timer2_Status_I 3000;
BA_REL_ "GenSigTimeoutTime" BU_SG_REL_ CIOM SG_ 2432633752 EngineTimer_stat_Timer2_Status_I 500;
BA_REL_ "GenSigFirstTimeoutTime" BU_SG_REL_ CIOM SG_ 2432633752 EngineTimer_stat_Timer1StartDay_ 3000;
BA_REL_ "GenSigTimeoutTime" BU_SG_REL_ CIOM SG_ 2432633752 EngineTimer_stat_Timer1StartDay_ 500;
BA_REL_ "GenSigFirstTimeoutTime" BU_SG_REL_ CIOM SG_ 2432633752 EngineTimer_stat_Timer2Hours_ISi 3000;
BA_REL_ "GenSigTimeoutTime" BU_SG_REL_ CIOM SG_ 2432633752 EngineTimer_stat_Timer2Hours_ISi 500;
BA_REL_ "GenSigFirstTimeoutTime" BU_SG_REL_ CIOM SG_ 2432633752 EngineTimer_stat_Timer3_Status_I 3000;
BA_REL_ "GenSigTimeoutTime" BU_SG_REL_ CIOM SG_ 2432633752 EngineTimer_stat_Timer3_Status_I 500;
BA_REL_ "GenSigFirstTimeoutTime" BU_SG_REL_ CIOM SG_ 2432633752 EngineTimer_stat_Timer3Recurr_IS 3000;
BA_REL_ "GenSigTimeoutTime" BU_SG_REL_ CIOM SG_ 2432633752 EngineTimer_stat_Timer3Recurr_IS 500;
BA_REL_ "GenSigFirstTimeoutTime" BU_SG_REL_ CIOM SG_ 2432633752 EngineTimer_stat_Timer1_Status_I 3000;
BA_REL_ "GenSigTimeoutTime" BU_SG_REL_ CIOM SG_ 2432633752 EngineTimer_stat_Timer1_Status_I 500;
BA_REL_ "GenSigFirstTimeoutTime" BU_SG_REL_ CIOM SG_ 2432637336 AQSmodeIndication_Cmd_ISig_5 3000;
BA_REL_ "GenSigTimeoutTime" BU_SG_REL_ CIOM SG_ 2432637336 AQSmodeIndication_Cmd_ISig_5 120;
BA_REL_ "GenSigFirstTimeoutTime" BU_SG_REL_ CIOM SG_ 2432637336 WindscreenDefrostInd_cmd_ISig_5 3000;
BA_REL_ "GenSigTimeoutTime" BU_SG_REL_ CIOM SG_ 2432637336 WindscreenDefrostInd_cmd_ISig_5 120;
BA_REL_ "GenSigFirstTimeoutTime" BU_SG_REL_ CIOM SG_ 2432637336 AutoBlowerLevelIndication_Cmd_IS 3000;
BA_REL_ "GenSigTimeoutTime" BU_SG_REL_ CIOM SG_ 2432637336 AutoBlowerLevelIndication_Cmd_IS 120;
BA_REL_ "GenSigFirstTimeoutTime" BU_SG_REL_ CIOM SG_ 2432637336 PHMaintenanceService_stat_ISig_5 3000;
BA_REL_ "GenSigTimeoutTime" BU_SG_REL_ CIOM SG_ 2432637336 PHMaintenanceService_stat_ISig_5 120;
BA_REL_ "GenSigFirstTimeoutTime" BU_SG_REL_ CIOM SG_ 2432637336 MemoDisplayIndication_Cmd_ISig_5 3000;
BA_REL_ "GenSigTimeoutTime" BU_SG_REL_ CIOM SG_ 2432637336 MemoDisplayIndication_Cmd_ISig_5 120;
BA_REL_ "GenSigFirstTimeoutTime" BU_SG_REL_ CIOM SG_ 2432637336 ACCoolingFanSpeedRequest_CCM 3000;
BA_REL_ "GenSigTimeoutTime" BU_SG_REL_ CIOM SG_ 2432637336 ACCoolingFanSpeedRequest_CCM 120;
BA_REL_ "GenSigFirstTimeoutTime" BU_SG_REL_ LECM1 SG_ 2432637336 TemperatureRqstIndication_cmd_IS 3000;
BA_REL_ "GenSigTimeoutTime" BU_SG_REL_ LECM1 SG_ 2432637336 TemperatureRqstIndication_cmd_IS 120;
BA_REL_ "GenSigFirstTimeoutTime" BU_SG_REL_ CIOM SG_ 2432637336 TemperatureRqstIndication_cmd_IS 3000;
BA_REL_ "GenSigTimeoutTime" BU_SG_REL_ CIOM SG_ 2432637336 TemperatureRqstIndication_cmd_IS 120;
BA_REL_ "GenSigFirstTimeoutTime" BU_SG_REL_ CIOM SG_ 2432637336 Area_9level_Indication_cmd_ISig_ 3000;
BA_REL_ "GenSigTimeoutTime" BU_SG_REL_ CIOM SG_ 2432637336 Area_9level_Indication_cmd_ISig_ 120;
BA_REL_ "GenSigFirstTimeoutTime" BU_SG_REL_ CIOM SG_ 2432637336 MirrorHeatNormModeBtn_stat_ISig_ 3000;
BA_REL_ "GenSigTimeoutTime" BU_SG_REL_ CIOM SG_ 2432637336 MirrorHeatNormModeBtn_stat_ISig_ 120;
BA_REL_ "GenSigFirstTimeoutTime" BU_SG_REL_ CIOM SG_ 2432637336 AutoDefogIndication_Cmd_ISig_5 3000;
BA_REL_ "GenSigTimeoutTime" BU_SG_REL_ CIOM SG_ 2432637336 AutoDefogIndication_Cmd_ISig_5 120;
BA_REL_ "GenSigFirstTimeoutTime" BU_SG_REL_ CIOM SG_ 2432637336 AutoMode_IndicationCmd_ISig_5 3000;
BA_REL_ "GenSigTimeoutTime" BU_SG_REL_ CIOM SG_ 2432637336 AutoMode_IndicationCmd_ISig_5 120;
BA_REL_ "GenSigFirstTimeoutTime" BU_SG_REL_ CIOM SG_ 2432637336 ACdisplayIndication_Cmd_ISig_5 3000;
BA_REL_ "GenSigTimeoutTime" BU_SG_REL_ CIOM SG_ 2432637336 ACdisplayIndication_Cmd_ISig_5 120;
VAL_ 2432663360 PHTimerGUIEvCmd_Timer1StartDay_I 15 "HeaterTimerStartDay_NotAvailable" 14 "HeaterTimerStartDay_Error" 13 "HeaterTimerStartDay_Spare_05" 12 "HeaterTimerStartDay_Spare_04" 11 "HeaterTimerStartDay_Spare_03" 10 "HeaterTimerStartDay_Spare_02" 9 "HeaterTimerStartDay_Spare_01" 8 "HeaterTimerStartDay_Spare" 7 "HeaterTimerStartDay_Sunday" 6 "HeaterTimerStartDay_Saturday" 5 "HeaterTimerStartDay_Friday" 4 "HeaterTimerStartDay_Thursday" 3 "HeaterTimerStartDay_Wednesday" 2 "HeaterTimerStartDay_Tuesday" 1 "HeaterTimerStartDay_Monday" 0 "HeaterTimerStartDay_NotUsed" ;
VAL_ 2432663360 PHTimerGUIEvCmd_Timer1Recur_ISig 15 "HeaterTimerRecurrence_NotAvailable" 14 "HeaterTimerRecurrence_Error" 13 "HeaterTimerRecurrence_Spare_3" 12 "HeaterTimerRecurrence_Spare_2" 11 "HeaterTimerRecurrence_Spare_1" 10 "HeaterTimerRecurrence_Sundays" 9 "HeaterTimerRecurrence_Saturdays" 8 "HeaterTimerRecurrence_Fridays" 7 "HeaterTimerRecurrence_Thursdays" 6 "HeaterTimerRecurrence_Wednesdays" 5 "HeaterTimerRecurrence_Tuesdays" 4 "HeaterTimerRecurrence_Mondays" 3 "HeaterTimerRecurrence_Weekends" 2 "HeaterTimerRecurrence_AllWeekdays" 1 "HeaterTimerRecurrence_Daily" 0 "HeaterTimerRecurrence_None" ;
VAL_ 2432663360 PHTimerGUIEvCmd_Timer1Temp_ISig_ 31 "TemperatureRqstIndication_cmd_NotAvailable" 30 "TemperatureRqstIndication_cmd_Error" 29 "TemperatureRqstIndication_cmd_Spare_01" 28 "TemperatureRqstIndication_cmd_Spare" 27 "TemperatureRqstIndication_cmd_Max" 26 "TemperatureRqstIndication_cmd_29C" 25 "TemperatureRqstIndication_cmd_28C" 24 "TemperatureRqstIndication_cmd_27C" 23 "TemperatureRqstIndication_cmd_26C" 22 "TemperatureRqstIndication_cmd_25_5C" 21 "TemperatureRqstIndication_cmd_25C" 20 "TemperatureRqstIndication_cmd_24_5C" 19 "TemperatureRqstIndication_cmd_24C" 18 "TemperatureRqstIndication_cmd_23_5C" 17 "TemperatureRqstIndication_cmd_23C" 16 "TemperatureRqstIndication_cmd_22_5C" 15 "TemperatureRqstIndication_cmd_22C" 14 "TemperatureRqstIndication_cmd_21_5C" 13 "TemperatureRqstIndication_cmd_21C" 12 "TemperatureRqstIndication_cmd_20_5C" 11 "TemperatureRqstIndication_cmd_20C" 10 "TemperatureRqstIndication_cmd_19_5C" 9 "TemperatureRqstIndication_cmd_19C" 8 "TemperatureRqstIndication_cmd_18_5C" 7 "TemperatureRqstIndication_cmd_18C" 6 "TemperatureRqstIndication_cmd_17_5C" 5 "TemperatureRqstIndication_cmd_17C" 4 "TemperatureRqstIndication_cmd_16_5C" 3 "TemperatureRqstIndication_cmd_16C" 2 "TemperatureRqstIndication_cmd_15C" 1 "TemperatureRqstIndication_cmd_Min" 0 "TemperatureRqstIndication_cmd_NoTempDisplayed" ;
VAL_ 2432663360 PHTimerGUIEvCmd_PhTimer3_cmd_ISi 7 "PhTimer_cmd_NotAvailable" 6 "PhTimer_cmd_Error" 5 "PhTimer_cmd_Spare_02" 4 "PhTimer_cmd_Spare_01" 3 "PhTimer_cmd_TimerDeleted" 2 "PhTimer_cmd_TimerDisable" 1 "PhTimer_cmd_TimerEnable" 0 "PhTimer_cmd_NoAction" ;
VAL_ 2432663360 PHTimerGUIEvCmd_Timer2StartDay_I 15 "HeaterTimerStartDay_NotAvailable" 14 "HeaterTimerStartDay_Error" 13 "HeaterTimerStartDay_Spare_05" 12 "HeaterTimerStartDay_Spare_04" 11 "HeaterTimerStartDay_Spare_03" 10 "HeaterTimerStartDay_Spare_02" 9 "HeaterTimerStartDay_Spare_01" 8 "HeaterTimerStartDay_Spare" 7 "HeaterTimerStartDay_Sunday" 6 "HeaterTimerStartDay_Saturday" 5 "HeaterTimerStartDay_Friday" 4 "HeaterTimerStartDay_Thursday" 3 "HeaterTimerStartDay_Wednesday" 2 "HeaterTimerStartDay_Tuesday" 1 "HeaterTimerStartDay_Monday" 0 "HeaterTimerStartDay_NotUsed" ;
VAL_ 2432663360 PHTimerGUIEvCmd_Timer3StartDay_I 15 "HeaterTimerStartDay_NotAvailable" 14 "HeaterTimerStartDay_Error" 13 "HeaterTimerStartDay_Spare_05" 12 "HeaterTimerStartDay_Spare_04" 11 "HeaterTimerStartDay_Spare_03" 10 "HeaterTimerStartDay_Spare_02" 9 "HeaterTimerStartDay_Spare_01" 8 "HeaterTimerStartDay_Spare" 7 "HeaterTimerStartDay_Sunday" 6 "HeaterTimerStartDay_Saturday" 5 "HeaterTimerStartDay_Friday" 4 "HeaterTimerStartDay_Thursday" 3 "HeaterTimerStartDay_Wednesday" 2 "HeaterTimerStartDay_Tuesday" 1 "HeaterTimerStartDay_Monday" 0 "HeaterTimerStartDay_NotUsed" ;
VAL_ 2432663360 PHTimerGUIEvCmd_PhTimer1_cmd_ISi 7 "PhTimer_cmd_NotAvailable" 6 "PhTimer_cmd_Error" 5 "PhTimer_cmd_Spare_02" 4 "PhTimer_cmd_Spare_01" 3 "PhTimer_cmd_TimerDeleted" 2 "PhTimer_cmd_TimerDisable" 1 "PhTimer_cmd_TimerEnable" 0 "PhTimer_cmd_NoAction" ;
VAL_ 2432663360 PHTimerGUIEvCmd_PhTimer2_cmd_ISi 7 "PhTimer_cmd_NotAvailable" 6 "PhTimer_cmd_Error" 5 "PhTimer_cmd_Spare_02" 4 "PhTimer_cmd_Spare_01" 3 "PhTimer_cmd_TimerDeleted" 2 "PhTimer_cmd_TimerDisable" 1 "PhTimer_cmd_TimerEnable" 0 "PhTimer_cmd_NoAction" ;
VAL_ 2432663360 PHTimerGUIEvCmd_Timer2Recur_ISig 15 "HeaterTimerRecurrence_NotAvailable" 14 "HeaterTimerRecurrence_Error" 13 "HeaterTimerRecurrence_Spare_3" 12 "HeaterTimerRecurrence_Spare_2" 11 "HeaterTimerRecurrence_Spare_1" 10 "HeaterTimerRecurrence_Sundays" 9 "HeaterTimerRecurrence_Saturdays" 8 "HeaterTimerRecurrence_Fridays" 7 "HeaterTimerRecurrence_Thursdays" 6 "HeaterTimerRecurrence_Wednesdays" 5 "HeaterTimerRecurrence_Tuesdays" 4 "HeaterTimerRecurrence_Mondays" 3 "HeaterTimerRecurrence_Weekends" 2 "HeaterTimerRecurrence_AllWeekdays" 1 "HeaterTimerRecurrence_Daily" 0 "HeaterTimerRecurrence_None" ;
VAL_ 2432663360 PHTimerGUIEvCmd_Timer3Recur_ISig 15 "HeaterTimerRecurrence_NotAvailable" 14 "HeaterTimerRecurrence_Error" 13 "HeaterTimerRecurrence_Spare_3" 12 "HeaterTimerRecurrence_Spare_2" 11 "HeaterTimerRecurrence_Spare_1" 10 "HeaterTimerRecurrence_Sundays" 9 "HeaterTimerRecurrence_Saturdays" 8 "HeaterTimerRecurrence_Fridays" 7 "HeaterTimerRecurrence_Thursdays" 6 "HeaterTimerRecurrence_Wednesdays" 5 "HeaterTimerRecurrence_Tuesdays" 4 "HeaterTimerRecurrence_Mondays" 3 "HeaterTimerRecurrence_Weekends" 2 "HeaterTimerRecurrence_AllWeekdays" 1 "HeaterTimerRecurrence_Daily" 0 "HeaterTimerRecurrence_None" ;
VAL_ 2432663360 PHTimerGUIEvCmd_Timer2Temp_ISig_ 31 "TemperatureRqstIndication_cmd_NotAvailable" 30 "TemperatureRqstIndication_cmd_Error" 29 "TemperatureRqstIndication_cmd_Spare_01" 28 "TemperatureRqstIndication_cmd_Spare" 27 "TemperatureRqstIndication_cmd_Max" 26 "TemperatureRqstIndication_cmd_29C" 25 "TemperatureRqstIndication_cmd_28C" 24 "TemperatureRqstIndication_cmd_27C" 23 "TemperatureRqstIndication_cmd_26C" 22 "TemperatureRqstIndication_cmd_25_5C" 21 "TemperatureRqstIndication_cmd_25C" 20 "TemperatureRqstIndication_cmd_24_5C" 19 "TemperatureRqstIndication_cmd_24C" 18 "TemperatureRqstIndication_cmd_23_5C" 17 "TemperatureRqstIndication_cmd_23C" 16 "TemperatureRqstIndication_cmd_22_5C" 15 "TemperatureRqstIndication_cmd_22C" 14 "TemperatureRqstIndication_cmd_21_5C" 13 "TemperatureRqstIndication_cmd_21C" 12 "TemperatureRqstIndication_cmd_20_5C" 11 "TemperatureRqstIndication_cmd_20C" 10 "TemperatureRqstIndication_cmd_19_5C" 9 "TemperatureRqstIndication_cmd_19C" 8 "TemperatureRqstIndication_cmd_18_5C" 7 "TemperatureRqstIndication_cmd_18C" 6 "TemperatureRqstIndication_cmd_17_5C" 5 "TemperatureRqstIndication_cmd_17C" 4 "TemperatureRqstIndication_cmd_16_5C" 3 "TemperatureRqstIndication_cmd_16C" 2 "TemperatureRqstIndication_cmd_15C" 1 "TemperatureRqstIndication_cmd_Min" 0 "TemperatureRqstIndication_cmd_NoTempDisplayed" ;
VAL_ 2432663360 PHTimerGUIEvCmd_Timer3Temp_ISig_ 31 "TemperatureRqstIndication_cmd_NotAvailable" 30 "TemperatureRqstIndication_cmd_Error" 29 "TemperatureRqstIndication_cmd_Spare_01" 28 "TemperatureRqstIndication_cmd_Spare" 27 "TemperatureRqstIndication_cmd_Max" 26 "TemperatureRqstIndication_cmd_29C" 25 "TemperatureRqstIndication_cmd_28C" 24 "TemperatureRqstIndication_cmd_27C" 23 "TemperatureRqstIndication_cmd_26C" 22 "TemperatureRqstIndication_cmd_25_5C" 21 "TemperatureRqstIndication_cmd_25C" 20 "TemperatureRqstIndication_cmd_24_5C" 19 "TemperatureRqstIndication_cmd_24C" 18 "TemperatureRqstIndication_cmd_23_5C" 17 "TemperatureRqstIndication_cmd_23C" 16 "TemperatureRqstIndication_cmd_22_5C" 15 "TemperatureRqstIndication_cmd_22C" 14 "TemperatureRqstIndication_cmd_21_5C" 13 "TemperatureRqstIndication_cmd_21C" 12 "TemperatureRqstIndication_cmd_20_5C" 11 "TemperatureRqstIndication_cmd_20C" 10 "TemperatureRqstIndication_cmd_19_5C" 9 "TemperatureRqstIndication_cmd_19C" 8 "TemperatureRqstIndication_cmd_18_5C" 7 "TemperatureRqstIndication_cmd_18C" 6 "TemperatureRqstIndication_cmd_17_5C" 5 "TemperatureRqstIndication_cmd_17C" 4 "TemperatureRqstIndication_cmd_16_5C" 3 "TemperatureRqstIndication_cmd_16C" 2 "TemperatureRqstIndication_cmd_15C" 1 "TemperatureRqstIndication_cmd_Min" 0 "TemperatureRqstIndication_cmd_NoTempDisplayed" ;
VAL_ 2432657472 EngTimerGUIEvCmd_EhTimer3_cmd_IS 7 "PhTimer_cmd_NotAvailable" 6 "PhTimer_cmd_Error" 5 "PhTimer_cmd_Spare_02" 4 "PhTimer_cmd_Spare_01" 3 "PhTimer_cmd_TimerDeleted" 2 "PhTimer_cmd_TimerDisable" 1 "PhTimer_cmd_TimerEnable" 0 "PhTimer_cmd_NoAction" ;
VAL_ 2432657472 EngTimerGUIEvCmd_Timer2Recur_ISi 15 "HeaterTimerRecurrence_NotAvailable" 14 "HeaterTimerRecurrence_Error" 13 "HeaterTimerRecurrence_Spare_3" 12 "HeaterTimerRecurrence_Spare_2" 11 "HeaterTimerRecurrence_Spare_1" 10 "HeaterTimerRecurrence_Sundays" 9 "HeaterTimerRecurrence_Saturdays" 8 "HeaterTimerRecurrence_Fridays" 7 "HeaterTimerRecurrence_Thursdays" 6 "HeaterTimerRecurrence_Wednesdays" 5 "HeaterTimerRecurrence_Tuesdays" 4 "HeaterTimerRecurrence_Mondays" 3 "HeaterTimerRecurrence_Weekends" 2 "HeaterTimerRecurrence_AllWeekdays" 1 "HeaterTimerRecurrence_Daily" 0 "HeaterTimerRecurrence_None" ;
VAL_ 2432657472 EngTimerGUIEvCmd_EhTimer1_cmd_IS 7 "PhTimer_cmd_NotAvailable" 6 "PhTimer_cmd_Error" 5 "PhTimer_cmd_Spare_02" 4 "PhTimer_cmd_Spare_01" 3 "PhTimer_cmd_TimerDeleted" 2 "PhTimer_cmd_TimerDisable" 1 "PhTimer_cmd_TimerEnable" 0 "PhTimer_cmd_NoAction" ;
VAL_ 2432657472 EngTimerGUIEvCmd_Timer1StartDay_ 15 "HeaterTimerStartDay_NotAvailable" 14 "HeaterTimerStartDay_Error" 13 "HeaterTimerStartDay_Spare_05" 12 "HeaterTimerStartDay_Spare_04" 11 "HeaterTimerStartDay_Spare_03" 10 "HeaterTimerStartDay_Spare_02" 9 "HeaterTimerStartDay_Spare_01" 8 "HeaterTimerStartDay_Spare" 7 "HeaterTimerStartDay_Sunday" 6 "HeaterTimerStartDay_Saturday" 5 "HeaterTimerStartDay_Friday" 4 "HeaterTimerStartDay_Thursday" 3 "HeaterTimerStartDay_Wednesday" 2 "HeaterTimerStartDay_Tuesday" 1 "HeaterTimerStartDay_Monday" 0 "HeaterTimerStartDay_NotUsed" ;
VAL_ 2432657472 EngTimerGUIEvCmd_Timer3Recur_ISi 15 "HeaterTimerRecurrence_NotAvailable" 14 "HeaterTimerRecurrence_Error" 13 "HeaterTimerRecurrence_Spare_3" 12 "HeaterTimerRecurrence_Spare_2" 11 "HeaterTimerRecurrence_Spare_1" 10 "HeaterTimerRecurrence_Sundays" 9 "HeaterTimerRecurrence_Saturdays" 8 "HeaterTimerRecurrence_Fridays" 7 "HeaterTimerRecurrence_Thursdays" 6 "HeaterTimerRecurrence_Wednesdays" 5 "HeaterTimerRecurrence_Tuesdays" 4 "HeaterTimerRecurrence_Mondays" 3 "HeaterTimerRecurrence_Weekends" 2 "HeaterTimerRecurrence_AllWeekdays" 1 "HeaterTimerRecurrence_Daily" 0 "HeaterTimerRecurrence_None" ;
VAL_ 2432657472 EngTimerGUIEvCmd_Timer2StartDay_ 15 "HeaterTimerStartDay_NotAvailable" 14 "HeaterTimerStartDay_Error" 13 "HeaterTimerStartDay_Spare_05" 12 "HeaterTimerStartDay_Spare_04" 11 "HeaterTimerStartDay_Spare_03" 10 "HeaterTimerStartDay_Spare_02" 9 "HeaterTimerStartDay_Spare_01" 8 "HeaterTimerStartDay_Spare" 7 "HeaterTimerStartDay_Sunday" 6 "HeaterTimerStartDay_Saturday" 5 "HeaterTimerStartDay_Friday" 4 "HeaterTimerStartDay_Thursday" 3 "HeaterTimerStartDay_Wednesday" 2 "HeaterTimerStartDay_Tuesday" 1 "HeaterTimerStartDay_Monday" 0 "HeaterTimerStartDay_NotUsed" ;
VAL_ 2432657472 EngTimerGUIEvCmd_Timer1Recur_ISi 15 "HeaterTimerRecurrence_NotAvailable" 14 "HeaterTimerRecurrence_Error" 13 "HeaterTimerRecurrence_Spare_3" 12 "HeaterTimerRecurrence_Spare_2" 11 "HeaterTimerRecurrence_Spare_1" 10 "HeaterTimerRecurrence_Sundays" 9 "HeaterTimerRecurrence_Saturdays" 8 "HeaterTimerRecurrence_Fridays" 7 "HeaterTimerRecurrence_Thursdays" 6 "HeaterTimerRecurrence_Wednesdays" 5 "HeaterTimerRecurrence_Tuesdays" 4 "HeaterTimerRecurrence_Mondays" 3 "HeaterTimerRecurrence_Weekends" 2 "HeaterTimerRecurrence_AllWeekdays" 1 "HeaterTimerRecurrence_Daily" 0 "HeaterTimerRecurrence_None" ;
VAL_ 2432657472 EngTimerGUIEvCmd_Timer3StartDay_ 15 "HeaterTimerStartDay_NotAvailable" 14 "HeaterTimerStartDay_Error" 13 "HeaterTimerStartDay_Spare_05" 12 "HeaterTimerStartDay_Spare_04" 11 "HeaterTimerStartDay_Spare_03" 10 "HeaterTimerStartDay_Spare_02" 9 "HeaterTimerStartDay_Spare_01" 8 "HeaterTimerStartDay_Spare" 7 "HeaterTimerStartDay_Sunday" 6 "HeaterTimerStartDay_Saturday" 5 "HeaterTimerStartDay_Friday" 4 "HeaterTimerStartDay_Thursday" 3 "HeaterTimerStartDay_Wednesday" 2 "HeaterTimerStartDay_Tuesday" 1 "HeaterTimerStartDay_Monday" 0 "HeaterTimerStartDay_NotUsed" ;
VAL_ 2432657472 EngTimerGUIEvCmd_EhTimer2_cmd_IS 7 "PhTimer_cmd_NotAvailable" 6 "PhTimer_cmd_Error" 5 "PhTimer_cmd_Spare_02" 4 "PhTimer_cmd_Spare_01" 3 "PhTimer_cmd_TimerDeleted" 2 "PhTimer_cmd_TimerDisable" 1 "PhTimer_cmd_TimerEnable" 0 "PhTimer_cmd_NoAction" ;
VAL_ 2432651584 ParkHeaterTimerReleased_stat_ISi 3 "DisableEnable_NotAvailable" 2 "DisableEnable_Error" 1 "DisableEnable_Enable" 0 "DisableEnable_Disable" ;
VAL_ 2432651584 Washing_HMI_rqst_ISig_5 3 "InactiveActive_NotAvailable" 2 "InactiveActive_Error" 1 "InactiveActive_Active" 0 "InactiveActive_Inactive" ;
VAL_ 2432651584 BunkH2ParkHeater_ButtonStatus 3 "PushButtonStatus_NotAvailable" 2 "PushButtonStatus_Error" 1 "PushButtonStatus_Pushed" 0 "PushButtonStatus_Neutral" ;
VAL_ 2432651584 BunkBTempDec_ButtonStatus 3 "PushButtonStatus_NotAvailable" 2 "PushButtonStatus_Error" 1 "PushButtonStatus_Pushed" 0 "PushButtonStatus_Neutral" ;
VAL_ 2432651584 BunkH2TempDec_ButtonStatus 3 "PushButtonStatus_NotAvailable" 2 "PushButtonStatus_Error" 1 "PushButtonStatus_Pushed" 0 "PushButtonStatus_Neutral" ;
VAL_ 2432651584 BunkBParkHeater_ButtonStatus 3 "PushButtonStatus_NotAvailable" 2 "PushButtonStatus_Error" 1 "PushButtonStatus_Pushed" 0 "PushButtonStatus_Neutral" ;
VAL_ 2432651584 BunkBTempInc_ButtonStatus 3 "PushButtonStatus_NotAvailable" 2 "PushButtonStatus_Error" 1 "PushButtonStatus_Pushed" 0 "PushButtonStatus_Neutral" ;
VAL_ 2432651584 AudioSystemStatus_ISig_5 3 "OffOn_NotAvailable" 2 "OffOn_Error" 1 "OffOn_On" 0 "OffOn_Off" ;
VAL_ 2432651584 ParkingHeaterCleaning_cmd_ISig_5 3 "ParkingHeaterCleaning_cmd_NotAvailable" 2 "ParkingHeaterCleaning_cmd_Escaped" 1 "ParkingHeaterCleaning_cmd_Activated" 0 "ParkingHeaterCleaning_cmd_NoAction" ;
VAL_ 2432651584 PtosStatus_ISig_5 3 "PtosStatus_NotAvailable" 2 "PtosStatus_Error" 1 "PtosStatus_OneOrMorePTOEngaged" 0 "PtosStatus_NoPTOEngaged" ;
VAL_ 2432651584 BunkB1ParkHeaterBtn_stat 3 "PushButtonStatus_NotAvailable" 2 "PushButtonStatus_Error" 1 "PushButtonStatus_Pushed" 0 "PushButtonStatus_Neutral" ;
VAL_ 2432651584 BunkH2PHTimer_rqst_Timer_cmd 7 "ParkHeaterTimer_cmd_NotAvailable" 6 "ParkHeaterTimer_cmd_Error" 5 "ParkHeaterTimer_cmd_Spare_02" 4 "ParkHeaterTimer_cmd_Spare_01" 3 "ParkHeaterTimer_cmd_Spare" 2 "ParkHeaterTimer_cmd_TimerDisable" 1 "ParkHeaterTimer_cmd_TimerEnable" 0 "ParkHeaterTimer_cmd_NoAction" ;
VAL_ 2431745856 BacklightCmd_ISig_5 31 "BacklightCmd_NotAvailable" 30 "BacklightCmd_Error" 16 "BacklightCmd_BacklightLevel16" 15 "BacklightCmd_BacklightLevel15" 14 "BacklightCmd_BacklightLevel14" 13 "BacklightCmd_BacklightLevel13" 12 "BacklightCmd_BacklightLevel12" 11 "BacklightCmd_BacklightLevel11" 10 "BacklightCmd_BacklightLevel10" 9 "BacklightCmd_BacklightLevel9" 8 "BacklightCmd_BacklightLevel8" 7 "BacklightCmd_BacklightLevel7" 6 "BacklightCmd_BacklightLevel6" 5 "BacklightCmd_BacklightLevel5" 4 "BacklightCmd_BacklightLevel4" 3 "BacklightCmd_BacklightLevel3" 2 "BacklightCmd_BacklightLevel2" 1 "BacklightCmd_BacklightLevel1" 0 "BacklightCmd_BacklightOff" ;
VAL_ 2431745856 VehicleMode_ISig_5 15 "VehicleMode_NotAvailable" 14 "VehicleMode_Error" 13 "VehicleMode_Spare_7" 12 "VehicleMode_Spare_6" 11 "VehicleMode_Spare_5" 10 "VehicleMode_Spare_4" 9 "VehicleMode_Spare_3" 8 "VehicleMode_Spare_2" 7 "VehicleMode_Spare_1" 6 "VehicleMode_Running" 5 "VehicleMode_Cranking" 4 "VehicleMode_PreRunning" 3 "VehicleMode_Accessory" 2 "VehicleMode_Living" 1 "VehicleMode_Parked" 0 "VehicleMode_Hibernate" ;
VAL_ 2431745856 BunkH2OnOFF_ButtonStatus 3 "PushButtonStatus_NotAvailable" 2 "PushButtonStatus_Error" 1 "PushButtonStatus_Pushed" 0 "PushButtonStatus_Neutral" ;
VAL_ 2431745856 IntLghtModeInd_cmd_EventFlag 1 "EventFlag_High" 0 "EventFlag_Low" ;
VAL_ 2431745856 LevelControlInformation_ISig_5 15 "LevelControlInformation_NotAvailable" 14 "LevelControlInformation_Error" 13 "LevelControlInformation_Reserved_06" 12 "LevelControlInformation_Reserved_05" 11 "LevelControlInformation_Reserved_04" 10 "LevelControlInformation_Reserved_03" 9 "LevelControlInformation_Reserved_02" 8 "LevelControlInformation_Reserved_01" 7 "LevelControlInformation_Reserved" 6 "LevelControlInformation_LimpHome" 5 "LevelControlInformation_FerryFunction" 4 "LevelControlInformation_KneelingHeight" 3 "LevelControlInformation_DriveHeight" 2 "LevelControlInformation_DockingHeight" 1 "LevelControlInformation_HeightAdjustment" 0 "LevelControlInformation_Prohibit" ;
VAL_ 2431745856 IntLghtModeInd_cmd_IL_Mode 7 "IL_Mode_NotAvailable" 6 "IL_Mode_ErrorIndicator" 5 "IL_Mode_spare_2" 4 "IL_Mode_spare_1" 3 "IL_Mode_Max" 2 "IL_Mode_Resting" 1 "IL_Mode_NightDriving" 0 "IL_Mode_OFF" ;
VAL_ 2432650304 DriverSeatBeltSwitch_ISig_5 3 "DriverSeatBeltSwitch_NotAvailable" 2 "DriverSeatBeltSwitch_Error" 1 "DriverSeatBeltSwitch_SeatBeltBuckledFastened" 0 "DriverSeatBeltSwitch_SeatBeltUnbuckledUnfastened" ;
VAL_ 2432650304 DriverMemory_rqst_ISig_5 31 "DriverMemory_rqst_Error" 30 "DriverMemory_rqst_NotAvailable" 29 "DriverMemory_rqst_Spare_07" 28 "DriverMemory_rqst_Spare_06" 27 "DriverMemory_rqst_Spare_05" 26 "DriverMemory_rqst_Spare_04" 25 "DriverMemory_rqst_Spare_03" 24 "DriverMemory_rqst_Spare_02" 23 "DriverMemory_rqst_Spare_01" 22 "DriverMemory_rqst_Spare" 21 "DriverMemory_rqst_ResetAllMemThenUseDefDriverMem" 20 "DriverMemory_rqst_ResetAndThenUseDriverMemory10" 19 "DriverMemory_rqst_ResetAndThenUseDriverMemory9" 18 "DriverMemory_rqst_ResetAndThenUseDriverMemory8" 17 "DriverMemory_rqst_ResetAndThenUseDriverMemory7" 16 "DriverMemory_rqst_ResetAndThenUseDriverMemory6" 15 "DriverMemory_rqst_ResetAndThenUseDriverMemory5" 14 "DriverMemory_rqst_ResetAndThenUseDriverMemory4" 13 "DriverMemory_rqst_ResetAndThenUseDriverMemory3" 12 "DriverMemory_rqst_ResetAndThenUseDriverMemory2" 11 "DriverMemory_rqst_ResetAndThenUseDriverMemory1" 10 "DriverMemory_rqst_UseDriverMemory10" 9 "DriverMemory_rqst_UseDriverMemory9" 8 "DriverMemory_rqst_UseDriverMemory8" 7 "DriverMemory_rqst_UseDriverMemory7" 6 "DriverMemory_rqst_UseDriverMemory6" 5 "DriverMemory_rqst_UseDriverMemory5" 4 "DriverMemory_rqst_UseDriverMemory4" 3 "DriverMemory_rqst_UseDriverMemory3" 2 "DriverMemory_rqst_UseDriverMemory2" 1 "DriverMemory_rqst_UseDriverMemory1" 0 "DriverMemory_rqst_UseDefaultDriverMemory" ;
VAL_ 2432650304 ReverseGearEngaged_ISig_5 3 "ReverseGearEngaged_NotAvailable" 2 "ReverseGearEngaged_Error" 1 "ReverseGearEngaged_ReverseGearEngaged" 0 "ReverseGearEngaged_ReverseGearNotEngaged" ;
VAL_ 2432650304 AutoBlowerLevel_Selection_ISig_5 7 "AutoBlowerLevel_NotAvailable" 6 "AutoBlowerLevel_Error" 5 "AutoBlowerLevel_Spare_02" 4 "AutoBlowerLevel_Spare_01" 3 "AutoBlowerLevel_Spare" 2 "AutoBlowerLevel_Low" 1 "AutoBlowerLevel_Normal" 0 "AutoBlowerLevel_High" ;
VAL_ 2432650304 AutoDefogmode_Selection_ISig_5 7 "AutoDefogmode_NotAvailable" 6 "AutoDefogmode_Error" 5 "AutoDefogmode_Spare_01" 4 "AutoDefogmode_Spare" 3 "AutoDefogmode_Moderate" 2 "AutoDefogmode_Normal" 1 "AutoDefogmode_Sensitive" 0 "AutoDefogmode_OFF" ;
VAL_ 2432650304 ECSStandbyActive 3 "FalseTrue_NotAvaiable" 2 "FalseTrue_Error" 1 "FalseTrue_True" 0 "FalseTrue_False" ;
VAL_ 2432650304 ACMode_Selection_ISig_5 7 "ACMode_NotAvailable" 6 "ACMode_Error" 5 "ACMode_Spare_01" 4 "ACMode_Spare" 3 "ACMode_ExtraDryCabAir" 2 "ACMode_HumidCabAir" 1 "ACMode_Standard" 0 "ACMode_Economy" ;
VAL_ 2432650304 HeightAdjustmentAllowed_ISig_5 3 "FalseTrue_NotAvaiable" 2 "FalseTrue_Error" 1 "FalseTrue_True" 0 "FalseTrue_False" ;
VAL_ 2432650304 AQSMode_Selection_ISig_5 3 "AQSMode_NotAvailable" 2 "AQSMode_Error" 1 "AQSMode_Auto" 0 "AQSMode_OFF" ;
VAL_ 2432650304 SelectedTimeFormat_stat_ISig_5 3 "TimeFormatStat_NotAvailable" 2 "TimeFormatStat_Error" 1 "TimeFormatStat_24h" 0 "TimeFormatStat_AM_PM" ;
VAL_ 2432650304 SelectedWeightUnit_stat_ISig_5 3 "WeightUnit_NotAvailable" 2 "WeightUnit_Error" 1 "WeightUnit_Pound" 0 "WeightUnit_Kg" ;
VAL_ 2432650304 FuncIndIlluminationLevel_ISig_5 7 "FuncIndIlluminationLevel_NotAvailable" 6 "FuncIndIlluminationLevel_Error" 5 "FuncIndIlluminationLevel_Spare" 4 "FuncIndIlluminationLevel_IlluminationLevel4" 3 "FuncIndIlluminationLevel_IlluminationLevel3" 2 "FuncIndIlluminationLevel_IlluminationLevel2" 1 "FuncIndIlluminationLevel_IlluminationLevel1" 0 "FuncIndIlluminationLevel_IlluminationOff" ;
VAL_ 2432650304 WiperModeStatus_ISig_5 7 "WiperModeStatus_NotAvailable" 6 "WiperModeStatus_ErrorIndicator" 5 "WiperModeStatus_Spare02" 4 "WiperModeStatus_Spare01" 3 "WiperModeStatus_Spare" 2 "WiperModeStatus_HighSpeedWiping" 1 "WiperModeStatus_LowSpeedWiping" 0 "WiperModeStatus_WiperOff" ;
VAL_ 2432650304 MirrorHeatingMode_ISig_5 7 "MirrorHeat_NotAvailable" 6 "MirrorHeat_ErrorIndicator" 5 "MirrorHeat_SpareValue_02" 4 "MirrorHeat_SpareValue_01" 3 "MirrorHeat_SpareValue" 2 "MirrorHeat_ONExtendedMode" 1 "MirrorHeat_ONNormalMode" 0 "MirrorHeat_OFF" ;
VAL_ 2432640664 PHTimer2_stat_Recurrence_ISig_5 15 "HeaterTimerRecurrence_NotAvailable" 14 "HeaterTimerRecurrence_Error" 13 "HeaterTimerRecurrence_Spare_3" 12 "HeaterTimerRecurrence_Spare_2" 11 "HeaterTimerRecurrence_Spare_1" 10 "HeaterTimerRecurrence_Sundays" 9 "HeaterTimerRecurrence_Saturdays" 8 "HeaterTimerRecurrence_Fridays" 7 "HeaterTimerRecurrence_Thursdays" 6 "HeaterTimerRecurrence_Wednesdays" 5 "HeaterTimerRecurrence_Tuesdays" 4 "HeaterTimerRecurrence_Mondays" 3 "HeaterTimerRecurrence_Weekends" 2 "HeaterTimerRecurrence_AllWeekdays" 1 "HeaterTimerRecurrence_Daily" 0 "HeaterTimerRecurrence_None" ;
VAL_ 2432640664 PHTimer3_stat_Temp_ISig_5 31 "TemperatureRqstIndication_cmd_NotAvailable" 30 "TemperatureRqstIndication_cmd_Error" 29 "TemperatureRqstIndication_cmd_Spare_01" 28 "TemperatureRqstIndication_cmd_Spare" 27 "TemperatureRqstIndication_cmd_Max" 26 "TemperatureRqstIndication_cmd_29C" 25 "TemperatureRqstIndication_cmd_28C" 24 "TemperatureRqstIndication_cmd_27C" 23 "TemperatureRqstIndication_cmd_26C" 22 "TemperatureRqstIndication_cmd_25_5C" 21 "TemperatureRqstIndication_cmd_25C" 20 "TemperatureRqstIndication_cmd_24_5C" 19 "TemperatureRqstIndication_cmd_24C" 18 "TemperatureRqstIndication_cmd_23_5C" 17 "TemperatureRqstIndication_cmd_23C" 16 "TemperatureRqstIndication_cmd_22_5C" 15 "TemperatureRqstIndication_cmd_22C" 14 "TemperatureRqstIndication_cmd_21_5C" 13 "TemperatureRqstIndication_cmd_21C" 12 "TemperatureRqstIndication_cmd_20_5C" 11 "TemperatureRqstIndication_cmd_20C" 10 "TemperatureRqstIndication_cmd_19_5C" 9 "TemperatureRqstIndication_cmd_19C" 8 "TemperatureRqstIndication_cmd_18_5C" 7 "TemperatureRqstIndication_cmd_18C" 6 "TemperatureRqstIndication_cmd_17_5C" 5 "TemperatureRqstIndication_cmd_17C" 4 "TemperatureRqstIndication_cmd_16_5C" 3 "TemperatureRqstIndication_cmd_16C" 2 "TemperatureRqstIndication_cmd_15C" 1 "TemperatureRqstIndication_cmd_Min" 0 "TemperatureRqstIndication_cmd_NoTempDisplayed" ;
VAL_ 2432640664 PHTimer3_stat_Status_ISig_5 3 "ParkHeaterTimer_Status_NotAvailable" 2 "ParkHeaterTimer_Status_TimerDeleted" 1 "ParkHeaterTimer_Status_TimerNotActivated" 0 "ParkHeaterTimer_Status_TimerActivated" ;
VAL_ 2432640664 PHTimer2_stat_StartDay_ISig_5 15 "HeaterTimerStartDay_NotAvailable" 14 "HeaterTimerStartDay_Error" 13 "HeaterTimerStartDay_Spare_05" 12 "HeaterTimerStartDay_Spare_04" 11 "HeaterTimerStartDay_Spare_03" 10 "HeaterTimerStartDay_Spare_02" 9 "HeaterTimerStartDay_Spare_01" 8 "HeaterTimerStartDay_Spare" 7 "HeaterTimerStartDay_Sunday" 6 "HeaterTimerStartDay_Saturday" 5 "HeaterTimerStartDay_Friday" 4 "HeaterTimerStartDay_Thursday" 3 "HeaterTimerStartDay_Wednesday" 2 "HeaterTimerStartDay_Tuesday" 1 "HeaterTimerStartDay_Monday" 0 "HeaterTimerStartDay_NotUsed" ;
VAL_ 2432640664 PHTimer2_stat_Temp_ISig_5 31 "TemperatureRqstIndication_cmd_NotAvailable" 30 "TemperatureRqstIndication_cmd_Error" 29 "TemperatureRqstIndication_cmd_Spare_01" 28 "TemperatureRqstIndication_cmd_Spare" 27 "TemperatureRqstIndication_cmd_Max" 26 "TemperatureRqstIndication_cmd_29C" 25 "TemperatureRqstIndication_cmd_28C" 24 "TemperatureRqstIndication_cmd_27C" 23 "TemperatureRqstIndication_cmd_26C" 22 "TemperatureRqstIndication_cmd_25_5C" 21 "TemperatureRqstIndication_cmd_25C" 20 "TemperatureRqstIndication_cmd_24_5C" 19 "TemperatureRqstIndication_cmd_24C" 18 "TemperatureRqstIndication_cmd_23_5C" 17 "TemperatureRqstIndication_cmd_23C" 16 "TemperatureRqstIndication_cmd_22_5C" 15 "TemperatureRqstIndication_cmd_22C" 14 "TemperatureRqstIndication_cmd_21_5C" 13 "TemperatureRqstIndication_cmd_21C" 12 "TemperatureRqstIndication_cmd_20_5C" 11 "TemperatureRqstIndication_cmd_20C" 10 "TemperatureRqstIndication_cmd_19_5C" 9 "TemperatureRqstIndication_cmd_19C" 8 "TemperatureRqstIndication_cmd_18_5C" 7 "TemperatureRqstIndication_cmd_18C" 6 "TemperatureRqstIndication_cmd_17_5C" 5 "TemperatureRqstIndication_cmd_17C" 4 "TemperatureRqstIndication_cmd_16_5C" 3 "TemperatureRqstIndication_cmd_16C" 2 "TemperatureRqstIndication_cmd_15C" 1 "TemperatureRqstIndication_cmd_Min" 0 "TemperatureRqstIndication_cmd_NoTempDisplayed" ;
VAL_ 2432640664 PHTimer2_stat_Status_ISig_5 3 "ParkHeaterTimer_Status_NotAvailable" 2 "ParkHeaterTimer_Status_TimerDeleted" 1 "ParkHeaterTimer_Status_TimerNotActivated" 0 "ParkHeaterTimer_Status_TimerActivated" ;
VAL_ 2432640664 PHTimer3_stat_Recurrence_ISig_5 15 "HeaterTimerRecurrence_NotAvailable" 14 "HeaterTimerRecurrence_Error" 13 "HeaterTimerRecurrence_Spare_3" 12 "HeaterTimerRecurrence_Spare_2" 11 "HeaterTimerRecurrence_Spare_1" 10 "HeaterTimerRecurrence_Sundays" 9 "HeaterTimerRecurrence_Saturdays" 8 "HeaterTimerRecurrence_Fridays" 7 "HeaterTimerRecurrence_Thursdays" 6 "HeaterTimerRecurrence_Wednesdays" 5 "HeaterTimerRecurrence_Tuesdays" 4 "HeaterTimerRecurrence_Mondays" 3 "HeaterTimerRecurrence_Weekends" 2 "HeaterTimerRecurrence_AllWeekdays" 1 "HeaterTimerRecurrence_Daily" 0 "HeaterTimerRecurrence_None" ;
VAL_ 2432640664 PHTimer3_stat_StartDay_ISig_5 15 "HeaterTimerStartDay_NotAvailable" 14 "HeaterTimerStartDay_Error" 13 "HeaterTimerStartDay_Spare_05" 12 "HeaterTimerStartDay_Spare_04" 11 "HeaterTimerStartDay_Spare_03" 10 "HeaterTimerStartDay_Spare_02" 9 "HeaterTimerStartDay_Spare_01" 8 "HeaterTimerStartDay_Spare" 7 "HeaterTimerStartDay_Sunday" 6 "HeaterTimerStartDay_Saturday" 5 "HeaterTimerStartDay_Friday" 4 "HeaterTimerStartDay_Thursday" 3 "HeaterTimerStartDay_Wednesday" 2 "HeaterTimerStartDay_Tuesday" 1 "HeaterTimerStartDay_Monday" 0 "HeaterTimerStartDay_NotUsed" ;
VAL_ 2432644760 ExtraHeating_status_ISig_5 3 "OffAuto_NotAvailable" 2 "OffAuto_Error" 1 "OffAuto_AutoStart" 0 "OffAuto_Off" ;
VAL_ 2432644760 ParkingClimate_IndicationCmd_ISi 7 "ParkingClimate_IndicationCmd_NotAvailable" 6 "ParkingClimate_IndicationCmd_Error" 5 "ParkingClimate_IndicationCmd_Spare_01" 4 "ParkingClimate_IndicationCmd_ShortStopHeaterActivated" 3 "ParkingClimate_IndicationCmd_ParkCoolWithoutCompActivReducedMode" 2 "ParkingClimate_IndicationCmd_ParkCoolWithCompActivFullMode" 1 "ParkingClimate_IndicationCmd_ParkingHeaterActivated" 0 "ParkingClimate_IndicationCmd_NoSystemActivated" ;
VAL_ 2432644760 ShortStopHeater_cmd_ISig_5 3 "Request_NotAvailable" 2 "Request_Error" 1 "Request_RequestActive" 0 "Request_NotRequested" ;
VAL_ 2432644760 PHTimer1_stat_Status_ISig_5 3 "ParkHeaterTimer_Status_NotAvailable" 2 "ParkHeaterTimer_Status_TimerDeleted" 1 "ParkHeaterTimer_Status_TimerNotActivated" 0 "ParkHeaterTimer_Status_TimerActivated" ;
VAL_ 2432644760 PHTimer1_stat_StartDay_ISig_5 15 "HeaterTimerStartDay_NotAvailable" 14 "HeaterTimerStartDay_Error" 13 "HeaterTimerStartDay_Spare_05" 12 "HeaterTimerStartDay_Spare_04" 11 "HeaterTimerStartDay_Spare_03" 10 "HeaterTimerStartDay_Spare_02" 9 "HeaterTimerStartDay_Spare_01" 8 "HeaterTimerStartDay_Spare" 7 "HeaterTimerStartDay_Sunday" 6 "HeaterTimerStartDay_Saturday" 5 "HeaterTimerStartDay_Friday" 4 "HeaterTimerStartDay_Thursday" 3 "HeaterTimerStartDay_Wednesday" 2 "HeaterTimerStartDay_Tuesday" 1 "HeaterTimerStartDay_Monday" 0 "HeaterTimerStartDay_NotUsed" ;
VAL_ 2432644760 PHTimer1_stat_Temp_ISig_5 31 "TemperatureRqstIndication_cmd_NotAvailable" 30 "TemperatureRqstIndication_cmd_Error" 29 "TemperatureRqstIndication_cmd_Spare_01" 28 "TemperatureRqstIndication_cmd_Spare" 27 "TemperatureRqstIndication_cmd_Max" 26 "TemperatureRqstIndication_cmd_29C" 25 "TemperatureRqstIndication_cmd_28C" 24 "TemperatureRqstIndication_cmd_27C" 23 "TemperatureRqstIndication_cmd_26C" 22 "TemperatureRqstIndication_cmd_25_5C" 21 "TemperatureRqstIndication_cmd_25C" 20 "TemperatureRqstIndication_cmd_24_5C" 19 "TemperatureRqstIndication_cmd_24C" 18 "TemperatureRqstIndication_cmd_23_5C" 17 "TemperatureRqstIndication_cmd_23C" 16 "TemperatureRqstIndication_cmd_22_5C" 15 "TemperatureRqstIndication_cmd_22C" 14 "TemperatureRqstIndication_cmd_21_5C" 13 "TemperatureRqstIndication_cmd_21C" 12 "TemperatureRqstIndication_cmd_20_5C" 11 "TemperatureRqstIndication_cmd_20C" 10 "TemperatureRqstIndication_cmd_19_5C" 9 "TemperatureRqstIndication_cmd_19C" 8 "TemperatureRqstIndication_cmd_18_5C" 7 "TemperatureRqstIndication_cmd_18C" 6 "TemperatureRqstIndication_cmd_17_5C" 5 "TemperatureRqstIndication_cmd_17C" 4 "TemperatureRqstIndication_cmd_16_5C" 3 "TemperatureRqstIndication_cmd_16C" 2 "TemperatureRqstIndication_cmd_15C" 1 "TemperatureRqstIndication_cmd_Min" 0 "TemperatureRqstIndication_cmd_NoTempDisplayed" ;
VAL_ 2432644760 PHTimer1_stat_Recurrence_ISig_5 15 "HeaterTimerRecurrence_NotAvailable" 14 "HeaterTimerRecurrence_Error" 13 "HeaterTimerRecurrence_Spare_3" 12 "HeaterTimerRecurrence_Spare_2" 11 "HeaterTimerRecurrence_Spare_1" 10 "HeaterTimerRecurrence_Sundays" 9 "HeaterTimerRecurrence_Saturdays" 8 "HeaterTimerRecurrence_Fridays" 7 "HeaterTimerRecurrence_Thursdays" 6 "HeaterTimerRecurrence_Wednesdays" 5 "HeaterTimerRecurrence_Tuesdays" 4 "HeaterTimerRecurrence_Mondays" 3 "HeaterTimerRecurrence_Weekends" 2 "HeaterTimerRecurrence_AllWeekdays" 1 "HeaterTimerRecurrence_Daily" 0 "HeaterTimerRecurrence_None" ;
VAL_ 2432639640 ACmode_IndicationCmd_ISig_5 1 "IndicationCmd_ONLEDActivated" 0 "IndicationCmd_OFFLEDNotActivated" ;
VAL_ 2432639640 PHTimer_rqst_SetAlarmOper_ISig_5 7 "SetAlarmOperation_NotAvailable" 6 "SetAlarmOperation_Error" 5 "SetAlarmOperation_Spare_02" 4 "SetAlarmOperation_Spare_01" 3 "SetAlarmOperation_Reset" 2 "SetAlarmOperation_Continue" 1 "SetAlarmOperation_Stop" 0 "SetAlarmOperation_Start" ;
VAL_ 2432639640 PH_Activation_cmd_ISig_5 7 "PH_Activation_cmd_NotAvailable" 6 "PH_Activation_cmd_Error" 5 "PH_Activation_cmd_Spare_01" 4 "PH_Activation_cmd_Spare" 3 "PH_Activation_cmd_ParkingHeaterONForced" 2 "PH_Activation_cmd_ParkingHeaterON" 1 "PH_Activation_cmd_ParkingHeaterOFFShortStop" 0 "PH_Activation_cmd_ParkingHeaterOFF" ;
VAL_ 2432639640 ParkingHeaterCleaning_Rqst_ISig_ 3 "Request_NotAvailable" 2 "Request_Error" 1 "Request_RequestActive" 0 "Request_NotRequested" ;
VAL_ 2432639640 ParkingHeater_IndicationCmd_ISig 1 "IndicationCmd_ONLEDActivated" 0 "IndicationCmd_OFFLEDNotActivated" ;
VAL_ 2432639640 AC_CompressorClutchCmd_ISig_5 3 "DisengageEngage_NotAvailable" 2 "DisengageEngage_Error" 1 "DisengageEngage_Engage" 0 "DisengageEngage_Disengage" ;
VAL_ 2432639640 PHTimer_rqst_DayOfWeekRq_ISig_5 15 "DayOfWeekRq_NotAvailable" 14 "DayOfWeekRq_Error" 13 "DayOfWeekRq_Spare_7" 12 "DayOfWeekRq_Spare_6" 11 "DayOfWeekRq_Spare_5" 10 "DayOfWeekRq_Spare_4" 9 "DayOfWeekRq_Spare_3" 8 "DayOfWeekRq_Spare_2" 7 "DayOfWeekRq_NoDay" 6 "DayOfWeekRq_Sunday" 5 "DayOfWeekRq_Saturday" 4 "DayOfWeekRq_Friday" 3 "DayOfWeekRq_Thursday" 2 "DayOfWeekRq_Wednesday" 1 "DayOfWeekRq_Tuesday" 0 "DayOfWeekRq_Monday" ;
VAL_ 2432633752 EngineTimer_stat_Timer2StartDay_ 15 "HeaterTimerStartDay_NotAvailable" 14 "HeaterTimerStartDay_Error" 13 "HeaterTimerStartDay_Spare_05" 12 "HeaterTimerStartDay_Spare_04" 11 "HeaterTimerStartDay_Spare_03" 10 "HeaterTimerStartDay_Spare_02" 9 "HeaterTimerStartDay_Spare_01" 8 "HeaterTimerStartDay_Spare" 7 "HeaterTimerStartDay_Sunday" 6 "HeaterTimerStartDay_Saturday" 5 "HeaterTimerStartDay_Friday" 4 "HeaterTimerStartDay_Thursday" 3 "HeaterTimerStartDay_Wednesday" 2 "HeaterTimerStartDay_Tuesday" 1 "HeaterTimerStartDay_Monday" 0 "HeaterTimerStartDay_NotUsed" ;
VAL_ 2432633752 EngineTimer_stat_Timer1Recurr_IS 15 "HeaterTimerRecurrence_NotAvailable" 14 "HeaterTimerRecurrence_Error" 13 "HeaterTimerRecurrence_Spare_3" 12 "HeaterTimerRecurrence_Spare_2" 11 "HeaterTimerRecurrence_Spare_1" 10 "HeaterTimerRecurrence_Sundays" 9 "HeaterTimerRecurrence_Saturdays" 8 "HeaterTimerRecurrence_Fridays" 7 "HeaterTimerRecurrence_Thursdays" 6 "HeaterTimerRecurrence_Wednesdays" 5 "HeaterTimerRecurrence_Tuesdays" 4 "HeaterTimerRecurrence_Mondays" 3 "HeaterTimerRecurrence_Weekends" 2 "HeaterTimerRecurrence_AllWeekdays" 1 "HeaterTimerRecurrence_Daily" 0 "HeaterTimerRecurrence_None" ;
VAL_ 2432633752 EngineTimer_stat_Timer2Recurr_IS 15 "HeaterTimerRecurrence_NotAvailable" 14 "HeaterTimerRecurrence_Error" 13 "HeaterTimerRecurrence_Spare_3" 12 "HeaterTimerRecurrence_Spare_2" 11 "HeaterTimerRecurrence_Spare_1" 10 "HeaterTimerRecurrence_Sundays" 9 "HeaterTimerRecurrence_Saturdays" 8 "HeaterTimerRecurrence_Fridays" 7 "HeaterTimerRecurrence_Thursdays" 6 "HeaterTimerRecurrence_Wednesdays" 5 "HeaterTimerRecurrence_Tuesdays" 4 "HeaterTimerRecurrence_Mondays" 3 "HeaterTimerRecurrence_Weekends" 2 "HeaterTimerRecurrence_AllWeekdays" 1 "HeaterTimerRecurrence_Daily" 0 "HeaterTimerRecurrence_None" ;
VAL_ 2432633752 EngineTimer_stat_Timer3StartDay_ 15 "HeaterTimerStartDay_NotAvailable" 14 "HeaterTimerStartDay_Error" 13 "HeaterTimerStartDay_Spare_05" 12 "HeaterTimerStartDay_Spare_04" 11 "HeaterTimerStartDay_Spare_03" 10 "HeaterTimerStartDay_Spare_02" 9 "HeaterTimerStartDay_Spare_01" 8 "HeaterTimerStartDay_Spare" 7 "HeaterTimerStartDay_Sunday" 6 "HeaterTimerStartDay_Saturday" 5 "HeaterTimerStartDay_Friday" 4 "HeaterTimerStartDay_Thursday" 3 "HeaterTimerStartDay_Wednesday" 2 "HeaterTimerStartDay_Tuesday" 1 "HeaterTimerStartDay_Monday" 0 "HeaterTimerStartDay_NotUsed" ;
VAL_ 2432633752 EngineTimer_stat_Timer2_Status_I 3 "ParkHeaterTimer_Status_NotAvailable" 2 "ParkHeaterTimer_Status_TimerDeleted" 1 "ParkHeaterTimer_Status_TimerNotActivated" 0 "ParkHeaterTimer_Status_TimerActivated" ;
VAL_ 2432633752 EngineTimer_stat_Timer1StartDay_ 15 "HeaterTimerStartDay_NotAvailable" 14 "HeaterTimerStartDay_Error" 13 "HeaterTimerStartDay_Spare_05" 12 "HeaterTimerStartDay_Spare_04" 11 "HeaterTimerStartDay_Spare_03" 10 "HeaterTimerStartDay_Spare_02" 9 "HeaterTimerStartDay_Spare_01" 8 "HeaterTimerStartDay_Spare" 7 "HeaterTimerStartDay_Sunday" 6 "HeaterTimerStartDay_Saturday" 5 "HeaterTimerStartDay_Friday" 4 "HeaterTimerStartDay_Thursday" 3 "HeaterTimerStartDay_Wednesday" 2 "HeaterTimerStartDay_Tuesday" 1 "HeaterTimerStartDay_Monday" 0 "HeaterTimerStartDay_NotUsed" ;
VAL_ 2432633752 EngineTimer_stat_Timer3_Status_I 3 "ParkHeaterTimer_Status_NotAvailable" 2 "ParkHeaterTimer_Status_TimerDeleted" 1 "ParkHeaterTimer_Status_TimerNotActivated" 0 "ParkHeaterTimer_Status_TimerActivated" ;
VAL_ 2432633752 EngineTimer_stat_Timer3Recurr_IS 15 "HeaterTimerRecurrence_NotAvailable" 14 "HeaterTimerRecurrence_Error" 13 "HeaterTimerRecurrence_Spare_3" 12 "HeaterTimerRecurrence_Spare_2" 11 "HeaterTimerRecurrence_Spare_1" 10 "HeaterTimerRecurrence_Sundays" 9 "HeaterTimerRecurrence_Saturdays" 8 "HeaterTimerRecurrence_Fridays" 7 "HeaterTimerRecurrence_Thursdays" 6 "HeaterTimerRecurrence_Wednesdays" 5 "HeaterTimerRecurrence_Tuesdays" 4 "HeaterTimerRecurrence_Mondays" 3 "HeaterTimerRecurrence_Weekends" 2 "HeaterTimerRecurrence_AllWeekdays" 1 "HeaterTimerRecurrence_Daily" 0 "HeaterTimerRecurrence_None" ;
VAL_ 2432633752 EngineTimer_stat_Timer1_Status_I 3 "ParkHeaterTimer_Status_NotAvailable" 2 "ParkHeaterTimer_Status_TimerDeleted" 1 "ParkHeaterTimer_Status_TimerNotActivated" 0 "ParkHeaterTimer_Status_TimerActivated" ;
VAL_ 2432637336 AQSmodeIndication_Cmd_ISig_5 3 "AQSMode_NotAvailable" 2 "AQSMode_Error" 1 "AQSMode_Auto" 0 "AQSMode_OFF" ;
VAL_ 2432637336 WindscreenDefrostInd_cmd_ISig_5 1 "IndicationCmd_ONLEDActivated" 0 "IndicationCmd_OFFLEDNotActivated" ;
VAL_ 2432637336 AutoBlowerLevelIndication_Cmd_IS 7 "AutoBlowerLevel_NotAvailable" 6 "AutoBlowerLevel_Error" 5 "AutoBlowerLevel_Spare_02" 4 "AutoBlowerLevel_Spare_01" 3 "AutoBlowerLevel_Spare" 2 "AutoBlowerLevel_Low" 1 "AutoBlowerLevel_Normal" 0 "AutoBlowerLevel_High" ;
VAL_ 2432637336 PHMaintenanceService_stat_ISig_5 3 "PHMaintenanceService_stat_NotAvailable" 2 "PHMaintenanceService_stat_Error" 1 "PHMaintenanceService_stat_PHServiceNeeded" 0 "PHMaintenanceService_stat_NoPHServiceNeeded" ;
VAL_ 2432637336 MemoDisplayIndication_Cmd_ISig_5 7 "Memo_Status_NotAvailable" 6 "Memo_Status_Error" 5 "Memo_Status_Spare_01" 4 "Memo_Status_Spare" 3 "Memo_Status_AirDistributionRecall" 2 "Memo_Status_AirDistributionMemorized" 1 "Memo_Status_NoAirDistributionMemorized" 0 "Memo_Status_OFF" ;
VAL_ 2432637336 TemperatureRqstIndication_cmd_IS 31 "TemperatureRqstIndication_cmd_NotAvailable" 30 "TemperatureRqstIndication_cmd_Error" 29 "TemperatureRqstIndication_cmd_Spare_01" 28 "TemperatureRqstIndication_cmd_Spare" 27 "TemperatureRqstIndication_cmd_Max" 26 "TemperatureRqstIndication_cmd_29C" 25 "TemperatureRqstIndication_cmd_28C" 24 "TemperatureRqstIndication_cmd_27C" 23 "TemperatureRqstIndication_cmd_26C" 22 "TemperatureRqstIndication_cmd_25_5C" 21 "TemperatureRqstIndication_cmd_25C" 20 "TemperatureRqstIndication_cmd_24_5C" 19 "TemperatureRqstIndication_cmd_24C" 18 "TemperatureRqstIndication_cmd_23_5C" 17 "TemperatureRqstIndication_cmd_23C" 16 "TemperatureRqstIndication_cmd_22_5C" 15 "TemperatureRqstIndication_cmd_22C" 14 "TemperatureRqstIndication_cmd_21_5C" 13 "TemperatureRqstIndication_cmd_21C" 12 "TemperatureRqstIndication_cmd_20_5C" 11 "TemperatureRqstIndication_cmd_20C" 10 "TemperatureRqstIndication_cmd_19_5C" 9 "TemperatureRqstIndication_cmd_19C" 8 "TemperatureRqstIndication_cmd_18_5C" 7 "TemperatureRqstIndication_cmd_18C" 6 "TemperatureRqstIndication_cmd_17_5C" 5 "TemperatureRqstIndication_cmd_17C" 4 "TemperatureRqstIndication_cmd_16_5C" 3 "TemperatureRqstIndication_cmd_16C" 2 "TemperatureRqstIndication_cmd_15C" 1 "TemperatureRqstIndication_cmd_Min" 0 "TemperatureRqstIndication_cmd_NoTempDisplayed" ;
VAL_ 2432637336 Area_9level_Indication_cmd_ISig_ 15 "Area_9Level_NotAvailable" 14 "Area_9Level_Error" 13 "Area_9Level_Spare_3" 12 "Area_9Level_Spare_2" 11 "Area_9Level_NoAirDistibutionSegmentDisplayed" 10 "Area_9Level_AllClosed" 9 "Area_9Level_UP1_FRONT1_DOWN1" 8 "Area_9Level_UP0_FRONT1_DOWN2" 7 "Area_9Level_UP0_FRONT2_DOWN1" 6 "Area_9Level_UP2_FRONT0_DOWN1" 5 "Area_9Level_UP2_FRONT1_DOWN0" 4 "Area_9Level_UP1_FRONT0_DOWN2" 3 "Area_9Level_UP1_FRONT2_DOWN0" 2 "Area_9Level_UP0_FRONT0_DOWN3" 1 "Area_9Level_UP0_FRONT3_DOWN0" 0 "Area_9Level_UP3_FRONT0_DOWN0" ;
VAL_ 2432637336 MirrorHeatNormModeBtn_stat_ISig_ 3 "PushButtonStatus_NotAvailable" 2 "PushButtonStatus_Error" 1 "PushButtonStatus_Pushed" 0 "PushButtonStatus_Neutral" ;
VAL_ 2432637336 AutoDefogIndication_Cmd_ISig_5 7 "AutoDefogmode_NotAvailable" 6 "AutoDefogmode_Error" 5 "AutoDefogmode_Spare_01" 4 "AutoDefogmode_Spare" 3 "AutoDefogmode_Moderate" 2 "AutoDefogmode_Normal" 1 "AutoDefogmode_Sensitive" 0 "AutoDefogmode_OFF" ;
VAL_ 2432637336 AutoMode_IndicationCmd_ISig_5 1 "IndicationCmd_ONLEDActivated" 0 "IndicationCmd_OFFLEDNotActivated" ;
VAL_ 2432637336 ACdisplayIndication_Cmd_ISig_5 7 "ACMode_NotAvailable" 6 "ACMode_Error" 5 "ACMode_Spare_01" 4 "ACMode_Spare" 3 "ACMode_ExtraDryCabAir" 2 "ACMode_HumidCabAir" 1 "ACMode_Standard" 0 "ACMode_Economy" ;
SIG_GROUP_ 2432663360 PHTimerGUIEvCmd_sg_ISig_5 1 : PHTimerGUIEvCmd_Timer1StartDay_I PHTimerGUIEvCmd_Timer1Recur_ISig PHTimerGUIEvCmd_Timer1Temp_ISig_ PHTimerGUIEvCmd_PhTimer3_cmd_ISi PHTimerGUIEvCmd_Timer2StartDay_I PHTimerGUIEvCmd_Timer3StartDay_I PHTimerGUIEvCmd_Timer2Hours_ISig PHTimerGUIEvCmd_Timer1Duration_I PHTimerGUIEvCmd_Timer3Hours_ISig PHTimerGUIEvCmd_PhTimer1_cmd_ISi PHTimerGUIEvCmd_PhTimer2_cmd_ISi PHTimerGUIEvCmd_Timer2Recur_ISig PHTimerGUIEvCmd_Timer3Recur_ISig PHTimerGUIEvCmd_Timer2Minutes_IS PHTimerGUIEvCmd_Timer2Temp_ISig_ PHTimerGUIEvCmd_Timer1Hours_ISig PHTimerGUIEvCmd_Timer3Temp_ISig_ PHTimerGUIEvCmd_Timer3Minutes_IS PHTimerGUIEvCmd_Timer1Minutes_IS;
SIG_GROUP_ 2432657472 EngTimerGUIEvCmd_sg_ISig_5 1 : EngTimerGUIEvCmd_Timer3Hours_ISi EngTimerGUIEvCmd_EhTimer3_cmd_IS EngTimerGUIEvCmd_Timer2Recur_ISi EngTimerGUIEvCmd_EhTimer1_cmd_IS EngTimerGUIEvCmd_Timer1StartDay_ EngTimerGUIEvCmd_Timer3Recur_ISi EngTimerGUIEvCmd_Timer2Hours_ISi EngTimerGUIEvCmd_Timer2StartDay_ EngTimerGUIEvCmd_Timer1Minutes_I EngTimerGUIEvCmd_Timer1Hours_ISi EngTimerGUIEvCmd_Timer2Minutes_I EngTimerGUIEvCmd_Timer1Recur_ISi EngTimerGUIEvCmd_Timer3StartDay_ EngTimerGUIEvCmd_EhTimer2_cmd_IS EngTimerGUIEvCmd_Timer3Minutes_I;
SIG_GROUP_ 2432651584 BunkH2PHTimer_rqst_sg 1 : BunkH2PHTimer_rqst_StartTimeMin BunkH2PHTimer_rqst_DurnTimeMin BunkH2PHTimer_rqst_StartTimeHr BunkH2PHTimer_rqst_DurnTimeHr BunkH2PHTimer_rqst_Timer_cmd;
SIG_GROUP_ 2431745856 IntLghtModeInd_cmd_sg 1 : IntLghtModeInd_cmd_EventFlag IntLghtModeInd_cmd_IL_Mode;
SIG_GROUP_ 2432640664 PHTimer3_stat_sg_ISig_5 1 : PHTimer3_stat_Temp_ISig_5 PHTimer3_stat_Hours_ISig_5 PHTimer3_stat_Status_ISig_5 PHTimer3_stat_Minutes_ISig_5 PHTimer3_stat_Recurrence_ISig_5 PHTimer3_stat_StartDay_ISig_5;
SIG_GROUP_ 2432640664 PHTimer2_stat_sg_ISig_5 1 : PHTimer2_stat_Recurrence_ISig_5 PHTimer2_stat_Hours_ISig_5 PHTimer2_stat_StartDay_ISig_5 PHTimer2_stat_Temp_ISig_5 PHTimer2_stat_Status_ISig_5 PHTimer2_stat_Minutes_ISig_5;
SIG_GROUP_ 2432644760 PHTimer1_stat_sg_ISig_5 1 : PHTimer1_stat_Minutes_ISig_5 PHTimer1_stat_Status_ISig_5 PHTimer1_stat_StartDay_ISig_5 PHTimer1_stat_Duration_ISig_5 PHTimer1_stat_Temp_ISig_5 PHTimer1_stat_Recurrence_ISig_5 PHTimer1_stat_Hours_ISig_5;
SIG_GROUP_ 2432639640 PHTimer_rqst_sg_ISig_5 1 : PHTimer_rqst_SetAlarmOper_ISig_5 PHTimer_rqst_Hours_ISig_5 PHTimer_rqst_Minutes_ISig_5 PHTimer_rqst_DayOfWeekRq_ISig_5;
SIG_GROUP_ 2432633752 EngineTimer_stat_sg_ISig_5 1 : EngineTimer_stat_Timer2StartDay_ EngineTimer_stat_Timer1Recurr_IS EngineTimer_stat_Timer3Hours_ISi EngineTimer_stat_Timer2Minutes_I EngineTimer_stat_Timer2Recurr_IS EngineTimer_stat_Timer1Hours_ISi EngineTimer_stat_Timer3Minutes_I EngineTimer_stat_Timer1Minutes_I EngineTimer_stat_Timer3StartDay_ EngineTimer_stat_Timer2_Status_I EngineTimer_stat_Timer1StartDay_ EngineTimer_stat_Timer2Hours_ISi EngineTimer_stat_Timer3_Status_I EngineTimer_stat_Timer3Recurr_IS EngineTimer_stat_Timer1_Status_I;
